VERSION ""

NS_ :

BS_:

BU_: TBOX GW

BO_ 374 EPS_0x176: 8 GW
 SG_ EPS_Checksum_0x176 : 7|8@0+ (1,0) [0|255] "" TBOX
 SG_ EPS_LKA_TJA_ResponseTorque : 18|11@0+ (0.01,-10.24) [-10.24|10.23] "Nm" TBOX
 SG_ EPS_LKA_TJA_ResponseTorqueValid : 19|1@0+ (1,0) [0|1] "" TBOX
 SG_ EPS_LKA_TJA_ControlStatus : 33|2@0+ (1,0) [0|3] "" TBOX
 SG_ Rolling_counter_0x176 : 59|4@0+ (1,0) [0|15] "" TBOX

BO_ 375 EPS_0x177_APS: 8 GW
 SG_ Checksum_0x177 : 7|8@0+ (1,0) [0|255] "" TBOX
 SG_ EPS_EPSAPASts : 19|4@0+ (1,0) [0|15] "" TBOX
 SG_ EPS_EPSAPAInh : 31|8@0+ (1,0) [0|255] "" TBOX
 SG_ Rolling_counter_0x177 : 59|4@0+ (1,0) [0|15] "" TBOX

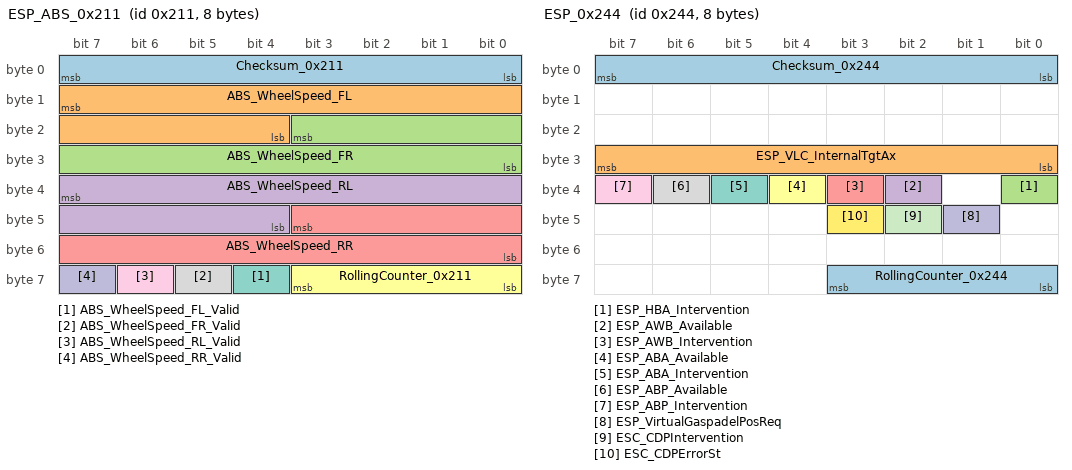
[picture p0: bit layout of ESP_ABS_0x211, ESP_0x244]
BO_ 529 ESP_ABS_0x211: 8 GW
 SG_ Checksum_0x211 : 7|8@0+ (1,0) [0|255] "" TBOX
 SG_ ABS_WheelSpeed_FL : 15|12@0+ (0.05625,0) [0|230.2875] "kph" TBOX
 SG_ ABS_WheelSpeed_FR : 19|12@0+ (0.05625,0) [0|230.2875] "kph" TBOX
 SG_ ABS_WheelSpeed_RL : 39|12@0+ (0.05625,0) [0|230.2875] "kph" TBOX
 SG_ ABS_WheelSpeed_RR : 43|12@0+ (0.05625,0) [0|230.2875] "kph" TBOX
 SG_ RollingCounter_0x211 : 59|4@0+ (1,0) [0|15] "" TBOX
 SG_ ABS_WheelSpeed_FL_Valid : 60|1@0+ (1,0) [0|1] "" TBOX
 SG_ ABS_WheelSpeed_FR_Valid : 61|1@0+ (1,0) [0|1] "" TBOX
 SG_ ABS_WheelSpeed_RL_Valid : 62|1@0+ (1,0) [0|1] "" TBOX
 SG_ ABS_WheelSpeed_RR_Valid : 63|1@0+ (1,0) [0|1] "" TBOX

BO_ 580 ESP_0x244: 8 GW
 SG_ Checksum_0x244 : 7|8@0+ (1,0) [0|255] "" TBOX
 SG_ ESP_VLC_InternalTgtAx : 31|8@0+ (0.05,-7) [-7|5.75] "m/s2" TBOX
 SG_ ESP_HBA_Intervention : 32|1@0+ (1,0) [0|1] "" TBOX
 SG_ ESP_AWB_Available : 34|1@0+ (1,0) [0|1] "" TBOX
 SG_ ESP_AWB_Intervention : 35|1@0+ (1,0) [0|1] "" TBOX
 SG_ ESP_ABA_Available : 36|1@0+ (1,0) [0|1] "" TBOX
 SG_ ESP_ABA_Intervention : 37|1@0+ (1,0) [0|1] "" TBOX
 SG_ ESP_ABP_Available : 38|1@0+ (1,0) [0|1] "" TBOX
 SG_ ESP_ABP_Intervention : 39|1@0+ (1,0) [0|1] "" TBOX
 SG_ ESP_VirtualGaspadelPosReq : 41|1@0+ (1,0) [0|1] "" TBOX
 SG_ ESC_CDPIntervention : 42|1@0+ (1,0) [0|1] "" TBOX
 SG_ ESC_CDPErrorSt : 43|1@0+ (1,0) [0|1] "" TBOX
 SG_ RollingCounter_0x244 : 59|4@0+ (1,0) [0|15] "" TBOX

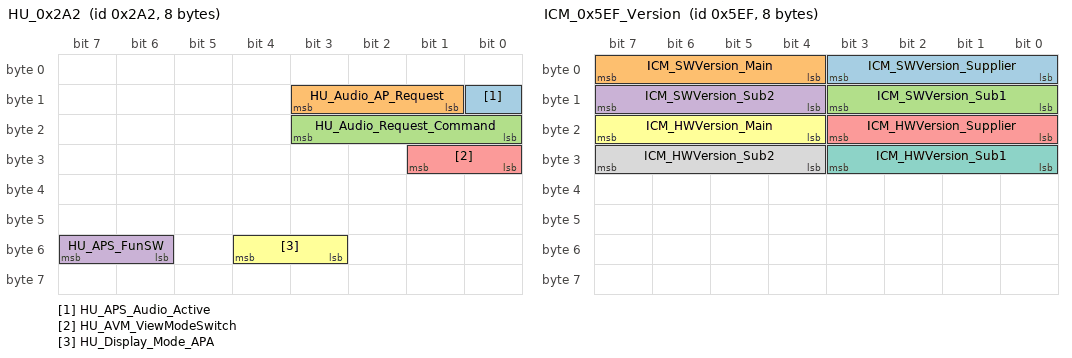
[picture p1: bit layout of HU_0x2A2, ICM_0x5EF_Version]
BO_ 674 HU_0x2A2: 8 GW
 SG_ HU_APS_Audio_Active : 8|1@0+ (1,0) [0|1] "" TBOX
 SG_ HU_Audio_AP_Request : 11|3@0+ (1,0) [0|7] "" TBOX
 SG_ HU_Audio_Request_Command : 19|4@0+ (1,0) [0|15] "" TBOX
 SG_ HU_APS_FunSW : 55|2@0+ (1,0) [0|3] "" TBOX
 SG_ HU_AVM_ViewModeSwitch : 25|2@0+ (1,0) [0|3] "" TBOX
 SG_ HU_Display_Mode_APA : 52|2@0+ (1,0) [0|3] "" TBOX

BO_ 608 EPS_0x260: 8 GW
 SG_ EPS_SafeLampRed : 0|1@0+ (1,0) [0|1] "" TBOX
 SG_ EPS_WarningLampYellow : 1|1@0+ (1,0) [0|1] "" TBOX
 SG_ EPS_DTCFlag : 2|1@0+ (1,0) [0|1] "" TBOX
 SG_ EPS_DriveModeSts : 4|2@0+ (1,0) [0|3] "" TBOX
 SG_ EPS_HU_DriveModeSetEn : 5|1@0+ (1,0) [0|1] "" TBOX

BO_ 1519 ICM_0x5EF_Version: 8 GW
 SG_ ICM_SWVersion_Supplier : 3|4@0+ (1,0) [0|15] "" TBOX
 SG_ ICM_SWVersion_Main : 7|4@0+ (1,0) [0|15] "" TBOX
 SG_ ICM_SWVersion_Sub1 : 11|4@0+ (1,0) [0|15] "" TBOX
 SG_ ICM_SWVersion_Sub2 : 15|4@0+ (1,0) [0|15] "" TBOX
 SG_ ICM_HWVersion_Supplier : 19|4@0+ (1,0) [0|15] "" TBOX
 SG_ ICM_HWVersion_Main : 23|4@0+ (1,0) [0|15] "" TBOX
 SG_ ICM_HWVersion_Sub1 : 27|4@0+ (1,0) [0|15] "" TBOX
 SG_ ICM_HWVersion_Sub2 : 31|4@0+ (1,0) [0|15] "" TBOX

BO_ 811 VBU_0x32B: 8 GW
 SG_ VBU_WakeUpRMCU : 7|1@0+ (1,0) [0|1] "" TBOX

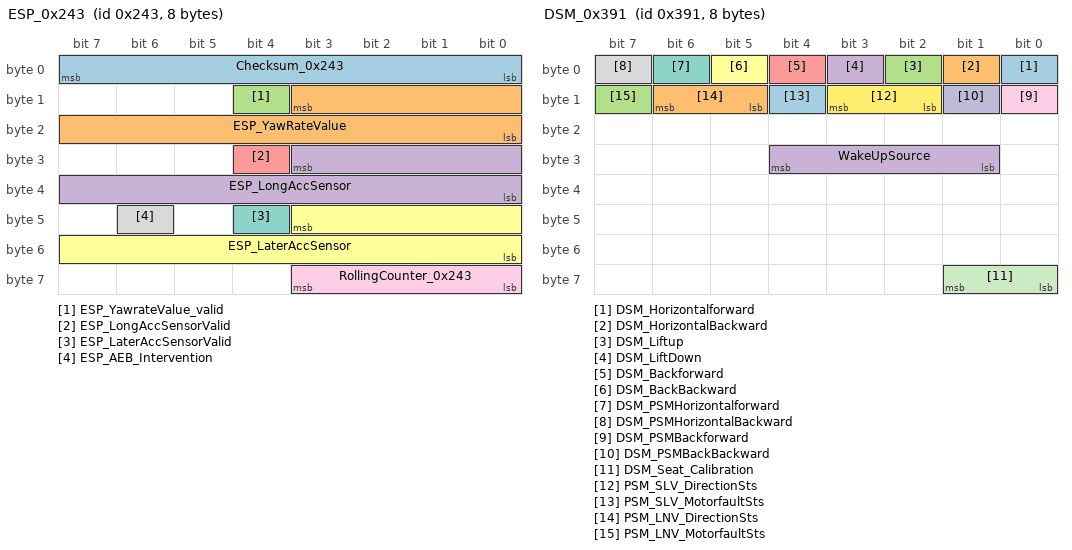
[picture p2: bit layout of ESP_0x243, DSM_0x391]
BO_ 579 ESP_0x243: 8 GW
 SG_ Checksum_0x243 : 7|8@0+ (1,0) [0|255] "" TBOX
 SG_ ESP_YawRateValue : 11|12@0+ (0.05,-75) [-75|75] "degps" TBOX
 SG_ ESP_YawrateValue_valid : 12|1@0+ (1,0) [0|1] "" TBOX
 SG_ ESP_LongAccSensor : 27|12@0+ (0.01,-20) [-20|20] "gee" TBOX
 SG_ ESP_LongAccSensorValid : 28|1@0+ (1,0) [0|1] "" TBOX
 SG_ ESP_LaterAccSensor : 43|12@0+ (0.01,-20) [-20|20] "gee" TBOX
 SG_ ESP_LaterAccSensorValid : 44|1@0+ (1,0) [0|1] "" TBOX
 SG_ ESP_AEB_Intervention : 46|1@0+ (1,0) [0|1] "" TBOX
 SG_ RollingCounter_0x243 : 59|4@0+ (1,0) [0|15] "" TBOX

BO_ 913 DSM_0x391: 8 GW
 SG_ DSM_Horizontalforward : 0|1@0+ (1,0) [0|1] "" TBOX
 SG_ DSM_HorizontalBackward : 1|1@0+ (1,0) [0|1] "" TBOX
 SG_ DSM_Liftup : 2|1@0+ (1,0) [0|1] "" TBOX
 SG_ DSM_LiftDown : 3|1@0+ (1,0) [0|1] "" TBOX
 SG_ DSM_Backforward : 4|1@0+ (1,0) [0|1] "" TBOX
 SG_ DSM_BackBackward : 5|1@0+ (1,0) [0|1] "" TBOX
 SG_ DSM_PSMHorizontalforward : 6|1@0+ (1,0) [0|1] "" TBOX
 SG_ DSM_PSMHorizontalBackward : 7|1@0+ (1,0) [0|1] "" TBOX
 SG_ DSM_PSMBackforward : 8|1@0+ (1,0) [0|1] "" TBOX
 SG_ DSM_PSMBackBackward : 9|1@0+ (1,0) [0|1] "" TBOX
 SG_ DSM_Seat_Calibration : 57|2@0+ (1,0) [0|3] "" TBOX
 SG_ PSM_SLV_DirectionSts : 11|2@0+ (1,0) [0|3] "" TBOX
 SG_ PSM_SLV_MotorfaultSts : 12|1@0+ (1,0) [0|1] "" TBOX
 SG_ PSM_LNV_DirectionSts : 14|2@0+ (1,0) [0|3] "" TBOX
 SG_ PSM_LNV_MotorfaultSts : 15|1@0+ (1,0) [0|1] "" TBOX
 SG_ WakeUpSource : 28|4@0+ (1,0) [0|15] "" TBOX

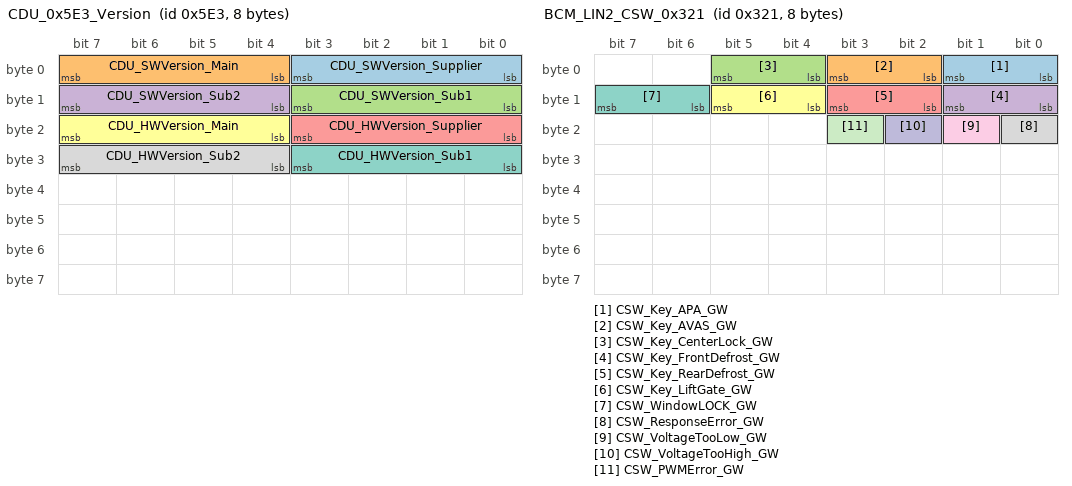
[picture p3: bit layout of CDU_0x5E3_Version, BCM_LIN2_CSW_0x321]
BO_ 1507 CDU_0x5E3_Version: 8 GW
 SG_ CDU_SWVersion_Supplier : 3|4@0+ (1,0) [0|15] "" TBOX
 SG_ CDU_SWVersion_Main : 7|4@0+ (1,0) [0|15] "" TBOX
 SG_ CDU_SWVersion_Sub1 : 11|4@0+ (1,0) [0|15] "" TBOX
 SG_ CDU_SWVersion_Sub2 : 15|4@0+ (1,0) [0|15] "" TBOX
 SG_ CDU_HWVersion_Supplier : 19|4@0+ (1,0) [0|15] "" TBOX
 SG_ CDU_HWVersion_Main : 23|4@0+ (1,0) [0|15] "" TBOX
 SG_ CDU_HWVersion_Sub1 : 27|4@0+ (1,0) [0|15] "" TBOX
 SG_ CDU_HWVersion_Sub2 : 31|4@0+ (1,0) [0|15] "" TBOX

BO_ 801 BCM_LIN2_CSW_0x321: 8 GW
 SG_ CSW_Key_APA_GW : 1|2@0+ (1,0) [0|3] "" TBOX
 SG_ CSW_Key_AVAS_GW : 3|2@0+ (1,0) [0|3] "" TBOX
 SG_ CSW_Key_CenterLock_GW : 5|2@0+ (1,0) [0|3] "" TBOX
 SG_ CSW_Key_FrontDefrost_GW : 9|2@0+ (1,0) [0|3] "" TBOX
 SG_ CSW_Key_RearDefrost_GW : 11|2@0+ (1,0) [0|3] "" TBOX
 SG_ CSW_Key_LiftGate_GW : 13|2@0+ (1,0) [0|3] "" TBOX
 SG_ CSW_WindowLOCK_GW : 15|2@0+ (1,0) [0|3] "" TBOX
 SG_ CSW_ResponseError_GW : 16|1@0+ (1,0) [0|1] "" TBOX
 SG_ CSW_VoltageTooLow_GW : 17|1@0+ (1,0) [0|1] "" TBOX
 SG_ CSW_VoltageTooHigh_GW : 18|1@0+ (1,0) [0|1] "" TBOX
 SG_ CSW_PWMError_GW : 19|1@0+ (1,0) [0|1] "" TBOX

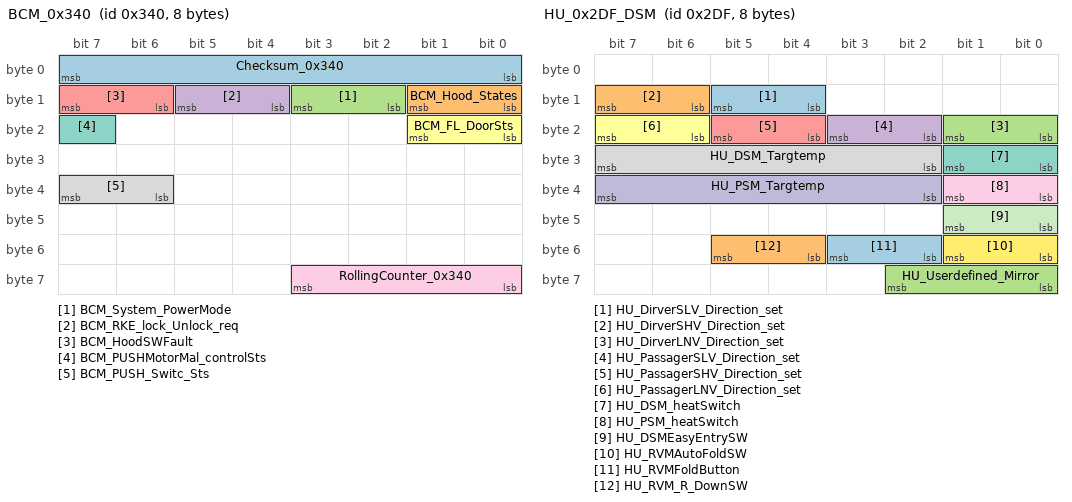
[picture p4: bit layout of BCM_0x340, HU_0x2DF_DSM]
BO_ 832 BCM_0x340: 8 GW
 SG_ Checksum_0x340 : 7|8@0+ (1,0) [0|255] "" TBOX
 SG_ BCM_Hood_States : 9|2@0+ (1,0) [0|3] "" TBOX
 SG_ BCM_System_PowerMode : 11|2@0+ (1,0) [0|3] "" TBOX
 SG_ BCM_RKE_lock_Unlock_req : 13|2@0+ (1,0) [0|3] "" TBOX
 SG_ BCM_HoodSWFault : 15|2@0+ (1,0) [0|3] "" TBOX
 SG_ BCM_FL_DoorSts : 17|2@0+ (1,0) [0|3] "" TBOX
 SG_ BCM_PUSHMotorMal_controlSts : 23|1@0+ (1,0) [0|1] "" TBOX
 SG_ BCM_PUSH_Switc_Sts : 39|2@0+ (1,0) [0|3] "" TBOX
 SG_ RollingCounter_0x340 : 59|4@0+ (1,0) [0|15] "" TBOX

BO_ 64 BCM_PEPS_0x40: 8 GW
 SG_ PEPS_RKECommand : 3|4@0+ (1,0) [0|15] "" TBOX
 SG_ PEPS_TrunkReleaseReq : 4|1@0+ (1,0) [0|1] "" TBOX
 SG_ PEPS_DoorUnlockReq : 6|2@0+ (1,0) [0|3] "" TBOX
 SG_ PEPS_DoorlockReq : 9|2@0+ (1,0) [0|3] "" TBOX

BO_ 735 HU_0x2DF_DSM: 8 GW
 SG_ HU_DirverSLV_Direction_set : 13|2@0+ (1,0) [0|3] "" TBOX
 SG_ HU_DirverSHV_Direction_set : 15|2@0+ (1,0) [0|3] "" TBOX
 SG_ HU_DirverLNV_Direction_set : 17|2@0+ (1,0) [0|3] "" TBOX
 SG_ HU_PassagerSLV_Direction_set : 19|2@0+ (1,0) [0|3] "" TBOX
 SG_ HU_PassagerSHV_Direction_set : 21|2@0+ (1,0) [0|3] "" TBOX
 SG_ HU_PassagerLNV_Direction_set : 23|2@0+ (1,0) [0|3] "" TBOX
 SG_ HU_DSM_heatSwitch : 25|2@0+ (1,0) [0|3] "" TBOX
 SG_ HU_DSM_Targtemp : 31|6@0+ (1,0) [34|42] "℃" TBOX
 SG_ HU_PSM_heatSwitch : 33|2@0+ (1,0) [0|3] "" TBOX
 SG_ HU_PSM_Targtemp : 39|6@0+ (1,0) [34|42] "℃" TBOX
 SG_ HU_DSMEasyEntrySW : 41|2@0+ (1,0) [0|3] "" TBOX
 SG_ HU_RVMAutoFoldSW : 49|2@0+ (1,0) [0|3] "" TBOX
 SG_ HU_RVMFoldButton : 51|2@0+ (1,0) [0|3] "" TBOX
 SG_ HU_RVM_R_DownSW : 53|2@0+ (1,0) [0|3] "" TBOX
 SG_ HU_Userdefined_Mirror : 58|3@0+ (1,0) [0|7] "" TBOX

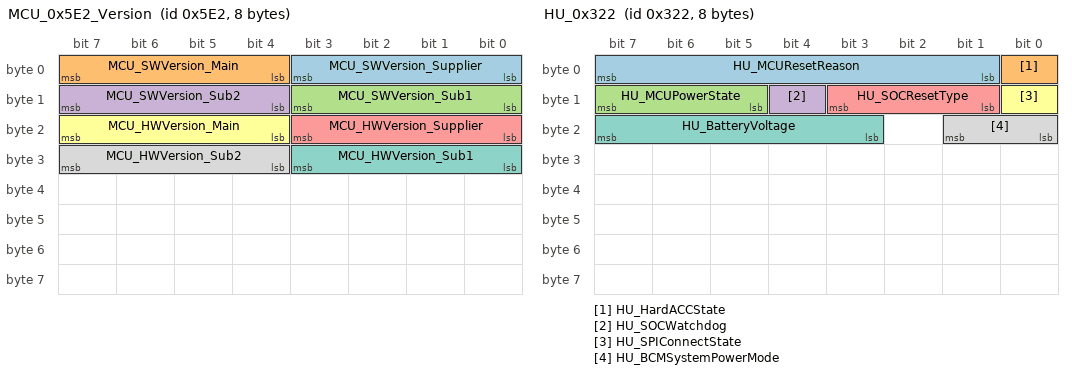
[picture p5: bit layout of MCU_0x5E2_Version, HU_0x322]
BO_ 1506 MCU_0x5E2_Version: 8 GW
 SG_ MCU_SWVersion_Supplier : 3|4@0+ (1,0) [0|15] "" TBOX
 SG_ MCU_SWVersion_Main : 7|4@0+ (1,0) [0|15] "" TBOX
 SG_ MCU_SWVersion_Sub1 : 11|4@0+ (1,0) [0|15] "" TBOX
 SG_ MCU_SWVersion_Sub2 : 15|4@0+ (1,0) [0|15] "" TBOX
 SG_ MCU_HWVersion_Supplier : 19|4@0+ (1,0) [0|15] "" TBOX
 SG_ MCU_HWVersion_Main : 23|4@0+ (1,0) [0|15] "" TBOX
 SG_ MCU_HWVersion_Sub1 : 27|4@0+ (1,0) [0|15] "" TBOX
 SG_ MCU_HWVersion_Sub2 : 31|4@0+ (1,0) [0|15] "" TBOX

BO_ 802 HU_0x322: 8 GW
 SG_ HU_MCUResetReason : 7|7@0+ (1,0) [0|127] "" TBOX
 SG_ HU_HardACCState : 0|1@0+ (1,0) [0|1] "" TBOX
 SG_ HU_MCUPowerState : 15|3@0+ (1,0) [0|7] "" TBOX
 SG_ HU_SOCWatchdog : 12|1@0+ (1,0) [0|1] "" TBOX
 SG_ HU_SOCResetType : 11|3@0+ (1,0) [0|3] "" TBOX
 SG_ HU_SPIConnectState : 8|1@0+ (1,0) [0|1] "" TBOX
 SG_ HU_BatteryVoltage : 23|5@0+ (1,0) [0|25] "V" TBOX
 SG_ HU_BCMSystemPowerMode : 17|2@0+ (1,0) [0|3] "" TBOX

BO_ 792 TPCV1_0x318: 8 GW
 SG_ TPCV1_Feedback_sts : 1|2@0+ (1,0) [0|3] "" TBOX
 SG_ TPCV1_Feedback_opening_sts : 7|6@0+ (2.5,0) [0|100] "" TBOX

BO_ 793 TPCV2_0x319: 8 GW
 SG_ TPCV2_Feedback_sts : 17|2@0+ (1,0) [0|3] "" TBOX
 SG_ TPCV2_Feedback_opening_Sts : 23|6@0+ (2.5,0) [0|100] "" TBOX

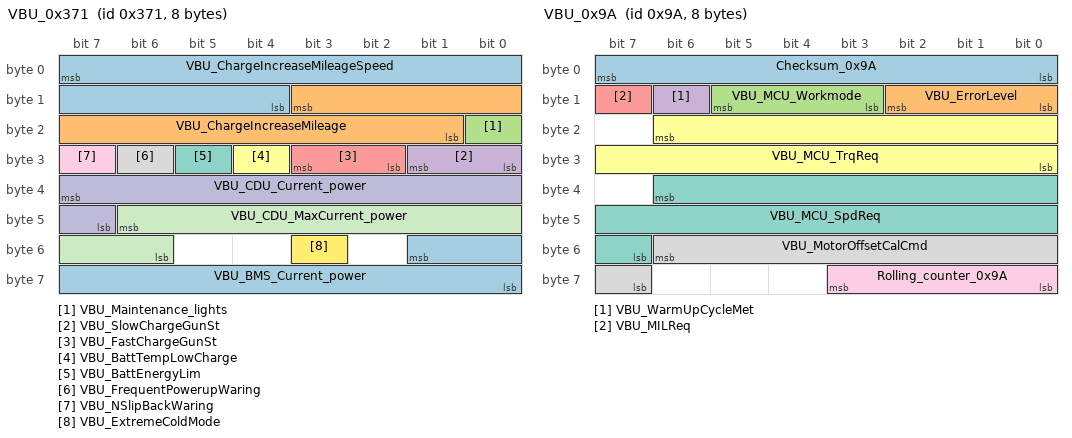
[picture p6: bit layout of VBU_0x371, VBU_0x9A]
BO_ 881 VBU_0x371: 8 GW
 SG_ VBU_ChargeIncreaseMileageSpeed : 7|12@0+ (1,0) [0|2046] "kmph" TBOX
 SG_ VBU_ChargeIncreaseMileage : 11|11@0+ (1,0) [0|2046] "km" TBOX
 SG_ VBU_Maintenance_lights : 16|1@0+ (1,0) [0|1] "" TBOX
 SG_ VBU_SlowChargeGunSt : 25|2@0+ (1,0) [0|3] "" TBOX
 SG_ VBU_FastChargeGunSt : 27|2@0+ (1,0) [0|3] "" TBOX
 SG_ VBU_BattTempLowCharge : 28|1@0+ (1,0) [0|1] "" TBOX
 SG_ VBU_BattEnergyLim : 29|1@0+ (1,0) [0|1] "" TBOX
 SG_ VBU_FrequentPowerupWaring : 30|1@0+ (1,0) [0|1] "" TBOX
 SG_ VBU_NSlipBackWaring : 31|1@0+ (1,0) [0|1] "" TBOX
 SG_ VBU_CDU_Current_power : 39|9@0+ (20,0) [0|7000] "W" TBOX
 SG_ VBU_CDU_MaxCurrent_power : 46|9@0+ (20,0) [0|7000] "W" TBOX
 SG_ VBU_ExtremeColdMode : 51|1@0+ (1,0) [0|1] "" TBOX
 SG_ VBU_BMS_Current_power : 49|10@0+ (0.5,-250) [-250|250] "kW" TBOX

BO_ 154 VBU_0x9A: 8 GW
 SG_ Checksum_0x9A : 7|8@0+ (1,0) [0|255] "" TBOX
 SG_ VBU_ErrorLevel : 10|3@0+ (1,0) [0|7] "" TBOX
 SG_ VBU_MCU_Workmode : 13|3@0+ (1,0) [0|7] "" TBOX
 SG_ VBU_WarmUpCycleMet : 14|1@0+ (1,0) [0|1] "" TBOX
 SG_ VBU_MILReq : 15|1@0+ (1,0) [0|1] "" TBOX
 SG_ VBU_MCU_TrqReq : 22|15@0+ (0.1,-1000) [-1000|1000] "NM" TBOX
 SG_ VBU_MCU_SpdReq : 38|16@0+ (1,-32767) [-32767|32768] "rpm" TBOX
 SG_ VBU_MotorOffsetCalCmd : 54|8@0+ (1,0) [0|255] "" TBOX
 SG_ Rolling_counter_0x9A : 59|4@0+ (1,0) [0|15] "" TBOX

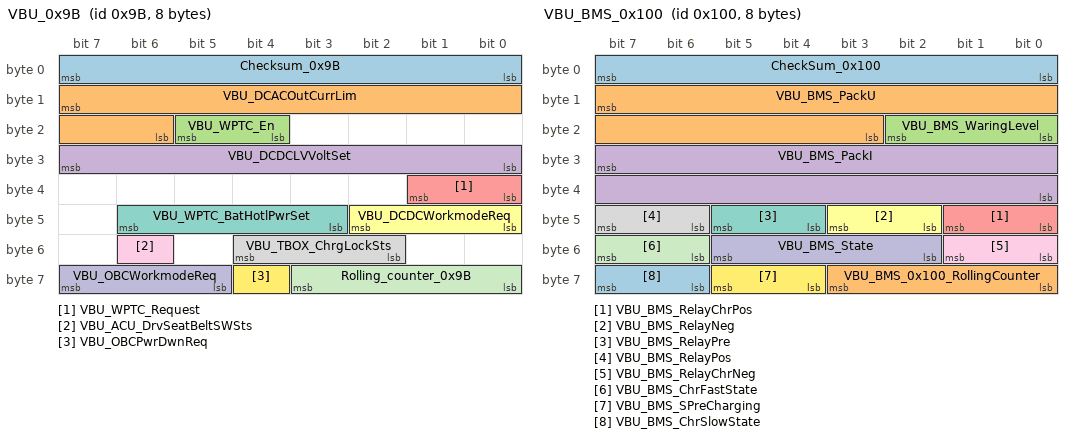
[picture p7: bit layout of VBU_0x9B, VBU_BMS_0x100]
BO_ 155 VBU_0x9B: 8 GW
 SG_ Checksum_0x9B : 7|8@0+ (1,0) [0|255] "" TBOX
 SG_ VBU_DCACOutCurrLim : 15|10@0+ (0.1,0) [0|100] "A" TBOX
 SG_ VBU_WPTC_En : 21|2@0+ (1,0) [0|3] "" TBOX
 SG_ VBU_DCDCLVVoltSet : 31|8@0+ (0.1,0) [12|16] "V" TBOX
 SG_ VBU_WPTC_Request : 33|2@0+ (1,0) [0|3] "" TBOX
 SG_ VBU_DCDCWorkmodeReq : 42|3@0+ (1,0) [0|7] "" TBOX
 SG_ VBU_WPTC_BatHotlPwrSet : 46|4@0+ (1,0) [0|15] "" TBOX
 SG_ VBU_TBOX_ChrgLockSts : 52|3@0+ (1,0) [0|7] "" TBOX
 SG_ VBU_ACU_DrvSeatBeltSWSts : 54|1@0+ (1,0) [0|1] "" TBOX
 SG_ VBU_OBCWorkmodeReq : 63|3@0+ (1,0) [0|7] "" TBOX
 SG_ Rolling_counter_0x9B : 59|4@0+ (1,0) [0|15] "" TBOX
 SG_ VBU_OBCPwrDwnReq : 60|1@0+ (1,0) [0|1] "" TBOX

BO_ 156 VBU_0x9C: 8 GW
 SG_ Checksum_0x9C : 7|8@0+ (1,0) [0|255] "" TBOX
 SG_ VBU_Cruise_Sts : 9|2@0+ (1,0) [0|3] "" TBOX
 SG_ VBU_DriveInhibitAlarm : 10|1@0+ (1,0) [0|1] "" TBOX
 SG_ VBU_HU_ChrgLockSts : 15|3@0+ (1,0) [0|7] "" TBOX
 SG_ VBU_CCS_SpeedArm : 23|8@0+ (1,0) [0|200] "kmph" TBOX
 SG_ VBU_SpeedLimitSWSts : 25|1@0+ (1,0) [0|1] "" TBOX
 SG_ VBU_DMS_Status : 27|2@0+ (1,0) [0|3] "" TBOX
 SG_ VBU_DMS_SWStatus : 28|1@0+ (1,0) [0|1] "" TBOX
 SG_ VBU_IdleModeAct : 29|1@0+ (1,0) [0|1] "" TBOX
 SG_ VBU_AuthSts : 31|2@0+ (1,0) [0|3] "" TBOX
 SG_ VBU_LimitSpeed : 39|8@0+ (1,0) [0|200] "" TBOX
 SG_ VBU_LimitSpeedAlarm_L : 40|1@0+ (1,0) [0|1] "" TBOX
 SG_ VBU_LimitSpeedAlarm_V : 41|1@0+ (1,0) [0|1] "" TBOX
 SG_ VBU_TPCV1Control : 47|6@0+ (2.5,0) [0|100] "" TBOX
 SG_ VBU_Cruise_Warning : 49|2@0+ (1,0) [0|3] "" TBOX
 SG_ VBU_TPCV2Control : 55|6@0+ (2.5,0) [0|100] "" TBOX
 SG_ Rolling_counter_0x9C : 59|4@0+ (1,0) [0|15] "" TBOX
 SG_ VBU_ElockSts : 63|4@0+ (1,0) [0|15] "" TBOX

BO_ 157 VBU_0x9D: 8 GW
 SG_ VBU_AC_ComfortEAC_En : 0|1@0+ (1,0) [0|1] "" TBOX
 SG_ VBU_AC_BatCoolEAC_En : 1|1@0+ (1,0) [0|1] "" TBOX
 SG_ VBU_AC_APTC_En : 2|1@0+ (1,0) [0|1] "" TBOX
 SG_ VBU_RefuelingInfo : 5|3@0+ (1,0) [0|7] "" TBOX
 SG_ VBU_HU_Towmode : 6|1@0+ (1,0) [0|1] "" TBOX
 SG_ VBU_HU_TowmodeSetEn : 7|1@0+ (1,0) [0|1] "" TBOX
 SG_ VBU_AC_APTCPwrSet : 14|7@0+ (0.1,0) [0|12.7] "kW" TBOX
 SG_ VBU_BCM_TowModewarning : 15|1@0+ (1,0) [0|1] "" TBOX
 SG_ VBU_AC_EACPwrSet : 22|7@0+ (0.1,0) [0|12.7] "kW" TBOX
 SG_ VBU_FanPWMSts : 30|7@0+ (1,0) [0|100] "percent" TBOX
 SG_ VBU_RemoteACFeedback : 38|4@0+ (1,0) [0|15] "" TBOX
 SG_ VBU_ComfortPumpError : 40|1@0+ (1,0) [0|1] "" TBOX
 SG_ VBU_ENGWVControl : 41|1@0+ (1,0) [0|1] "" TBOX
 SG_ VBU_WPTCWVControl : 42|1@0+ (1,0) [0|1] "" TBOX
 SG_ VBU_ENGWVFault : 43|1@0+ (1,0) [0|1] "" TBOX
 SG_ VBU_WPTCWVFault : 44|1@0+ (1,0) [0|1] "" TBOX
 SG_ VBU_FanSts : 45|1@0+ (1,0) [0|1] "" TBOX
 SG_ VBU_RefuelingSysErrorRemind : 47|1@0+ (1,0) [0|1] "" TBOX
 SG_ VBU_12VbatterySOHLow : 48|1@0+ (1,0) [0|1] "" TBOX
 SG_ VBU_LVSmartChrg_Status : 50|2@0+ (1,0) [0|3] "" TBOX
 SG_ VBU_ChargeLight : 54|4@0+ (1,0) [0|15] "" TBOX
 SG_ VBU_AC_ThermalReqLvl : 62|4@0+ (1,0) [0|15] "" TBOX
 SG_ VBU_VehicleModel : 58|3@0+ (1,0) [0|7] "" TBOX

BO_ 256 VBU_BMS_0x100: 8 GW
 SG_ CheckSum_0x100 : 7|8@0+ (1,0) [0|255] "" TBOX
 SG_ VBU_BMS_PackU : 15|13@0+ (0.1,0) [0|800] "V" TBOX
 SG_ VBU_BMS_WaringLevel : 18|3@0+ (1,0) [0|7] "" TBOX
 SG_ VBU_BMS_PackI : 31|16@0+ (0.1,-1000) [-1000|1000] "A" TBOX
 SG_ VBU_BMS_RelayChrPos : 41|2@0+ (1,0) [0|3] "" TBOX
 SG_ VBU_BMS_RelayNeg : 43|2@0+ (1,0) [0|3] "" TBOX
 SG_ VBU_BMS_RelayPre : 45|2@0+ (1,0) [0|3] "" TBOX
 SG_ VBU_BMS_RelayPos : 47|2@0+ (1,0) [0|3] "" TBOX
 SG_ VBU_BMS_RelayChrNeg : 49|2@0+ (1,0) [0|3] "" TBOX
 SG_ VBU_BMS_State : 53|4@0+ (1,0) [0|15] "" TBOX
 SG_ VBU_BMS_ChrFastState : 55|2@0+ (1,0) [0|3] "" TBOX
 SG_ VBU_BMS_SPreCharging : 61|2@0+ (1,0) [0|3] "" TBOX
 SG_ VBU_BMS_ChrSlowState : 63|2@0+ (1,0) [0|3] "" TBOX
 SG_ VBU_BMS_0x100_RollingCounter : 59|4@0+ (1,0) [0|15] "" TBOX

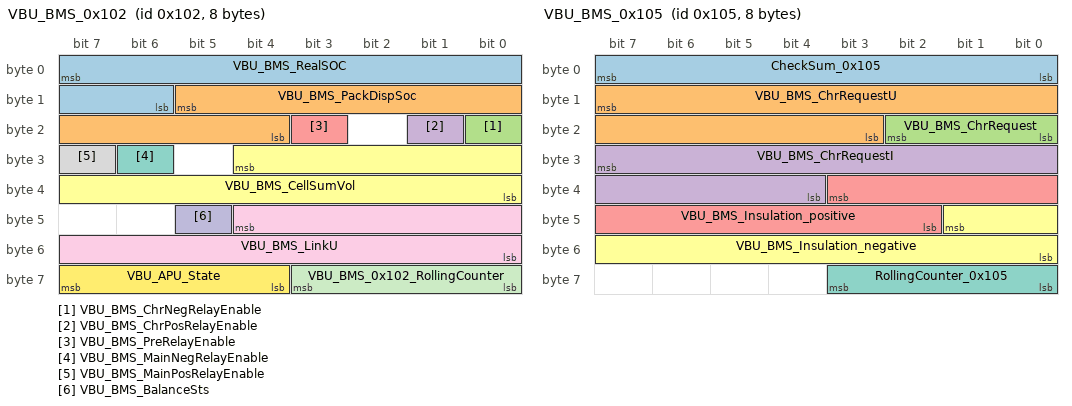
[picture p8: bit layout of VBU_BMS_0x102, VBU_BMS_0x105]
BO_ 258 VBU_BMS_0x102: 8 GW
 SG_ VBU_BMS_RealSOC : 7|10@0+ (0.1,0) [0|100] "percent" TBOX
 SG_ VBU_BMS_PackDispSoc : 13|10@0+ (0.1,0) [0|100] "percent" TBOX
 SG_ VBU_BMS_ChrNegRelayEnable : 16|1@0+ (1,0) [0|1] "" TBOX
 SG_ VBU_BMS_ChrPosRelayEnable : 17|1@0+ (1,0) [0|1] "" TBOX
 SG_ VBU_BMS_PreRelayEnable : 19|1@0+ (1,0) [0|1] "" TBOX
 SG_ VBU_BMS_CellSumVol : 28|13@0+ (0.1,0) [0|800] "V" TBOX
 SG_ VBU_BMS_MainNegRelayEnable : 30|1@0+ (1,0) [0|1] "" TBOX
 SG_ VBU_BMS_MainPosRelayEnable : 31|1@0+ (1,0) [0|1] "" TBOX
 SG_ VBU_BMS_LinkU : 44|13@0+ (0.1,0) [0|800] "V" TBOX
 SG_ VBU_BMS_BalanceSts : 45|1@0+ (1,0) [0|1] "" TBOX
 SG_ VBU_BMS_0x102_RollingCounter : 59|4@0+ (1,0) [0|15] "" TBOX
 SG_ VBU_APU_State : 63|4@0+ (1,0) [0|15] "" TBOX

BO_ 261 VBU_BMS_0x105: 8 GW
 SG_ CheckSum_0x105 : 7|8@0+ (1,0) [0|255] "" TBOX
 SG_ VBU_BMS_ChrRequestU : 15|13@0+ (0.1,0) [0|800] "V" TBOX
 SG_ VBU_BMS_ChrRequest : 18|3@0+ (1,0) [0|7] "" TBOX
 SG_ VBU_BMS_ChrRequestI : 31|12@0+ (0.1,0) [0|400] "A" TBOX
 SG_ VBU_BMS_Insulation_positive : 35|10@0+ (1,0) [0|1023] "kOhm" TBOX
 SG_ VBU_BMS_Insulation_negative : 41|10@0+ (1,0) [0|1023] "kOhm" TBOX
 SG_ RollingCounter_0x105 : 59|4@0+ (1,0) [0|15] "" TBOX

BO_ 274 VBU_BMS_0x112: 8 GW
 SG_ VBU_BMS_MaxCellNo : 7|8@0+ (1,0) [0|255] "" TBOX
 SG_ VBU_BMS_MaxCellU : 15|13@0+ (1,0) [0|5000] "mV" TBOX
 SG_ VBU_BMS_MinCellNo : 31|8@0+ (1,0) [0|255] "" TBOX
 SG_ VBU_BMS_MinCellU : 39|13@0+ (1,0) [0|5000] "mV" TBOX
 SG_ VBU_BMS_CellVolDev : 55|12@0+ (1,0) [0|4000] "mV" TBOX
 SG_ VBU_BMS_0x112_RollingCounter : 59|4@0+ (1,0) [0|15] "" TBOX

BO_ 277 VBU_BMS_0x115: 8 GW
 SG_ VBU_BMS_MaxDschPowerPeak : 13|10@0+ (0.25,0) [0|250] "kW" TBOX
 SG_ VBU_BMS_DschAllowedPower : 19|10@0+ (0.25,0) [0|250] "kW" TBOX
 SG_ VBU_BMS_MaxChrgPowerPeak : 25|10@0+ (0.25,0) [0|250] "kW" TBOX
 SG_ VBU_BMS_ChrgAllowedPower : 53|10@0+ (0.25,0) [0|250] "kW" TBOX
 SG_ VBU_BMS_0x115_RollingCounter : 59|4@0+ (1,0) [0|15] "" TBOX

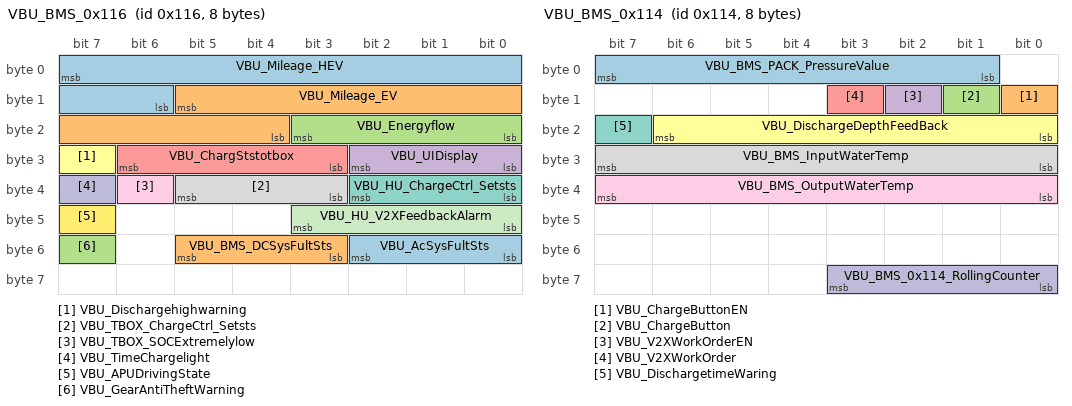
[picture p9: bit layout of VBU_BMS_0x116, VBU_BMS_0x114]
BO_ 278 VBU_BMS_0x116: 8 GW
 SG_ VBU_Mileage_HEV : 7|10@0+ (1,0) [0|1022] "km" TBOX
 SG_ VBU_Mileage_EV : 13|10@0+ (1,0) [0|1022] "km" TBOX
 SG_ VBU_Energyflow : 19|4@0+ (1,0) [0|15] "" TBOX
 SG_ VBU_UIDisplay : 26|3@0+ (1,0) [0|7] "" TBOX
 SG_ VBU_ChargStstotbox : 30|4@0+ (1,0) [0|15] "" TBOX
 SG_ VBU_Dischargehighwarning : 31|1@0+ (1,0) [0|1] "" TBOX
 SG_ VBU_HU_ChargeCtrl_Setsts : 34|3@0+ (1,0) [0|7] "" TBOX
 SG_ VBU_TBOX_ChargeCtrl_Setsts : 37|3@0+ (1,0) [0|7] "" TBOX
 SG_ VBU_TBOX_SOCExtremelylow : 38|1@0+ (1,0) [0|1] "" TBOX
 SG_ VBU_TimeChargelight : 39|1@0+ (1,0) [0|1] "" TBOX
 SG_ VBU_HU_V2XFeedbackAlarm : 43|4@0+ (1,0) [0|15] "" TBOX
 SG_ VBU_APUDrivingState : 47|1@0+ (1,0) [0|1] "" TBOX
 SG_ VBU_AcSysFultSts : 50|3@0+ (1,0) [0|7] "" TBOX
 SG_ VBU_BMS_DCSysFultSts : 53|3@0+ (1,0) [0|7] "" TBOX
 SG_ VBU_GearAntiTheftWarning : 55|1@0+ (1,0) [0|1] "" TBOX

BO_ 276 VBU_BMS_0x114: 8 GW
 SG_ VBU_BMS_PACK_PressureValue : 7|7@0+ (1,50) [50|175] "Kpa" TBOX
 SG_ VBU_ChargeButtonEN : 8|1@0+ (1,0) [0|1] "" TBOX
 SG_ VBU_ChargeButton : 9|1@0+ (1,0) [0|1] "" TBOX
 SG_ VBU_V2XWorkOrderEN : 10|1@0+ (1,0) [0|1] "" TBOX
 SG_ VBU_V2XWorkOrder : 11|1@0+ (1,0) [0|1] "" TBOX
 SG_ VBU_DischargeDepthFeedBack : 22|7@0+ (1,0) [0|100] "" TBOX
 SG_ VBU_DischargetimeWaring : 23|1@0+ (1,0) [0|1] "" TBOX
 SG_ VBU_BMS_InputWaterTemp : 31|8@0+ (0.5,-40) [-40|85] "degC" TBOX
 SG_ VBU_BMS_OutputWaterTemp : 39|8@0+ (0.5,-40) [-40|85] "degC" TBOX
 SG_ VBU_BMS_0x114_RollingCounter : 59|4@0+ (1,0) [0|15] "" TBOX

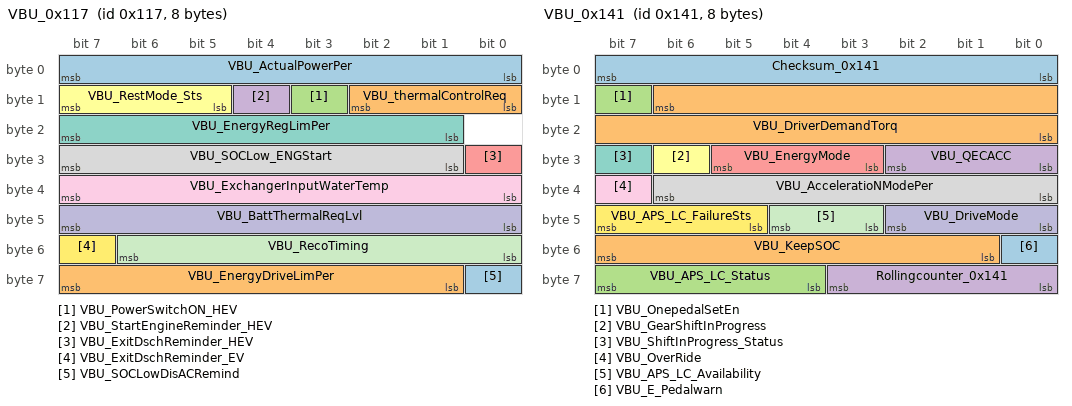
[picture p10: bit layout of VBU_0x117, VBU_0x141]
BO_ 279 VBU_0x117: 8 GW
 SG_ VBU_ActualPowerPer : 7|8@0+ (1,-100) [-100|100] "" TBOX
 SG_ VBU_thermalControlReq : 10|3@0+ (1,0) [0|7] "" TBOX
 SG_ VBU_PowerSwitchON_HEV : 11|1@0+ (1,0) [0|1] "" TBOX
 SG_ VBU_StartEngineReminder_HEV : 12|1@0+ (1,0) [0|1] "" TBOX
 SG_ VBU_ExitDschReminder_HEV : 24|1@0+ (1,0) [0|1] "" TBOX
 SG_ VBU_RestMode_Sts : 15|3@0+ (1,0) [0|7] "" TBOX
 SG_ VBU_EnergyRegLimPer : 23|7@0+ (1,0) [0|100] "" TBOX
 SG_ VBU_SOCLow_ENGStart : 31|7@0+ (1,0) [0|100] "percent" TBOX
 SG_ VBU_ExchangerInputWaterTemp : 39|8@0+ (1,-40) [-40|215] "degC" TBOX
 SG_ VBU_BattThermalReqLvl : 47|8@0+ (1,0) [0|15] "" TBOX
 SG_ VBU_RecoTiming : 54|7@0+ (1,0) [0|120] "" TBOX
 SG_ VBU_ExitDschReminder_EV : 55|1@0+ (1,0) [0|1] "" TBOX
 SG_ VBU_SOCLowDisACRemind : 56|1@0+ (1,0) [0|1] "" TBOX
 SG_ VBU_EnergyDriveLimPer : 63|7@0+ (1,0) [0|100] "" TBOX

BO_ 1441 ICM_0x5A1: 8 GW
 SG_ ICM_DST_EV : 7|12@0+ (1,0) [0|4095] "km" TBOX
 SG_ ICM_SigPowerConsumption : 23|9@0+ (0.1,0) [0|51.1] "kwh/100km" TBOX
 SG_ ICM_SigMileagetime_EV : 30|15@0+ (1,0) [0|32767] "min" TBOX
 SG_ ICM_ODOTotal_EV : 47|24@0+ (1,0) [0|999999] "km" TBOX

BO_ 1442 ICM_0x5A2: 8 GW
 SG_ ICM_DST_EREV : 7|12@0+ (1,0) [0|4095] "km" TBOX
 SG_ ICM_Sigfueleconomy : 23|9@0+ (0.1,0) [0|51.1] "" TBOX
 SG_ ICM_SigMileagetime_EREV : 30|15@0+ (1,0) [0|32767] "min" TBOX
 SG_ ICM_ODOTotal_EREV : 47|24@0+ (1,0) [0|999999] "km" TBOX

BO_ 1443 ICM_0x5A3: 8 GW
 SG_ ICM_trip_EV : 7|12@0+ (3,0) [0|9999] "km" TBOX
 SG_ ICM_trip_EREV : 11|12@0+ (3,0) [0|9999] "km" TBOX
 SG_ ICM_tripPowerConsumption : 31|9@0+ (0.1,0) [0|51.1] "kwh/100km" TBOX
 SG_ ICM_tripfueleconomy : 47|9@0+ (0.1,0) [0|51.1] "" TBOX

BO_ 1444 ICM_0x5A4: 8 GW
 SG_ ICM_TotalAverfueleconomy : 7|9@0+ (0.1,0) [0|51.1] "" TBOX
 SG_ ICM_TotalAverEnergy : 23|9@0+ (0.1,0) [0|51.1] "kwh/100km" TBOX
 SG_ ICM_TotalTime_ALL : 39|20@0+ (1,0) [0|999999] "hour" TBOX

BO_ 1445 ICM_0x5A5: 8 GW
 SG_ ICM_triptime_EV : 7|10@0+ (1,0) [0|999] "hour" TBOX
 SG_ ICM_triptime_EREV : 9|10@0+ (1,0) [0|999] "hour" TBOX
 SG_ ICM_TotalTime_EREV : 31|20@0+ (1,0) [0|999999] "hour" TBOX
 SG_ ICM_TotalTime_EV : 43|20@0+ (1,0) [0|999999] "hour" TBOX

BO_ 320 VBU_0x140: 8 GW
 SG_ Checksum_0x140 : 7|8@0+ (1,0) [0|255] "" TBOX
 SG_ VBU_CurrentMotorTorq : 14|15@0+ (0.1,-1000) [-1000|1000] "NM" TBOX
 SG_ VBU_MaxMotorTorque : 30|15@0+ (0.1,-1000) [-1000|1000] "NM" TBOX
 SG_ VBU_MiNMotorTorque : 46|15@0+ (0.1,-1000) [-1000|1000] "NM" TBOX
 SG_ Rollingcounter_0x140 : 59|4@0+ (1,0) [0|15] "" TBOX

BO_ 321 VBU_0x141: 8 GW
 SG_ Checksum_0x141 : 7|8@0+ (1,0) [0|255] "" TBOX
 SG_ VBU_DriverDemandTorq : 14|15@0+ (0.1,-1000) [-1000|1000] "NM" TBOX
 SG_ VBU_OnepedalSetEn : 15|1@0+ (1,0) [0|1] "" TBOX
 SG_ VBU_QECACC : 26|3@0+ (1,0) [0|7] "" TBOX
 SG_ VBU_EnergyMode : 29|3@0+ (1,0) [0|7] "" TBOX
 SG_ VBU_GearShiftInProgress : 30|1@0+ (1,0) [0|1] "" TBOX
 SG_ VBU_ShiftInProgress_Status : 31|1@0+ (1,0) [0|1] "" TBOX
 SG_ VBU_AcceleratioNModePer : 38|7@0+ (1,0) [0|100] "" TBOX
 SG_ VBU_OverRide : 39|1@0+ (1,0) [0|1] "" TBOX
 SG_ VBU_DriveMode : 42|3@0+ (1,0) [0|7] "" TBOX
 SG_ VBU_APS_LC_Availability : 44|2@0+ (1,0) [0|3] "" TBOX
 SG_ VBU_APS_LC_FailureSts : 47|3@0+ (1,0) [0|7] "" TBOX
 SG_ VBU_E_Pedalwarn : 48|1@0+ (1,0) [0|1] "" TBOX
 SG_ VBU_KeepSOC : 55|7@0+ (1,0) [0|100] "percent" TBOX
 SG_ VBU_APS_LC_Status : 63|4@0+ (1,0) [0|15] "" TBOX
 SG_ Rollingcounter_0x141 : 59|4@0+ (1,0) [0|15] "" TBOX

BO_ 322 VBU_0x142: 8 GW
 SG_ Checksum_0x142 : 7|8@0+ (1,0) [0|255] "" TBOX
 SG_ VBU_vacuumpumpsensorRelvalue : 15|10@0+ (0.2,-108) [-108|5] "Kpa" TBOX
 SG_ VBU_MCU_MotorSpeed : 31|16@0+ (1,-32767) [-32767|32768] "rpm" TBOX
 SG_ VBU_EPB_FunctionSet : 63|2@0+ (1,0) [0|3] "" TBOX
 SG_ Rollingcounter_0x142 : 59|4@0+ (1,0) [0|15] "" TBOX

BO_ 336 VBU_0x150: 8 GW
 SG_ Checksum_0x150 : 7|8@0+ (1,0) [0|255] "" TBOX
 SG_ VBU_GearLeverPos : 10|3@0+ (1,0) [0|7] "" TBOX
 SG_ VBU_TortoiseLamp : 11|1@0+ (1,0) [0|1] "" TBOX
 SG_ VBU_Elockfail : 13|2@0+ (1,0) [0|3] "" TBOX
 SG_ VBU_12VbatteryError : 14|1@0+ (1,0) [0|1] "" TBOX
 SG_ VBU_ReadySts : 15|1@0+ (1,0) [0|1] "" TBOX
 SG_ VBU_MotorPumpError : 16|1@0+ (1,0) [0|1] "" TBOX
 SG_ VBU_VacuumSysFaultLamp : 17|1@0+ (1,0) [0|1] "" TBOX
 SG_ VBU_GearP_EnterWarning : 18|1@0+ (1,0) [0|1] "" TBOX
 SG_ VBU_VehicleSysFaultLamp : 19|1@0+ (1,0) [0|1] "" TBOX
 SG_ VBU_BattPumpError : 20|1@0+ (1,0) [0|1] "" TBOX
 SG_ VBU_DriveableAlarm : 21|1@0+ (1,0) [0|1] "" TBOX
 SG_ VBU_GearFlashReq : 23|2@0+ (1,0) [0|3] "" TBOX
 SG_ VBU_ShowCarMod : 24|1@0+ (1,0) [0|1] "" TBOX
 SG_ VBU_EnergyRecoveryPer : 31|7@0+ (1,0) [0|100] "percent" TBOX
 SG_ VBU_Mileage : 39|10@0+ (1,0) [0|1022] "km" TBOX
 SG_ VBU_BMS_ISOWaringLamp : 40|1@0+ (1,0) [0|1] "" TBOX
 SG_ VBU_BMS_BatteryErrorLamp : 41|1@0+ (1,0) [0|1] "" TBOX
 SG_ VBU_ChargeDepthwarn : 42|1@0+ (1,0) [0|1] "" TBOX
 SG_ VBU_ChargeDepthSts : 44|2@0+ (1,0) [0|3] "" TBOX
 SG_ VBU_CloolantHighAlarm : 45|1@0+ (1,0) [0|1] "" TBOX
 SG_ VBU_MotorLoopCoolantLow : 48|1@0+ (1,0) [0|1] "" TBOX
 SG_ VBU_BatLoopCoolantLow : 49|1@0+ (1,0) [0|1] "" TBOX
 SG_ VBU_PassengerCoolantLow : 50|1@0+ (1,0) [0|1] "" TBOX
 SG_ VBU_BMS_SOClowLamp : 51|1@0+ (1,0) [0|1] "" TBOX
 SG_ VBU_BMS_MaintenanceLamp : 52|1@0+ (1,0) [0|1] "" TBOX
 SG_ VBU_BAT_thermalControlSts : 54|2@0+ (1,0) [0|3] "" TBOX
 SG_ VBU_BMS_ThermRunAway : 55|1@0+ (1,0) [0|1] "" TBOX
 SG_ VBU_ESCLConfig : 60|1@0+ (1,0) [0|1] "" TBOX
 SG_ Rollingcounter_0x150 : 59|4@0+ (1,0) [0|15] "" TBOX

BO_ 337 VBU_0x151: 8 GW
 SG_ Checksum_0x151 : 7|8@0+ (1,0) [0|255] "" TBOX
 SG_ VBU_HVLock_ALL : 9|2@0+ (1,0) [0|3] "" TBOX
 SG_ VBU_BrakeLampReq : 10|1@0+ (1,0) [0|1] "" TBOX
 SG_ VBU_Intelligent_Charge_Sts : 11|1@0+ (1,0) [0|1] "" TBOX
 SG_ VBU_HVLock1 : 13|2@0+ (1,0) [0|3] "" TBOX
 SG_ VBU_UnlockFuelLid : 14|1@0+ (1,0) [0|1] "" TBOX
 SG_ VBU_BrkSw_Sts : 23|2@0+ (1,0) [0|3] "" TBOX
 SG_ VBU_AccelPedalMalSts : 17|2@0+ (1,0) [0|3] "" TBOX
 SG_ VBU_BrkPed_Pos : 31|8@0+ (1,0) [0|100] "percent" TBOX
 SG_ VBU_AccSW_Sts : 39|2@0+ (1,0) [0|3] "" TBOX
 SG_ VBU_AtmosphePressValue : 37|6@0+ (2,0) [0|116] "Kpa" TBOX
 SG_ VBU_AccPedPos : 47|8@0+ (0.5,0) [0|100] "percent" TBOX
 SG_ VBU_TargetGear : 50|3@0+ (1,0) [0|7] "" TBOX
 SG_ VBU_APS_WorkStatus : 55|5@0+ (1,0) [0|31] "" TBOX
 SG_ Rolling_counter_0x151 : 59|4@0+ (1,0) [0|15] "" TBOX
 SG_ VBU_HVLock2 : 61|2@0+ (1,0) [0|3] "" TBOX
 SG_ VBU_HVLock3 : 63|2@0+ (1,0) [0|3] "" TBOX

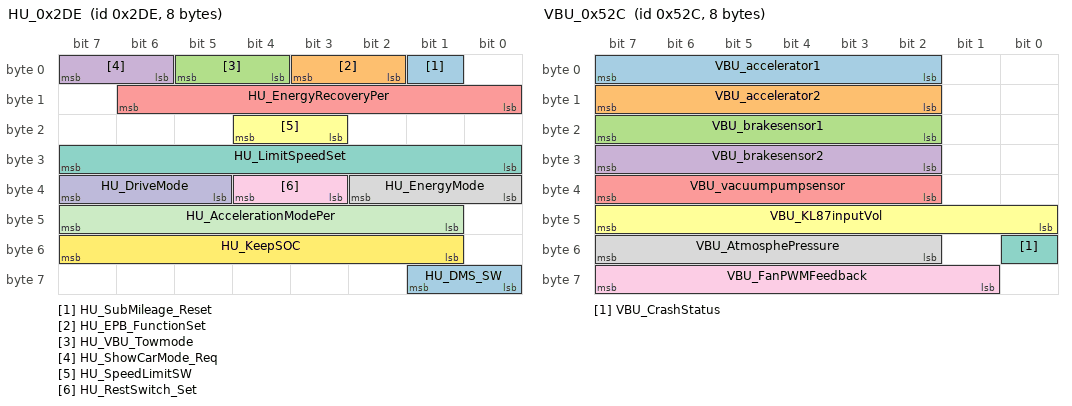
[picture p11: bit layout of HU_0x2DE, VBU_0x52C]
BO_ 734 HU_0x2DE: 8 GW
 SG_ HU_SubMileage_Reset : 1|1@0+ (1,0) [0|1] "" TBOX
 SG_ HU_EPB_FunctionSet : 3|2@0+ (1,0) [0|3] "" TBOX
 SG_ HU_VBU_Towmode : 5|2@0+ (1,0) [0|3] "" TBOX
 SG_ HU_ShowCarMode_Req : 7|2@0+ (1,0) [0|3] "" TBOX
 SG_ HU_EnergyRecoveryPer : 14|7@0+ (1,0) [0|100] "" TBOX
 SG_ HU_SpeedLimitSW : 20|2@0+ (1,0) [0|3] "" TBOX
 SG_ HU_LimitSpeedSet : 31|8@0+ (1,0) [0|200] "" TBOX
 SG_ HU_EnergyMode : 34|3@0+ (1,0) [0|7] "" TBOX
 SG_ HU_RestSwitch_Set : 36|2@0+ (1,0) [0|3] "" TBOX
 SG_ HU_DriveMode : 39|3@0+ (1,0) [0|7] "" TBOX
 SG_ HU_AccelerationModePer : 47|7@0+ (1,0) [0|100] "" TBOX
 SG_ HU_KeepSOC : 55|7@0+ (1,0) [0|100] "%" TBOX
 SG_ HU_DMS_SW : 57|2@0+ (1,0) [0|3] "" TBOX

BO_ 1451 VBU_BMS_FastChargeInf2_0x5AB: 8 GW
 SG_ VBU_BMS_FastChargeInfoU : 7|13@0+ (0.1,0) [0|800] "V" TBOX
 SG_ VBU_BMS_FastChargeSOE : 10|10@0+ (0.1,0) [0|102.3] "kwh" TBOX
 SG_ VBU_BMS_FastChargeInfoI : 31|16@0+ (0.1,-1000) [-1000|1000] "A" TBOX
 SG_ VBU_Dischargetime : 47|9@0+ (0.1,0) [0|48] "h" TBOX
 SG_ VBU_Discharge_energy : 54|10@0+ (0.1,0) [0|100] "kwh" TBOX

BO_ 1452 VBU_BMS_FastChargeInf3_0x5AC: 8 GW
 SG_ VBU_ChrFast_Current_power : 7|10@0+ (100,0) [0|100000] "W" TBOX
 SG_ VBU_ChrFast_MaxCurrent_power : 13|10@0+ (100,0) [0|100000] "W" TBOX

BO_ 1450 VBU_BMS_FastChargeInfo_0x5AA: 8 GW
 SG_ BST_ReachSOCsetting : 0|1@0+ (1,0) [0|1] "" TBOX
 SG_ BST_ReachBattVolset : 1|1@0+ (1,0) [0|1] "" TBOX
 SG_ BST_ReachCellVolset : 2|1@0+ (1,0) [0|1] "" TBOX
 SG_ BST_ISOFault : 3|1@0+ (1,0) [0|1] "" TBOX
 SG_ BST_VBU_BMS_PCBOverTemp : 4|1@0+ (1,0) [0|1] "" TBOX
 SG_ BST_ChargeOverCurr : 5|1@0+ (1,0) [0|1] "" TBOX
 SG_ BST_FastChaVolUnusual : 6|1@0+ (1,0) [0|1] "" TBOX
 SG_ BST_FastChargerSTOP : 7|1@0+ (1,0) [0|1] "" TBOX
 SG_ CST_ReachChargerSet : 9|2@0+ (1,0) [0|3] "" TBOX
 SG_ CST_ManualStop : 11|2@0+ (1,0) [0|3] "" TBOX
 SG_ CST_FaultStop : 13|2@0+ (1,0) [0|3] "" TBOX
 SG_ CST_BMSStop : 15|2@0+ (1,0) [0|3] "" TBOX
 SG_ CST_FastCharOverTemp : 17|2@0+ (1,0) [0|3] "" TBOX
 SG_ CST_CharContorFault : 19|2@0+ (1,0) [0|3] "" TBOX
 SG_ CST_FastChaInOvTemp : 21|2@0+ (1,0) [0|3] "" TBOX
 SG_ CST_EngNotTransfer : 23|2@0+ (1,0) [0|3] "" TBOX
 SG_ CST_FastChaUrgentStop : 25|2@0+ (1,0) [0|3] "" TBOX
 SG_ CST_OtherFault : 27|2@0+ (1,0) [0|3] "" TBOX
 SG_ CST_CurrentMismatch : 29|2@0+ (1,0) [0|3] "" TBOX
 SG_ CST_VoltageUnusual : 31|2@0+ (1,0) [0|3] "" TBOX
 SG_ BEM_CRM_00_OverTim : 32|1@0+ (1,0) [0|1] "" TBOX
 SG_ BEM_CRM_AA_OverTim : 33|1@0+ (1,0) [0|1] "" TBOX
 SG_ BEM_CTSCML_OverTim : 34|1@0+ (1,0) [0|1] "" TBOX
 SG_ BEM_CRO_OverTim : 35|1@0+ (1,0) [0|1] "" TBOX
 SG_ BEM_CCS_OverTim : 36|1@0+ (1,0) [0|1] "" TBOX
 SG_ BEM_CST_OverTim : 37|1@0+ (1,0) [0|1] "" TBOX
 SG_ BEM_CSD_OverTim : 38|1@0+ (1,0) [0|1] "" TBOX
 SG_ CEM_BRM_OverTim : 40|1@0+ (1,0) [0|1] "" TBOX
 SG_ CEM_BCP_OverTim : 41|1@0+ (1,0) [0|1] "" TBOX
 SG_ CEM_BRO_OverTim : 42|1@0+ (1,0) [0|1] "" TBOX
 SG_ CEM_BCS_OverTim : 43|1@0+ (1,0) [0|1] "" TBOX
 SG_ CEM_BCL_OverTim : 44|1@0+ (1,0) [0|1] "" TBOX
 SG_ CEM_BST_OverTim : 45|1@0+ (1,0) [0|1] "" TBOX
 SG_ CEM_BSD_OverTim : 46|1@0+ (1,0) [0|1] "" TBOX
 SG_ VBU_BMS_ChargeSOPbuffer : 55|8@0+ (0.5,0) [0|100] "" TBOX

BO_ 314 VBU_0x13A: 8 GW
 SG_ VBU_Reserved_ID1 : 7|64@0+ (1,0) [0|255] "" TBOX

BO_ 315 TBOX_0x13B: 8 TBOX
 SG_ TBOX_Reserved_ID1 : 7|64@0+ (1,0) [0|255] "" GW

BO_ 1324 VBU_0x52C: 8 GW
 SG_ VBU_accelerator1 : 7|6@0+ (0.1,0) [0|6.3] "V" TBOX
 SG_ VBU_accelerator2 : 15|6@0+ (0.1,0) [0|6.3] "V" TBOX
 SG_ VBU_brakesensor1 : 23|6@0+ (0.1,0) [0|6.3] "V" TBOX
 SG_ VBU_brakesensor2 : 31|6@0+ (0.1,0) [0|6.3] "V" TBOX
 SG_ VBU_vacuumpumpsensor : 39|6@0+ (0.1,0) [0|6.3] "V" TBOX
 SG_ VBU_KL87inputVol : 47|8@0+ (0.1,0) [0|25.4] "V" TBOX
 SG_ VBU_CrashStatus : 48|1@0+ (1,0) [0|1] "" TBOX
 SG_ VBU_AtmosphePressure : 55|6@0+ (0.1,0) [0|6.3] "V" TBOX
 SG_ VBU_FanPWMFeedback : 63|7@0+ (1,0) [0|100] "percent" TBOX

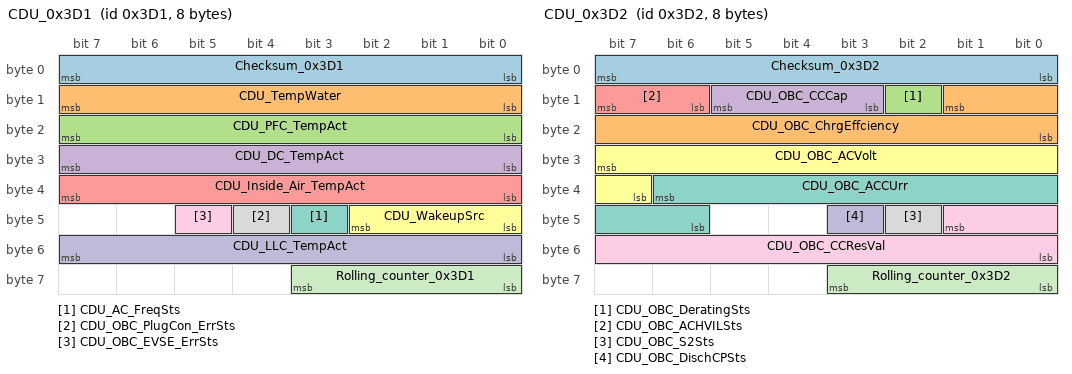
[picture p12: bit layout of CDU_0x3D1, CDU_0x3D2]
BO_ 977 CDU_0x3D1: 8 GW
 SG_ Checksum_0x3D1 : 7|8@0+ (1,0) [0|255] "" TBOX
 SG_ CDU_TempWater : 15|8@0+ (1,-40) [-40|214] "°C" TBOX
 SG_ CDU_PFC_TempAct : 23|8@0+ (1,-40) [-40|214] "℃" TBOX
 SG_ CDU_DC_TempAct : 31|8@0+ (1,-40) [-40|214] "℃" TBOX
 SG_ CDU_Inside_Air_TempAct : 39|8@0+ (1,-40) [-40|214] "℃" TBOX
 SG_ CDU_WakeupSrc : 42|3@0+ (1,0) [0|7] "" TBOX
 SG_ CDU_AC_FreqSts : 43|1@0+ (1,0) [0|1] "" TBOX
 SG_ CDU_OBC_PlugCon_ErrSts : 44|1@0+ (1,0) [0|1] "" TBOX
 SG_ CDU_OBC_EVSE_ErrSts : 45|1@0+ (1,0) [0|1] "" TBOX
 SG_ CDU_LLC_TempAct : 55|8@0+ (1,-40) [-40|214] "℃" TBOX
 SG_ Rolling_counter_0x3D1 : 59|4@0+ (1,0) [0|15] "" TBOX

BO_ 978 CDU_0x3D2: 8 GW
 SG_ Checksum_0x3D2 : 7|8@0+ (1,0) [0|255] "" TBOX
 SG_ CDU_OBC_ChrgEffciency : 9|10@0+ (0.001,0) [0|1] "" TBOX
 SG_ CDU_OBC_DeratingSts : 10|1@0+ (1,0) [0|1] "" TBOX
 SG_ CDU_OBC_CCCap : 13|3@0+ (1,0) [0|7] "" TBOX
 SG_ CDU_OBC_ACHVILSts : 15|2@0+ (1,0) [0|3] "" TBOX
 SG_ CDU_OBC_ACVolt : 31|9@0+ (1,0) [0|300] "V" TBOX
 SG_ CDU_OBC_ACCUrr : 38|9@0+ (0.1,0) [0|40] "A" TBOX
 SG_ CDU_OBC_S2Sts : 42|1@0+ (1,0) [0|1] "" TBOX
 SG_ CDU_OBC_CCResVal : 41|10@0+ (10,0) [0|10230] "ohm" TBOX
 SG_ CDU_OBC_DischCPSts : 43|1@0+ (1,0) [0|1] "" TBOX
 SG_ Rolling_counter_0x3D2 : 59|4@0+ (1,0) [0|15] "" TBOX

BO_ 979 CDU_0x3D3: 8 GW
 SG_ Checksum_0x3D3 : 7|8@0+ (1,0) [0|255] "" TBOX
 SG_ CDU_OBC_HVVolt : 15|16@0+ (0.1,0) [0|600] "V" TBOX
 SG_ CDU_OBC_MaxChrgOutpVolt : 31|16@0+ (0.1,0) [0|600] "V" TBOX
 SG_ CDU_OBC_MaxChrgOutpCur : 47|12@0+ (0.1,0) [0|40] "A" TBOX
 SG_ CDU_OBC_HVCurr : 51|12@0+ (0.1,-102.4) [-102.4|60] "A" TBOX

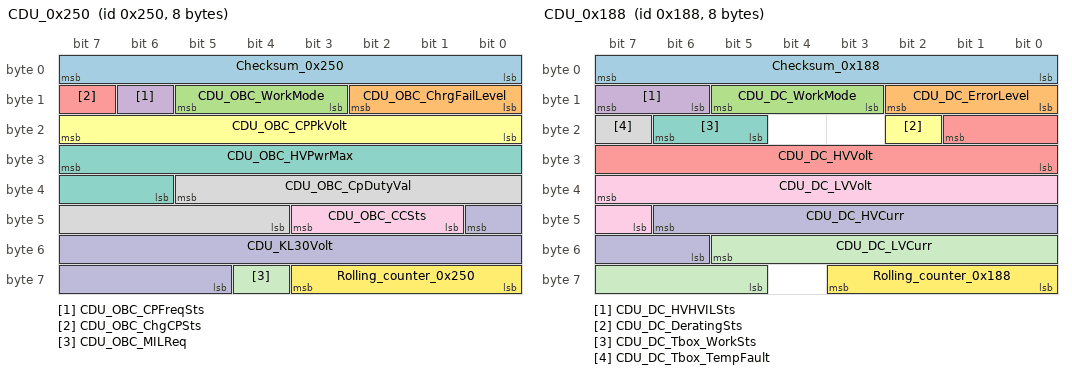
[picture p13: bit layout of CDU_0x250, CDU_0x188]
BO_ 592 CDU_0x250: 8 GW
 SG_ Checksum_0x250 : 7|8@0+ (1,0) [0|255] "" TBOX
 SG_ CDU_OBC_ChrgFailLevel : 10|3@0+ (1,0) [0|7] "" TBOX
 SG_ CDU_OBC_WorkMode : 13|3@0+ (1,0) [0|7] "" TBOX
 SG_ CDU_OBC_CPFreqSts : 14|1@0+ (1,0) [0|1] "" TBOX
 SG_ CDU_OBC_ChgCPSts : 15|1@0+ (1,0) [0|1] "" TBOX
 SG_ CDU_OBC_CPPkVolt : 23|8@0+ (0.1,0) [0|25.5] "V" TBOX
 SG_ CDU_OBC_HVPwrMax : 31|10@0+ (0.05,0) [0|50] "kW" TBOX
 SG_ CDU_OBC_CpDutyVal : 37|10@0+ (0.1,0) [0|100] "" TBOX
 SG_ CDU_OBC_CCSts : 43|3@0+ (1,0) [0|7] "" TBOX
 SG_ CDU_KL30Volt : 40|12@0+ (0.1,0) [0|60] "V" TBOX
 SG_ CDU_OBC_MILReq : 60|1@0+ (1,0) [0|1] "" TBOX
 SG_ Rolling_counter_0x250 : 59|4@0+ (1,0) [0|15] "" TBOX

BO_ 392 CDU_0x188: 8 GW
 SG_ Checksum_0x188 : 7|8@0+ (1,0) [0|255] "" TBOX
 SG_ CDU_DC_ErrorLevel : 10|3@0+ (1,0) [0|7] "" TBOX
 SG_ CDU_DC_WorkMode : 13|3@0+ (1,0) [0|7] "" TBOX
 SG_ CDU_DC_HVHVILSts : 15|2@0+ (1,0) [0|3] "" TBOX
 SG_ CDU_DC_HVVolt : 17|10@0+ (1,0) [0|600] "V" TBOX
 SG_ CDU_DC_DeratingSts : 18|1@0+ (1,0) [0|1] "" TBOX
 SG_ CDU_DC_Tbox_WorkSts : 22|2@0+ (1,0) [0|3] "" TBOX
 SG_ CDU_DC_Tbox_TempFault : 23|1@0+ (1,0) [0|1] "" TBOX
 SG_ CDU_DC_LVVolt : 39|9@0+ (0.1,0) [0|18] "V" TBOX
 SG_ CDU_DC_HVCurr : 46|9@0+ (0.125,0) [0|60] "A" TBOX
 SG_ CDU_DC_LVCurr : 53|9@0+ (1,0) [0|511] "A" TBOX
 SG_ Rolling_counter_0x188 : 59|4@0+ (1,0) [0|15] "" TBOX

BO_ 1552 CDU_0x610: 8 GW
 SG_ CDU_OBC_ACHVIL_Fault : 0|1@0+ (1,0) [0|1] "" TBOX
 SG_ CDU_OBC_Input_Overvolt_SW : 1|1@0+ (1,0) [0|1] "" TBOX
 SG_ CDU_OBC_Input_Undervolt_SW : 2|1@0+ (1,0) [0|1] "" TBOX
 SG_ CDU_OBC_HW_InputCurHig_lv2 : 3|1@0+ (1,0) [0|1] "" TBOX
 SG_ CDU_OBC_HW_InputCurHig_lv3 : 4|1@0+ (1,0) [0|1] "" TBOX
 SG_ CDU_OBC_AC_AbnormFreq : 5|1@0+ (1,0) [0|1] "" TBOX
 SG_ CDU_OBC_Output_Overvolt : 6|1@0+ (1,0) [0|1] "" TBOX
 SG_ CDU_OBC_Output_Undervolt_HW : 7|1@0+ (1,0) [0|1] "" TBOX
 SG_ CDU_OBC_HW_OutputCurHig_lv2 : 8|1@0+ (1,0) [0|1] "" TBOX
 SG_ CDU_OBC_HW_OutputCurHig_lv3 : 9|1@0+ (1,0) [0|1] "" TBOX
 SG_ CDU_OBC_SW_OutputCurHig_lv2 : 10|1@0+ (1,0) [0|1] "" TBOX
 SG_ CDU_OBC_SW_OutputCurHig_lv3 : 11|1@0+ (1,0) [0|1] "" TBOX
 SG_ CDU_OBC_OverTemp : 12|1@0+ (1,0) [0|1] "" TBOX
 SG_ CDU_OBC_Input_Underpower : 13|1@0+ (1,0) [0|1] "" TBOX
 SG_ CDU_OBC_Input_Overpower : 14|1@0+ (1,0) [0|1] "" TBOX
 SG_ CDU_OBC_Output_Underpower : 15|1@0+ (1,0) [0|1] "" TBOX
 SG_ CDU_OBC_HigTemp : 16|1@0+ (1,0) [0|1] "" TBOX
 SG_ CDU_OBC_Start_Failure : 17|1@0+ (1,0) [0|1] "" TBOX
 SG_ CDU_OBC_Prechrg_Fault : 18|1@0+ (1,0) [0|1] "" TBOX
 SG_ CDU_OBC_OutputShortCirc : 19|1@0+ (1,0) [0|1] "" TBOX
 SG_ CDU_OBC_PFC_Start_Failure : 20|1@0+ (1,0) [0|1] "" TBOX
 SG_ CDU_OBC_PFC_Busvolt_Hig : 21|1@0+ (1,0) [0|1] "" TBOX
 SG_ CDU_OBC_PFC_Busvolt_Low_lv2 : 22|1@0+ (1,0) [0|1] "" TBOX
 SG_ CDU_OBC_PFC_Busvolt_Low_lv3 : 23|1@0+ (1,0) [0|1] "" TBOX
 SG_ CDU_OBC_Dischr_ACvolt_Hig : 24|1@0+ (1,0) [0|1] "" TBOX
 SG_ CDU_OBC_Dischr_ACvolt_Low : 25|1@0+ (1,0) [0|1] "" TBOX
 SG_ CDU_OBC_SW_Dischr_ACCur_Hig : 26|1@0+ (1,0) [0|1] "" TBOX
 SG_ CDU_OBC_HW_Dischr_ACCur_Hig : 27|1@0+ (1,0) [0|1] "" TBOX
 SG_ CDU_OBC_Dischr_AC_AbnormFreq : 28|1@0+ (1,0) [0|1] "" TBOX
 SG_ CDU_OBC_SW_Dischr_Overvolt : 29|1@0+ (1,0) [0|1] "" TBOX
 SG_ CDU_OBC_Dischr_AC_Overvolt : 30|1@0+ (1,0) [0|1] "" TBOX
 SG_ CDU_OBC_HW_Dischr_CurHig : 31|1@0+ (1,0) [0|1] "" TBOX
 SG_ CDU_OBC_SW_Dischr_CurHig : 32|1@0+ (1,0) [0|1] "" TBOX
 SG_ CDU_OBC_Dischr_ShotCirc : 33|1@0+ (1,0) [0|1] "" TBOX
 SG_ Abnormal_Insulation_Resistance : 34|1@0+ (1,0) [0|1] "" TBOX
 SG_ CDU_OBC_DTC : 63|8@0+ (1,0) [0|255] "" TBOX

BO_ 1553 CDU_0x611: 8 GW
 SG_ CDU_DCDC_OutputVolHig_lv2 : 1|1@0+ (1,0) [0|1] "" TBOX
 SG_ CDU_DCDC_OutputVolHig_lv3 : 2|1@0+ (1,0) [0|1] "" TBOX
 SG_ CDU_DCDC_OutputVolLow_lv2 : 3|1@0+ (1,0) [0|1] "" TBOX
 SG_ CDU_DCDC_OutputVolLow_lv3 : 4|1@0+ (1,0) [0|1] "" TBOX
 SG_ CDU_DCDC_OutputOpen : 5|1@0+ (1,0) [0|1] "" TBOX
 SG_ CDU_DCDC_HW_OutputCurHig_lv2 : 6|1@0+ (1,0) [0|1] "" TBOX
 SG_ CDU_DCDC_HW_OutputCurHig_lv3 : 7|1@0+ (1,0) [0|1] "" TBOX
 SG_ CDU_DCDC_SW_OutputCurHig_lv2 : 8|1@0+ (1,0) [0|1] "" TBOX
 SG_ CDU_DCDC_SW_OutputCurHig_lv3 : 9|1@0+ (1,0) [0|1] "" TBOX
 SG_ CDU_DCDC_OutputShotCirc_lv2 : 10|1@0+ (1,0) [0|1] "" TBOX
 SG_ CDU_DCDC_OutputShotCirc_lv3 : 11|1@0+ (1,0) [0|1] "" TBOX
 SG_ KL30_Input_Overvolt : 12|1@0+ (1,0) [0|1] "" TBOX
 SG_ KL30_Input_Undervolt : 13|1@0+ (1,0) [0|1] "" TBOX
 SG_ CDU_DCDC_TempSensorFault : 14|1@0+ (1,0) [0|1] "" TBOX
 SG_ CDU_DCDC_InputVolHig : 15|1@0+ (1,0) [0|1] "" TBOX
 SG_ CDU_DCDC_InputVolLow : 16|1@0+ (1,0) [0|1] "" TBOX
 SG_ CDU_DCDC_start_Failure : 17|1@0+ (1,0) [0|1] "" TBOX
 SG_ CDU_DCDC_SW_InputVolHig : 18|1@0+ (1,0) [0|1] "" TBOX
 SG_ CDU_DCDC_SW_InputVolLow : 19|1@0+ (1,0) [0|1] "" TBOX
 SG_ CDU_DCDC_OverTemp : 20|1@0+ (1,0) [0|1] "" TBOX
 SG_ CDU_DC_SCI_Com_Failure : 21|1@0+ (1,0) [0|1] "" TBOX
 SG_ CDU_DCDC_MCUChecksum_Failure : 22|1@0+ (1,0) [0|1] "" TBOX
 SG_ CDU_DCDC_InnerTempHig : 23|1@0+ (1,0) [0|1] "" TBOX
 SG_ CDU_DCDC_Shutdown_For_LowTemp : 24|1@0+ (1,0) [0|1] "" TBOX
 SG_ CDU_Busoff : 25|1@0+ (1,0) [0|1] "" TBOX
 SG_ CDU_Lost_Communication : 26|1@0+ (1,0) [0|1] "" TBOX
 SG_ CDU_DCDC_HVHVIL_Fault : 27|1@0+ (1,0) [0|1] "" TBOX
 SG_ CDU_DC_DTC : 63|8@0+ (1,0) [0|255] "" TBOX

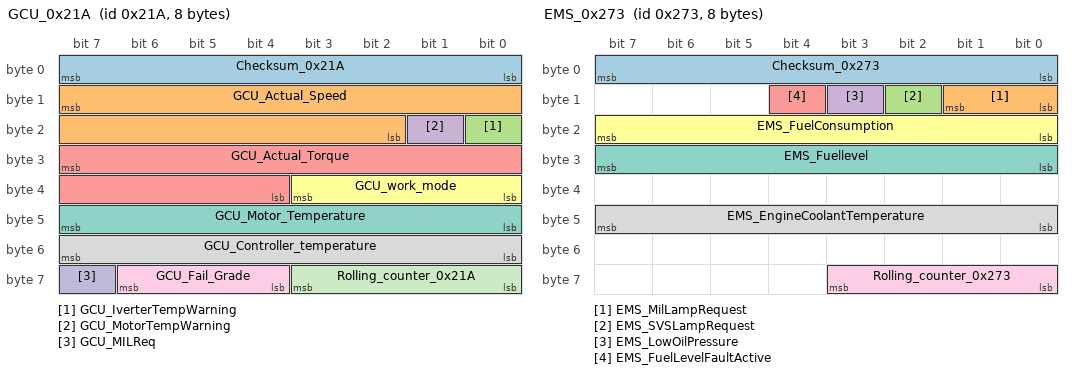
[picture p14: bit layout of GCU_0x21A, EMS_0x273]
BO_ 538 GCU_0x21A: 8 GW
 SG_ Checksum_0x21A : 7|8@0+ (1,0) [0|255] "" TBOX
 SG_ GCU_Actual_Speed : 15|14@0+ (1,-7000) [-7000|7000] "rpm" TBOX
 SG_ GCU_IverterTempWarning : 16|1@0+ (1,0) [0|1] "" TBOX
 SG_ GCU_MotorTempWarning : 17|1@0+ (1,0) [0|1] "" TBOX
 SG_ GCU_Actual_Torque : 31|12@0+ (0.5,-1000) [-1000|1000] "Nm" TBOX
 SG_ GCU_work_mode : 35|4@0+ (1,0) [0|15] "" TBOX
 SG_ GCU_Motor_Temperature : 47|8@0+ (1,-40) [-40|215] "℃" TBOX
 SG_ GCU_Controller_temperature : 55|8@0+ (1,-40) [-40|215] "℃" TBOX
 SG_ GCU_Fail_Grade : 62|3@0+ (1,0) [0|7] "" TBOX
 SG_ GCU_MILReq : 63|1@0+ (1,0) [0|1] "" TBOX
 SG_ Rolling_counter_0x21A : 59|4@0+ (1,0) [0|15] "" TBOX

BO_ 539 GCU_0x21B: 8 GW
 SG_ GCU_DTC_CODE : 7|16@0+ (1,0) [0|65535] "" TBOX
 SG_ GCU_MotorNumber : 23|3@0+ (1,0) [0|4] "" TBOX
 SG_ GCU_DC_Current : 20|12@0+ (1,-1000) [-1000|1000] "A" TBOX
 SG_ GCU_DC_Voltage : 24|11@0+ (1,0) [0|1000] "V" TBOX
 SG_ GCU_P2_Hardware_code : 45|16@0+ (1,0) [0|65535] "" TBOX

BO_ 626 EMS_0x272: 8 GW
 SG_ Checksum_0x272 : 7|8@0+ (1,0) [0|255] "" TBOX
 SG_ EMS_PSNotActiveTimeAccu : 15|16@0+ (1,0) [0|65534] "min" TBOX
 SG_ EMS_EngineSpeed : 31|13@0+ (1,0) [0|8000] "rpm" TBOX
 SG_ EMS_EngineStatus : 34|3@0+ (1,0) [0|7] "" TBOX
 SG_ EMS_DesireIdleSpeed : 47|13@0+ (1,0) [0|8000] "rpm" TBOX
 SG_ Rolling_counter_0x272 : 59|4@0+ (1,0) [0|15] "" TBOX

BO_ 627 EMS_0x273: 8 GW
 SG_ Checksum_0x273 : 7|8@0+ (1,0) [0|255] "" TBOX
 SG_ EMS_MilLampRequest : 9|2@0+ (1,0) [0|3] "" TBOX
 SG_ EMS_SVSLampRequest : 10|1@0+ (1,0) [0|1] "" TBOX
 SG_ EMS_LowOilPressure : 11|1@0+ (1,0) [0|1] "" TBOX
 SG_ EMS_FuelLevelFaultActive : 12|1@0+ (1,0) [0|1] "" TBOX
 SG_ EMS_FuelConsumption : 23|8@0+ (0.0155,0) [0|3.937] "ml" TBOX
 SG_ EMS_Fuellevel : 31|8@0+ (0.5,0) [0|100] "%" TBOX
 SG_ EMS_EngineCoolantTemperature : 47|8@0+ (0.75,-48) [-48|142.5] "" TBOX
 SG_ Rolling_counter_0x273 : 59|4@0+ (1,0) [0|15] "" TBOX

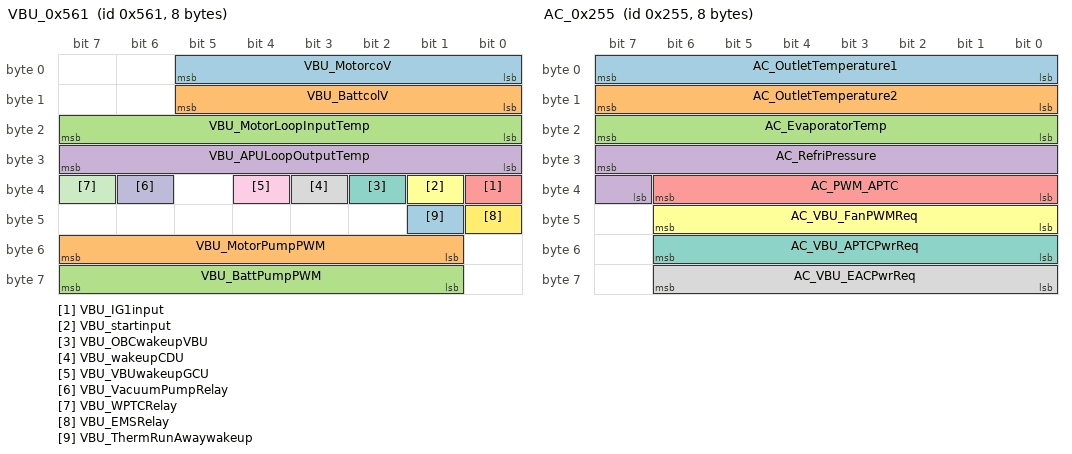
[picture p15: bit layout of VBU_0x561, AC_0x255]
BO_ 1377 VBU_0x561: 8 GW
 SG_ VBU_MotorcoV : 5|6@0+ (0.1,0) [0|6.3] "V" TBOX
 SG_ VBU_BattcolV : 13|6@0+ (0.1,0) [0|6.3] "V" TBOX
 SG_ VBU_MotorLoopInputTemp : 23|8@0+ (1,-40) [-40|215] "degC" TBOX
 SG_ VBU_APULoopOutputTemp : 31|8@0+ (1,-40) [-40|215] "degC" TBOX
 SG_ VBU_IG1input : 32|1@0+ (1,0) [0|1] "" TBOX
 SG_ VBU_startinput : 33|1@0+ (1,0) [0|1] "" TBOX
 SG_ VBU_OBCwakeupVBU : 34|1@0+ (1,0) [0|1] "" TBOX
 SG_ VBU_wakeupCDU : 35|1@0+ (1,0) [0|1] "" TBOX
 SG_ VBU_VBUwakeupGCU : 36|1@0+ (1,0) [0|1] "" TBOX
 SG_ VBU_VacuumPumpRelay : 38|1@0+ (1,0) [0|1] "" TBOX
 SG_ VBU_WPTCRelay : 39|1@0+ (1,0) [0|1] "" TBOX
 SG_ VBU_EMSRelay : 40|1@0+ (1,0) [0|1] "" TBOX
 SG_ VBU_ThermRunAwaywakeup : 41|1@0+ (1,0) [0|1] "" TBOX
 SG_ VBU_MotorPumpPWM : 55|7@0+ (1,0) [0|100] "percent" TBOX
 SG_ VBU_BattPumpPWM : 63|7@0+ (1,0) [0|100] "percent" TBOX

BO_ 597 AC_0x255: 8 GW
 SG_ AC_OutletTemperature1 : 7|8@0+ (0.5,-40) [-40|80] "℃" TBOX
 SG_ AC_OutletTemperature2 : 15|8@0+ (0.5,-40) [-40|80] "℃" TBOX
 SG_ AC_EvaporatorTemp : 23|8@0+ (0.5,-40) [-40|80] "℃" TBOX
 SG_ AC_RefriPressure : 31|9@0+ (0.01,0) [0.1|3.5] "MPa" TBOX
 SG_ AC_PWM_APTC : 38|7@0+ (1,0) [0|100] "%" TBOX
 SG_ AC_VBU_FanPWMReq : 46|7@0+ (1,0) [0|100] "%" TBOX
 SG_ AC_VBU_APTCPwrReq : 54|7@0+ (0.1,0) [0|12.7] "" TBOX
 SG_ AC_VBU_EACPwrReq : 62|7@0+ (0.1,0) [0|12.7] "" TBOX

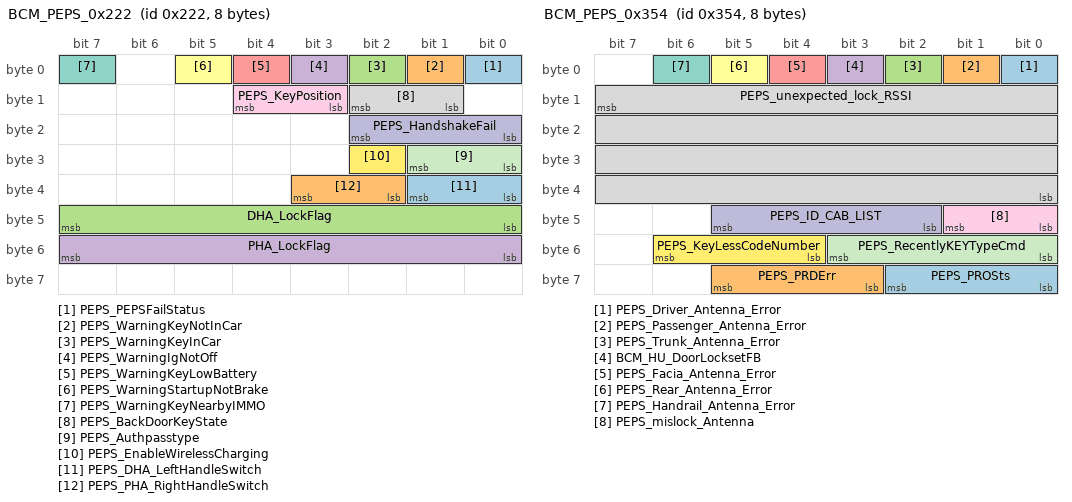
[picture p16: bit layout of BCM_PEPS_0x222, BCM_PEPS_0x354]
BO_ 546 BCM_PEPS_0x222: 8 GW
 SG_ PEPS_PEPSFailStatus : 0|1@0+ (1,0) [0|1] "" TBOX
 SG_ PEPS_WarningKeyNotInCar : 1|1@0+ (1,0) [0|1] "" TBOX
 SG_ PEPS_WarningKeyInCar : 2|1@0+ (1,0) [0|1] "" TBOX
 SG_ PEPS_WarningIgNotOff : 3|1@0+ (1,0) [0|1] "" TBOX
 SG_ PEPS_WarningKeyLowBattery : 4|1@0+ (1,0) [0|1] "" TBOX
 SG_ PEPS_WarningStartupNotBrake : 5|1@0+ (1,0) [0|1] "" TBOX
 SG_ PEPS_WarningKeyNearbyIMMO : 7|1@0+ (1,0) [0|1] "" TBOX
 SG_ PEPS_BackDoorKeyState : 10|2@0+ (1,0) [0|3] "" TBOX
 SG_ PEPS_KeyPosition : 12|2@0+ (1,0) [0|3] "" TBOX
 SG_ PEPS_HandshakeFail : 18|3@0+ (1,0) [0|7] "" TBOX
 SG_ PEPS_Authpasstype : 25|2@0+ (1,0) [0|3] "" TBOX
 SG_ PEPS_EnableWirelessCharging : 26|1@0+ (1,0) [0|1] "" TBOX
 SG_ PEPS_DHA_LeftHandleSwitch : 33|2@0+ (1,0) [0|3] "" TBOX
 SG_ PEPS_PHA_RightHandleSwitch : 35|2@0+ (1,0) [0|3] "" TBOX
 SG_ DHA_LockFlag : 47|8@0+ (1,0) [0|255] "" TBOX
 SG_ PHA_LockFlag : 55|8@0+ (1,0) [0|255] "" TBOX

BO_ 852 BCM_PEPS_0x354: 8 GW
 SG_ PEPS_Driver_Antenna_Error : 0|1@0+ (1,0) [0|1] "" TBOX
 SG_ PEPS_Passenger_Antenna_Error : 1|1@0+ (1,0) [0|1] "" TBOX
 SG_ PEPS_Trunk_Antenna_Error : 2|1@0+ (1,0) [0|1] "" TBOX
 SG_ BCM_HU_DoorLocksetFB : 3|1@0+ (1,0) [0|1] "" TBOX
 SG_ PEPS_Facia_Antenna_Error : 4|1@0+ (1,0) [0|1] "" TBOX
 SG_ PEPS_Rear_Antenna_Error : 5|1@0+ (1,0) [0|1] "" TBOX
 SG_ PEPS_Handrail_Antenna_Error : 6|1@0+ (1,0) [0|1] "" TBOX
 SG_ PEPS_unexpected_lock_RSSI : 15|32@0+ (1,0) [0|4294967294] "" TBOX
 SG_ PEPS_mislock_Antenna : 41|2@0+ (1,0) [0|3] "" TBOX
 SG_ PEPS_ID_CAB_LIST : 45|4@0+ (1,0) [0|15] "" TBOX
 SG_ PEPS_RecentlyKEYTypeCmd : 51|4@0+ (1,0) [0|15] "" TBOX
 SG_ PEPS_KeyLessCodeNumber : 54|3@0+ (1,0) [0|7] "" TBOX
 SG_ PEPS_PROSts : 58|3@0+ (1,0) [0|1] "" TBOX
 SG_ PEPS_PRDErr : 61|3@0+ (1,0) [0|1] "" TBOX

BO_ 912 DSM_0x390: 8 GW
 SG_ DSM_MirrorRdownSetStatus : 0|1@0+ (1,0) [0|1] "" TBOX
 SG_ DSM_LeftMirrorPosition_SX : 7|7@0+ (1,0) [0|100] "%" TBOX
 SG_ DSM_SeatMotorSts : 8|1@0+ (1,0) [0|1] "" TBOX
 SG_ DSM_LeftMirrorPosition_ZY : 15|7@0+ (1,0) [0|100] "%" TBOX
 SG_ DSM_MirrorSts : 16|1@0+ (1,0) [0|1] "" TBOX
 SG_ DSM_RightMirrorPosition_SX : 23|7@0+ (1,0) [0|100] "%" TBOX
 SG_ DSM_RightMirrorPosition_ZY : 31|7@0+ (1,0) [0|100] "%" TBOX
 SG_ DSM_LeftMirrorMotor1fault : 32|1@0+ (1,0) [0|1] "" TBOX
 SG_ DSM_LeftMirrorMotor2fault : 33|1@0+ (1,0) [0|1] "" TBOX
 SG_ DSM_RightMirrorMotor1fault : 34|1@0+ (1,0) [0|1] "" TBOX
 SG_ DSM_RightMirrorMotor2fault : 35|1@0+ (1,0) [0|1] "" TBOX
 SG_ DSM_WorkMode : 38|3@0+ (1,0) [0|7] "" TBOX
 SG_ DSM_LM_DirectionSts_SX : 41|2@0+ (1,0) [0|3] "" TBOX
 SG_ DSM_LM_DirectionSts_ZY : 43|2@0+ (1,0) [0|3] "" TBOX
 SG_ DSM_RM_DirectionSts_SX : 45|2@0+ (1,0) [0|3] "" TBOX
 SG_ DSM_RM_DirectionSts_ZY : 47|2@0+ (1,0) [0|3] "" TBOX
 SG_ DSM_CalibrationAlarm : 49|2@0+ (1,0) [0|3] "" TBOX
 SG_ DSM_PSMsettemp : 55|6@0+ (1,0) [34|42] "℃" TBOX
 SG_ DSM_CalibrationSts : 57|2@0+ (1,0) [0|3] "" TBOX
 SG_ DSM_DSMsettemp : 63|6@0+ (1,0) [34|42] "℃" TBOX

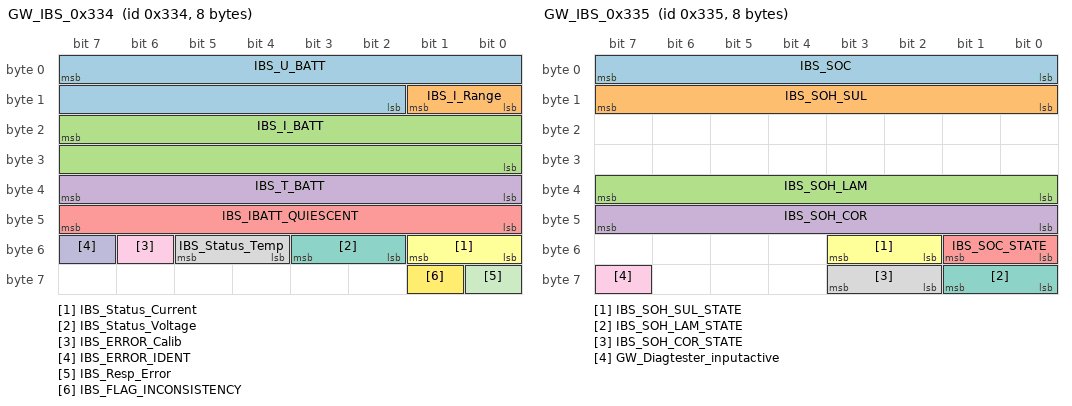
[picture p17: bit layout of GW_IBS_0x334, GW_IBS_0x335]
BO_ 820 GW_IBS_0x334: 8 GW
 SG_ IBS_U_BATT : 7|14@0+ (0.0009765625,3) [3|18] "V" TBOX
 SG_ IBS_I_Range : 9|2@0+ (1,0) [0|3] "" TBOX
 SG_ IBS_I_BATT : 23|16@0+ (1,-32768) [-32768|32766] "A" TBOX
 SG_ IBS_T_BATT : 39|8@0+ (1,-40) [-40|105] "°C" TBOX
 SG_ IBS_IBATT_QUIESCENT : 47|8@0+ (0.00390625,0) [0|0.984375] "A" TBOX
 SG_ IBS_Status_Current : 49|2@0+ (1,0) [0|3] "" TBOX
 SG_ IBS_Status_Voltage : 51|2@0+ (1,0) [0|3] "" TBOX
 SG_ IBS_Status_Temp : 53|2@0+ (1,0) [0|3] "" TBOX
 SG_ IBS_ERROR_Calib : 54|1@0+ (1,0) [0|1] "" TBOX
 SG_ IBS_ERROR_IDENT : 55|1@0+ (1,0) [0|1] "" TBOX
 SG_ IBS_Resp_Error : 56|1@0+ (1,0) [0|1] "" TBOX
 SG_ IBS_FLAG_INCONSISTENCY : 57|1@0+ (1,0) [0|1] "" TBOX

BO_ 821 GW_IBS_0x335: 8 GW
 SG_ IBS_SOC : 7|8@0+ (1,0) [0|100] "%" TBOX
 SG_ IBS_SOH_SUL : 15|8@0+ (1,0) [0|100] "%" TBOX
 SG_ IBS_SOH_LAM : 39|8@0+ (0.5,0) [0|127] "Ah" TBOX
 SG_ IBS_SOH_COR : 47|8@0+ (0.0625,0) [0|15.875] "V" TBOX
 SG_ IBS_SOC_STATE : 49|2@0+ (1,0) [0|3] "" TBOX
 SG_ IBS_SOH_SUL_STATE : 51|2@0+ (1,0) [0|3] "" TBOX
 SG_ IBS_SOH_LAM_STATE : 57|2@0+ (1,0) [0|3] "" TBOX
 SG_ IBS_SOH_COR_STATE : 59|2@0+ (1,0) [0|3] "" TBOX
 SG_ GW_Diagtester_inputactive : 63|1@0+ (1,0) [0|1] "" TBOX

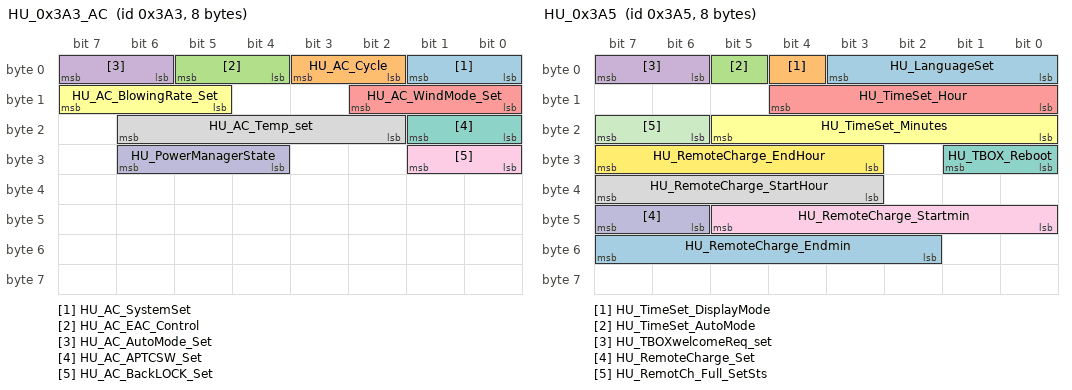
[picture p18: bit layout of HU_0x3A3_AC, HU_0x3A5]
BO_ 931 HU_0x3A3_AC: 8 GW
 SG_ HU_AC_SystemSet : 1|2@0+ (1,0) [0|3] "" TBOX
 SG_ HU_AC_Cycle : 3|2@0+ (1,0) [0|3] "" TBOX
 SG_ HU_AC_EAC_Control : 5|2@0+ (1,0) [0|3] "" TBOX
 SG_ HU_AC_AutoMode_Set : 7|2@0+ (1,0) [0|3] "" TBOX
 SG_ HU_AC_WindMode_Set : 10|3@0+ (1,0) [0|7] "" TBOX
 SG_ HU_AC_BlowingRate_Set : 15|3@0+ (1,0) [0|7] "" TBOX
 SG_ HU_AC_APTCSW_Set : 17|2@0+ (1,0) [0|3] "" TBOX
 SG_ HU_AC_Temp_set : 22|5@0+ (1,0) [15|31] "" TBOX
 SG_ HU_AC_BackLOCK_Set : 25|2@0+ (1,0) [0|3] "" TBOX
 SG_ HU_PowerManagerState : 30|3@0+ (1,0) [0|7] "" TBOX

BO_ 933 HU_0x3A5: 8 GW
 SG_ HU_LanguageSet : 3|4@0+ (1,0) [0|15] "" TBOX
 SG_ HU_TimeSet_DisplayMode : 4|1@0+ (1,0) [0|1] "" TBOX
 SG_ HU_TimeSet_AutoMode : 5|1@0+ (1,0) [0|1] "" TBOX
 SG_ HU_TBOXwelcomeReq_set : 7|2@0+ (1,0) [0|3] "" TBOX
 SG_ HU_TimeSet_Hour : 12|5@0+ (1,0) [0|31] "" TBOX
 SG_ HU_TimeSet_Minutes : 21|6@0+ (1,0) [0|60] "" TBOX
 SG_ HU_TBOX_Reboot : 25|2@0+ (1,0) [0|3] "" TBOX
 SG_ HU_RemoteCharge_StartHour : 39|5@0+ (1,0) [0|23] "" TBOX
 SG_ HU_RemoteCharge_Startmin : 45|6@0+ (1,0) [0|59] "" TBOX
 SG_ HU_RemoteCharge_Set : 47|2@0+ (1,0) [0|3] "" TBOX
 SG_ HU_RemotCh_Full_SetSts : 23|2@0+ (1,0) [0|3] "" TBOX
 SG_ HU_RemoteCharge_EndHour : 31|5@0+ (1,0) [0|23] "hour" TBOX
 SG_ HU_RemoteCharge_Endmin : 55|6@0+ (1,0) [0|59] "min" TBOX

BO_ 816 BCM_0x330: 8 GW
 SG_ BCM_reversingLampSW : 0|1@0+ (1,0) [0|1] "" TBOX
 SG_ BCM_Rsp_HU_Daylight : 1|1@0+ (1,0) [0|1] "" TBOX
 SG_ BCM_CarpetlampSW : 3|1@0+ (1,0) [0|1] "" TBOX
 SG_ BCM_CarpetlampSWSetsts : 4|1@0+ (1,0) [0|1] "" TBOX
 SG_ BCM_HU_RLSModeSts : 6|2@0+ (1,0) [0|3] "" TBOX
 SG_ BCM_FrontdecoralampSW : 7|1@0+ (1,0) [0|1] "" TBOX
 SG_ BCM_WinCloseReminder : 14|3@0+ (1,0) [0|7] "" TBOX
 SG_ BCM_DomeLampDoorControl : 15|1@0+ (1,0) [0|1] "" TBOX
 SG_ BCM_LockWelcomeSts : 17|2@0+ (1,0) [0|3] "" TBOX
 SG_ BCM_PEPSLockReason : 20|3@0+ (1,0) [0|7] "" TBOX
 SG_ BCM_PEPSUnLockReason : 23|3@0+ (1,0) [0|7] "" TBOX
 SG_ BCM_ESCLConfig : 24|1@0+ (1,0) [0|1] "" TBOX
 SG_ BCM_RLS_All_WdwClosed_Sts : 26|2@0+ (1,0) [0|3] "" TBOX
 SG_ BCM_FollowMeControlsts : 27|1@0+ (1,0) [0|1] "" TBOX
 SG_ BCM_FollowMeDelayTSetsts : 29|2@0+ (1,0) [0|3] "" TBOX
 SG_ BCM_RR_LED2_Error : 30|1@0+ (1,0) [0|1] "" TBOX
 SG_ BCM_AutoLockSetsts : 31|1@0+ (1,0) [0|1] "" TBOX
 SG_ BCM_RL_LED2_Error : 32|1@0+ (1,0) [0|1] "" TBOX
 SG_ BCM_WindowAutoUPSetsts : 33|1@0+ (1,0) [0|1] "" TBOX
 SG_ BCM_FL_LED_Error : 34|1@0+ (1,0) [0|1] "" TBOX
 SG_ BCM_FR_LED_Error : 35|1@0+ (1,0) [0|1] "" TBOX
 SG_ BCM_RL_LED1_Error : 36|1@0+ (1,0) [0|1] "" TBOX
 SG_ BCM_RR_LED1_Error : 37|1@0+ (1,0) [0|1] "" TBOX
 SG_ BCM_SSB1_inputSts : 38|1@0+ (1,0) [0|1] "" TBOX
 SG_ BCM_SSB2_inputSts : 39|1@0+ (1,0) [0|1] "" TBOX
 SG_ BCM_LockReason : 43|4@0+ (1,0) [0|15] "" TBOX
 SG_ BCM_UnLockReason : 47|4@0+ (1,0) [0|15] "" TBOX
 SG_ BCM_ACU_Crash_inputsts : 55|1@0+ (1,0) [0|1] "" TBOX
 SG_ BCM_ESCL_UnlockFB_inputsts : 56|1@0+ (1,0) [0|1] "" TBOX
 SG_ BCM_ESCL_Motorpower_outputsts : 57|1@0+ (1,0) [0|1] "" TBOX
 SG_ BCM_ESCL_LockEnable_outputsts : 58|1@0+ (1,0) [0|1] "" TBOX
 SG_ BCM_ESCL_UnLockfail : 59|1@0+ (1,0) [0|1] "" TBOX
 SG_ BCM_ESCL_Lockfail : 60|1@0+ (1,0) [0|1] "" TBOX
 SG_ BCM_waterlightlimit : 61|1@0+ (1,0) [0|1] "" TBOX

BO_ 961 TBOX_0x3C1: 8 TBOX
 SG_ Tbox_ICM_ODOTotal : 7|24@0+ (1,0) [0|999999] "KM" GW
 SG_ Tbox_ICM_Prevmaintmileage : 31|24@0+ (1,0) [0|999999] "KM" GW

BO_ 1281 BCM_TPMS_0x501: 8 GW
 SG_ TPMS_FL_Pressure_value : 7|8@0+ (1.373,0) [0|348.742] "kPa" TBOX
 SG_ TPMS_FR_Pressure_value : 15|8@0+ (1.373,0) [0|348.742] "kPa" TBOX
 SG_ TPMS_RL_Pressure_value : 23|8@0+ (1.373,0) [0|348.742] "kPa" TBOX
 SG_ TPMS_RR_Pressure_value : 31|8@0+ (1.373,0) [0|348.742] "kPa" TBOX
 SG_ TPMS_FL_Temperature : 39|8@0+ (1,-60) [-60|194] "℃" TBOX
 SG_ TPMS_FR_Temperature : 47|8@0+ (1,-60) [-60|194] "℃" TBOX
 SG_ TPMS_RR_Temperature : 55|8@0+ (1,-60) [-60|194] "℃" TBOX
 SG_ TPMS_RL_Temperature : 63|8@0+ (1,-60) [-60|194] "℃" TBOX

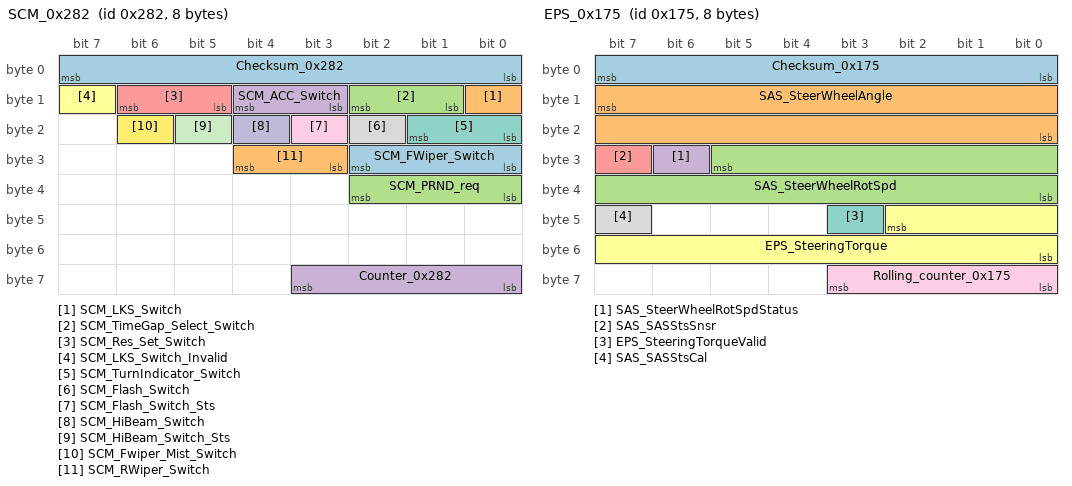
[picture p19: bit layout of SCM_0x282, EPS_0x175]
BO_ 642 SCM_0x282: 8 GW
 SG_ Checksum_0x282 : 7|8@0+ (1,0) [0|255] "" TBOX
 SG_ SCM_LKS_Switch : 8|1@0+ (1,0) [0|1] "" TBOX
 SG_ SCM_TimeGap_Select_Switch : 10|2@0+ (1,0) [0|3] "" TBOX
 SG_ SCM_ACC_Switch : 12|2@0+ (1,0) [0|3] "" TBOX
 SG_ SCM_Res_Set_Switch : 14|2@0+ (1,0) [0|3] "" TBOX
 SG_ SCM_LKS_Switch_Invalid : 15|1@0+ (1,0) [0|1] "" TBOX
 SG_ SCM_TurnIndicator_Switch : 17|2@0+ (1,0) [0|3] "" TBOX
 SG_ SCM_Flash_Switch : 18|1@0+ (1,0) [0|1] "" TBOX
 SG_ SCM_Flash_Switch_Sts : 19|1@0+ (1,0) [0|1] "" TBOX
 SG_ SCM_HiBeam_Switch : 20|1@0+ (1,0) [0|1] "" TBOX
 SG_ SCM_HiBeam_Switch_Sts : 21|1@0+ (1,0) [0|1] "" TBOX
 SG_ SCM_Fwiper_Mist_Switch : 22|1@0+ (1,0) [0|1] "" TBOX
 SG_ SCM_FWiper_Switch : 26|3@0+ (1,0) [0|7] "" TBOX
 SG_ SCM_RWiper_Switch : 28|2@0+ (1,0) [0|3] "" TBOX
 SG_ SCM_PRND_req : 34|3@0+ (1,0) [0|7] "" TBOX
 SG_ Counter_0x282 : 59|4@0+ (1,0) [0|15] "" TBOX

BO_ 373 EPS_0x175: 8 GW
 SG_ Checksum_0x175 : 7|8@0+ (1,0) [0|255] "" TBOX
 SG_ SAS_SteerWheelAngle : 15|16@0+ (0.0238,-780) [-780|779.733] "deg" TBOX
 SG_ SAS_SteerWheelRotSpd : 29|14@0+ (0.125,-1024) [-1024|1023.75] "deg/s" TBOX
 SG_ SAS_SteerWheelRotSpdStatus : 30|1@0+ (1,0) [0|1] "" TBOX
 SG_ SAS_SASStsSnsr : 31|1@0+ (1,0) [0|1] "" TBOX
 SG_ EPS_SteeringTorque : 42|11@0+ (0.01,-10.24) [-10.24|10.23] "Nm" TBOX
 SG_ EPS_SteeringTorqueValid : 43|1@0+ (1,0) [0|1] "" TBOX
 SG_ SAS_SASStsCal : 47|1@0+ (1,0) [0|1] "" TBOX
 SG_ Rolling_counter_0x175 : 59|4@0+ (1,0) [0|15] "" TBOX

BO_ 1424 VBU_BMS_0x590: 8 GW
 SG_ VBU_BMS_BattSerialNumber : 7|16@0+ (1,0) [0|9999] "" TBOX
 SG_ VBU_BMS_BattManuYear : 23|8@0+ (1,0) [0|255] "" TBOX
 SG_ VBU_BMS_BattManuMonth : 31|8@0+ (1,0) [0|255] "" TBOX
 SG_ VBU_BMS_BattManuDay : 39|8@0+ (1,0) [0|255] "" TBOX

BO_ 1425 VBU_BMS_0x591: 8 GW
 SG_ VBU_BMS_BattSupplierCode : 15|24@0+ (1,0) [0|16777215] "" TBOX
 SG_ VBU_BMS_ProductTypeCode : 39|8@0+ (1,0) [0|255] "" TBOX
 SG_ VBU_BMS_BattTypeCode : 47|8@0+ (1,0) [0|255] "" TBOX
 SG_ VBU_BMS_BattSpecCode : 55|16@0+ (1,0) [0|65535] "" TBOX

BO_ 1426 VBU_BMS_0x592: 8 GW
 SG_ VBU_BMS_BattRetrospectCode : 7|56@0+ (1,0) [1|72057594037927900] "" TBOX

BO_ 1427 VBU_BMS_0x593: 8 GW
 SG_ VBU_BMS_BattS_Num : 31|24@0+ (1,0) [0|16777215] "" TBOX
 SG_ VBU_BMS_BattRecycleCode : 55|16@0+ (1,0) [0|65535] "" TBOX

BO_ 1428 VBU_BMS_0x594: 8 GW
 SG_ VBU_BMS_BattCodeLenth : 7|8@0+ (1,0) [0|26] "" TBOX
 SG_ VBU_BMS_Temp_ProbeNum : 45|6@0+ (1,0) [0|63] "" TBOX
 SG_ VBU_BMS_PackageTotalNum : 47|2@0+ (1,0) [0|3] "" TBOX
 SG_ VBU_BMS_CellTotalNum : 55|8@0+ (1,0) [0|255] "" TBOX

BO_ 1429 VBU_BMS_0x595: 8 GW
 SG_ VBU_BMS_PackSOH : 6|7@0+ (1,0) [0|100] "%" TBOX
 SG_ VBU_BMS_RelayCutOffNum : 15|10@0+ (1,0) [0|1023] "" TBOX
 SG_ VBU_BMS_PackSOE : 21|10@0+ (0.1,0) [0|102.3] "kwh" TBOX
 SG_ VBU_BMS_TempDev_GBT32960 : 33|2@0+ (1,0) [0|3] "" TBOX
 SG_ VBU_BMS_TempOver_GBT32960 : 35|2@0+ (1,0) [0|3] "" TBOX
 SG_ VBU_BMS_CellVoltOver_GBT32960 : 37|2@0+ (1,0) [0|3] "" TBOX
 SG_ VBU_BMS_PackVoltOver_GBT32960 : 39|2@0+ (1,0) [0|3] "" TBOX
 SG_ VBU_BMS_CellVoltLow_GBT32960 : 41|2@0+ (1,0) [0|3] "" TBOX
 SG_ VBU_BMS_PackVoltLow_GBT32960 : 43|2@0+ (1,0) [0|3] "" TBOX
 SG_ VBU_BMS_BattOverCharge_GBT32960 : 45|2@0+ (1,0) [0|3] "" TBOX
 SG_ VBU_BMS_Iso_GBT32960 : 47|2@0+ (1,0) [0|3] "" TBOX
 SG_ VBU_BMS_SocSkip_GBT32960 : 48|1@0+ (1,0) [0|1] "" TBOX
 SG_ VBU_BMS_BattMismatch_GBT32960 : 49|1@0+ (1,0) [0|1] "" TBOX
 SG_ VBU_BMS_SocLow_GBT32960 : 51|2@0+ (1,0) [0|3] "" TBOX
 SG_ VBU_BMS_SocOverHigh_GBT32960 : 53|2@0+ (1,0) [0|3] "" TBOX
 SG_ VBU_BMS_CellVolDev_GBT32960 : 55|2@0+ (1,0) [0|3] "" TBOX
 SG_ VBU_BMS_ThermRunAway_GB38031 : 61|1@0+ (1,0) [0|1] "" TBOX
 SG_ VBU_BMS_RegenOverCurr_GB38031 : 63|2@0+ (1,0) [0|3] "" TBOX

CM_ "Version:V1.0,Date:10-1月-2020,Author:李明,Review:,Approval:,Description:()ME7_TboxCAN_Matrix_V301.191215版本基础作为IC321_TboxCAN_Matrix的V1.0版本;
Version:V1.1,Date:30-3月-2020,Author:李明,Review:,Approval:,Description:()TBOX删除接收HU_TBOXwelcomeReq_set;
Version:V1.1,Date:30-3月-2020,Author:李明,Review:,Approval:,Description:()HU_0x3A5新增发送HU_ICM_INFO_Enable、HU_RemoteCharge_StartHour、HU_RemoteCharge_Startmin、HU_RemoteCharge_Set、HU_ChargeCtrl_Set;
Version:V1.1,Date:30-3月-2020,Author:李明,Review:,Approval:,Description:()HU_0x3A5删除发送HU_mute_activests、HU_Voicecontrol_activests、HU_phonecall_worksts;
Version:V1.1,Date:30-3月-2020,Author:李明,Review:,Approval:,Description:()TBOX增加接收FLWM_DenormalizeSt、FRWM_DenormalizeSt、RLWM_DenormalizeSt、RRWM_DenormalizeSt;
Version:V1.1,Date:30-3月-2020,Author:李明,Review:,Approval:,Description:()TBOX_0x352增加发送TBOX_AC_FDefrostMode_Set;
Version:V1.1,Date:30-3月-2020,Author:李明,Review:,Approval:,Description:()TBOX_FOTA_wakeup信号从TBOX_0x353报文移到TBOX_0x352报文里发送;
Version:V1.1,Date:30-3月-2020,Author:陈威,Review:李明,Approval:,Description:()GW新增发送报文：VBU_BMS_0x103、VBU_BMS_0x114、VBU_0x142、GCU_0x21A、GCU_0x21B、EMS_0x272、EMS_0x273、VBU_0x561、AC_0x255、HU_0x2DE_PT、BCM_PEPS_0x222、BCM_PEPS_0x354，且TBOX增加接收报文及信号；;
Version:V1.1,Date:30-3月-2020,Author:陈威,Review:李明,Approval:,Description:()GW新增发送报文DSM_0x390,TBOX增加接收信号FLWM_Response_Err;
Version:V1.2,Date:30-5月-2020,Author:李明,Review:,Approval:,Description:()更新0x380报文内相关信号;
Version:V1.2,Date:30-5月-2020,Author:李明,Review:,Approval:,Description:()MCU_0x123删除发送MCU_WaterTemp;
Version:V1.2,Date:30-5月-2020,Author:李明,Review:,Approval:,Description:()TBOX增加接收DSM_PSMsettemp;
Version:V1.2,Date:30-5月-2020,Author:李明,Review:,Approval:,Description:()TBOX增加接收RLWM_WindowLOCKSts和RLWM_WindowLOCKSts;
Version:V1.2,Date:30-5月-2020,Author:李明,Review:,Approval:,Description:()TBOX增加接收CDU_0x3D3报文内的CDU_OBC_HVVolt、CDU_OBC_MaxChrgOutpVolt、CDU_OBC_MaxChrgOutpCur、CDU_OBC_HVCurr;
Version:V1.2,Date:30-5月-2020,Author:李明,Review:,Approval:,Description:()更新VBU_BMS_0x100的报文周期为50ms;
Version:V1.2,Date:30-5月-2020,Author:李明,Review:,Approval:,Description:()更新VBU_BMS_0x102的报文周期为50ms;
Version:V1.2,Date:30-5月-2020,Author:李明,Review:,Approval:,Description:()删除报文OBC_0x614、DCDC_0x660、OBC_0x610、OBC_0x550、OBC_0x611、DCDC_0x389
报文名DCDC_0x188改为CDU_0x188;
Version:V1.2,Date:30-5月-2020,Author:李明,Review:,Approval:,Description:()更新VBU_0x9B的报文周期为100ms;
Version:V1.2,Date:30-5月-2020,Author:李明,Review:,Approval:,Description:()删除报文VBU_0x372、VBU_0x373;
Version:V1.2,Date:30-5月-2020,Author:李明,Review:,Approval:,Description:()更新VBU_0x371报文内的所有信号定义;
Version:V1.2,Date:30-5月-2020,Author:李明,Review:,Approval:,Description:()更新VBU_0x9B报文内关于DC和OBC的信号定义;
Version:V1.2,Date:30-5月-2020,Author:李明,Review:,Approval:,Description:()TBOX新增接收CDU_0x250、CDU_0x3D1、CDU_0x3D2、CDU_0x3D3、CDU_0x188报文内相关信号;
Version:V1.2,Date:30-5月-2020,Author:李明,Review:,Approval:,Description:()更新HU_0x2DE_PT报文内信号定义;
Version:V1.2,Date:30-5月-2020,Author:李明,Review:,Approval:,Description:()GW新增路由VBU_BMS_0x103/VBU_BMS_0x114报文，TBOX接收;
Version:V1.2,Date:30-5月-2020,Author:李明,Review:,Approval:,Description:()TBOX新增接收ACU_DrvSeatBeltSWSts、ACU_PsSeatBeltSWSts、ACU_RLPsSeatBeltSWSts、ACU_MidPsSeatBeltSWSts、ACU_RRPsSeatBeltSWSts;
Version:V1.2,Date:30-5月-2020,Author:李明,Review:,Approval:,Description:()更新VBU_0x150和VBU_0x141报文内相关信号定义;
Version:V1.2,Date:30-5月-2020,Author:李明,Review:,Approval:,Description:()更新EMS_0x272的报文周期为50ms;
Version:V1.3,Date:15-10月-2020,Author:李明,Review:,Approval:,Description:()TBOX_0x353增加发送TBOX_BT_KeyDIstance、TBOX_VBU_V2XCtrlset 、TBOX_Ipc_ChargeLight_enable、TBOX_Ipc_ChrgLock_enable;
Version:V1.3,Date:15-10月-2020,Author:李明,Review:,Approval:,Description:()更新TBOX_VBU_TimeCharge的信号值描述;
Version:V1.3,Date:15-10月-2020,Author:李明,Review:,Approval:,Description:()更新TBOX_ChargeCtrl_Setsts的信号定义;
Version:V1.3,Date:15-10月-2020,Author:李明,Review:,Approval:,Description:()更新CDU_0x3D1、CDU_0x3D2、CDU_0x250、CDU_0x188、VBU_0x142、HU_0x2DE、VBU_0x150、VBU_BMS_0x102、VBU_BMS_0x105、VBU_BMS_0x114、VBU_BMS_0x115、VBU_0x9D、VBU_0x9C、VBU_0x142、VBU_0x371报文内相关信号定义;
Version:V1.3,Date:15-10月-2020,Author:李明,Review:,Approval:,Description:()TBOX新增接收CDU_0x610、CDU_0x611、VBU_BMS_0x595报文内相关信号定义;
Version:V1.3,Date:15-10月-2020,Author:李明,Review:,Approval:,Description:()TBOX新增发送TBOX_0x13B（预留ID）和新增接收VBU_0x13A（预留ID);
Version:V1.3,Date:15-10月-2020,Author:李明,Review:,Approval:,Description:()更新VBU_BMS_0x116报文内所有信号定义;
Version:V1.3,Date:15-10月-2020,Author:李明,Review:,Approval:,Description:()TBOX新增接收VBU_BMS_FastChargeInfo、VBU_BMS_FastChargeInf2报文内信号;
Version:V1.3,Date:15-10月-2020,Author:李明,Review:,Approval:,Description:()更新VBU_DCDCLVVoltSet的信号精度值;
Version:V1.3,Date:15-10月-2020,Author:李明,Review:,Approval:,Description:()更新VBU_BMS_State的信号值描述;
Version:V1.3,Date:15-10月-2020,Author:李明,Review:,Approval:,Description:()更新VBU_BMS_0x306、VBU_BMS_0x513、VBU_BMS_0x514、VBU_BMS_0x530、VBU_BMS_0x531、VBU_BMS_0x532、VBU_BMS_0x533、VBU_BMS_0x534、VBU_BMS_0x535、VBU_BMS_0x536、VBU_BMS_0x537、VBU_BMS_0x538、VBU_BMS_0x539、VBU_BMS_0x53A、VBU_BMS_0x53B、VBU_BMS_0x53C、VBU_BMS_0x53D、VBU_BMS_0x53E、VBU_BMS_0x53F、VBU_BMS_0x540、VBU_BMS_0x541、VBU_BMS_0x542、VBU_BMS_0x543、VBU_BMS_0x544、VBU_BMS_0x545、VBU_BMS_0x546、VBU_BMS_0x547、VBU_BMS_0x548、VBU_BMS_0x549、VBU_BMS_0x54A、VBU_BMS_0x5F0、VBU_BMS_0x5F1、VBU_BMS_0x5F2、VBU_BMS_0x5F3、VBU_BMS_0x5F4、VBU_BMS_0x5F5、VBU_BMS_0x5F6、VBU_BMS_0x5F7、VBU_BMS_0x5F8、报文内相关信号值描述;
Version:V1.3,Date:15-10月-2020,Author:李明,Review:,Approval:,Description:()TBOX增加接收ICM_0x5A1、ICM_0x5A2、ICM_0x5A3、ICM_0x5A4、ICM_0x5A5;
Version:V1.4,Date:30-11月-2020,Author:李明,Review:,Approval:,Description:()TBOX_0x355增加发送TBOX_FOTA_mode_ALL;
Version:V1.4,Date:30-11月-2020,Author:李明,Review:,Approval:,Description:()TBOX_0x352删除发送TBOX_FOTA_wakeup;
Version:V1.4,Date:30-11月-2020,Author:李明,Review:,Approval:,Description:()TBOX_0x351删除发送TBOX_DSM_GetMemoryReq;
Version:V1.4,Date:30-11月-2020,Author:李明,Review:,Approval:,Description:()更新VBU_CDU_Current_power和VBU_CDU_MaxCurrent_power的信号定义;
Version:V1.4,Date:30-11月-2020,Author:李明,Review:,Approval:,Description:()TBOX取消接收VBU_TBOX_V2XFeedbackAlarm;
Version:V1.4,Date:30-11月-2020,Author:李明,Review:,Approval:,Description:()TBOX增加接收VBU_BMS_ThermRunAway;
Version:V1.4,Date:30-11月-2020,Author:李明,Review:,Approval:,Description:()更新VBU_BMS_0x306报文内VBU_BMS_RemainChargingTime的信号长度和VBU_BMS_Charing_Time的信号起始位;
Version:V1.4,Date:30-11月-2020,Author:李明,Review:,Approval:,Description:()TBOX取消接收VBU_BMS_0x103报文内信号;
Version:V1.4,Date:30-11月-2020,Author:李明,Review:,Approval:,Description:()更新VBU_BMS_0x105报文内信号定义;
Version:V1.4,Date:30-11月-2020,Author:李明,Review:,Approval:,Description:()更新VBU_BMS_0x114报文内信号定义;
Version:V1.4,Date:30-11月-2020,Author:李明,Review:,Approval:,Description:()TB0X取消接收VBU_BMS_0x115报文内VBU_BMS_Current_power，增加接收VBU_0x371报文内VBU_BMS_Current_power;
Version:V1.4,Date:30-11月-2020,Author:李明,Review:,Approval:,Description:()TBOX_0x221增加发送TBOX_DischargeDepthSet;
Version:V1.4,Date:30-11月-2020,Author:李明,Review:,Approval:,Description:()TBOX_0x353增加发送TBOX_APS_EPSStrgWhlAngZero;
Version:V1.4,Date:30-11月-2020,Author:李明,Review:,Approval:,Description:()TBOX增加接收HU_0x3A5报文内相关信号;
Version:V1.4,Date:30-11月-2020,Author:李明,Review:,Approval:,Description:()更新VBU_0x52D、VBU_0x52E、VBU_0x52F报文内的信号定义;
Version:V1.4,Date:30-11月-2020,Author:李明,Review:,Approval:,Description:()TBOX_0x353报文取消发送TBOX_VBU_V2XCtrlset;
Version:V1.4,Date:30-11月-2020,Author:李明,Review:,Approval:,Description:()TBOX增加接收VBU_VehicleModel;
Version:V1.4,Date:30-11月-2020,Author:李明,Review:,Approval:,Description:()AVM节点名字改为APS，所有以AVM开头信号改为以APS开头;
Version:V1.4,Date:30-11月-2020,Author:李明,Review:,Approval:,Description:()更新APS_0x191报文内的信号定义;
Version:V1.4,Date:30-11月-2020,Author:李明,Review:,Approval:,Description:()VBU_0x561删除发送VBUwakeupOBC、VBU_VBUwakeupDC_GCU、VBUwakeupMCU，增加发送VBU_wakeupCDU、VBU_VBUwakeupGCU;
Version:V1.4,Date:30-11月-2020,Author:李明,Review:,Approval:,Description:()BCM_0x310报文内删除BCM_PUSH_Switc_Sts，新增BCM_WinCloseReminder，TBOX接收;
Version:V1.4,Date:30-11月-2020,Author:李明,Review:,Approval:,Description:()TBOX删除接收HU_0x2DF_Body报文内信号;
Version:V1.5,Date:06-1月-2021,Author:陈威,Review:,Approval:,Description:(GW)1.GW路由报文VBU_0x561中新增信号VBU_ThermRunAwaywakeup，TBOX增加接收该信号；
2.GW增加发送VBU_BMS_FastChargeInf3 0x5AC报文，且TBOX接收所有信号VBU_ChrFast_Current_power，VBU_ChrFast_MaxCurrent_power;
Version:V1.5,Date:06-1月-2021,Author:陈威,Review:,Approval:,Description:(TBOX)1.TBOX增加接收报文VBU_0x561中VBU_ThermRunAwaywakeup信号；
2.TBOX接收VBU_BMS_FastChargeInf3 0x5AC报文中VBU_ChrFast_Current_power，VBU_ChrFast_MaxCurrent_power信号;
Version:V1.5,Date:06-1月-2021,Author:陈威,Review:,Approval:,Description:(TBOX)更新VBU_0X9C报文中VBU_AuthSts信号的coding值改为：0x0: 未认证，0x3: 认证正在进行;
Version:V1.6,Date:01-2月-2021,Author:陈威,Review:,Approval:,Description:(TBOX)增加接收报文0x116报文中的信号VBU_GearAntiTheftWarning，VBU_UIDisplay;
Version:V1.6,Date:01-2月-2021,Author:陈威,Review:,Approval:,Description:(TBOX)修改VBU_BMS_0x116报文中信号VBU_UIDisplay的coding值描述0x6: 直流放电;
Version:V1.6,Date:01-2月-2021,Author:陈威,Review:,Approval:,Description:(TBOX)1.VBU_BMS_0x590 更改VBU_BMS_BattSerialNumber/VBU_BMS_BattManuYear/VBU_BMS_BattManuMonth/VBU_BMS_BattManuDay物理最小值、物理最大值、总线最小值、总线最大值。
2.VBU_BMS_0x592 更改VBU_BMS_BattRetrospectCode总线最小值和初始值
3.VBU_BMS_0x593 更改VBU_BMS_BattS_Num/VBU_BMS_BattReCycleCode初始值
4.VBU_BMS_0x594 VBU_BMS_BattCodeLenth 更改物理最小值、总线最小值、初始值;
Version:V1.6,Date:01-2月-2021,Author:陈威,Review:,Approval:,Description:(TBOX)增加接收VBU_0x371报文中信号：
1.增加接收VBU_BattTempLowCharge信号
2.增加接收VBU_BattEnergyLim信号
3.增加接收VBU_ FrequentPowerupWaring信号
4.增加接收VBU_ NSlipBackWaring信号;
Version:V1.6,Date:01-2月-2021,Author:陈威,Review:,Approval:,Description:(TBOX)1.取消接收报文中APS_0x191中信号APS_HU_Failure：
2.更新报文APS_0x191中信号APS_SystemSts的coding值0x7改为：Suspend；
3.删除报文APS_0x191中信号APS_AVM_ControlRequest,此位置更新新增为信号APS_AVM_HU_CurrentSts
4.删除报文APS_0x191中信号APS_AVM_SoftKeyResponse
5.删除报文APS_0x191中信号APS_RearViewFoldReq;
Version:V1.6,Date:10-2月-2021,Author:陈威,Review:,Approval:,Description:(TBOX)更新报文APS_0x271报文中信号APS_AutoSearchSts的coding值描述;
Version:V1.6,Date:10-2月-2021,Author:陈威,Review:,Approval:,Description:(TBOX)增加接收HU_0x3A3报文所有信号;
Version:V1.6,Date:10-2月-2021,Author:陈威,Review:,Approval:,Description:(TBOX)将0X355报文中的TBOX_FOTA_mode_ALL信号移至0x221报文中，信号起始位为11;
Version:V1.6,Date:10-2月-2021,Author:陈威,Review:,Approval:,Description:(TBOX)修改报文VBU_0x9C发送类型为CE，其信号VBU_Cruise_Warning的信号发送类型为onchange;
Version:V1.6,Date:10-2月-2021,Author:陈威,Review:,Approval:,Description:(TBOX)增加发送报文0x221中信号TBOX_DVR_RemoteFunctionCtrl，起始位为bit15;
Version:V1.6,Date:10-2月-2021,Author:陈威,Review:,Approval:,Description:(GW)增加从PTCAN路由报文TPCV1_0x318/TPCV2_0x319到TBOXCAN;
Version:V1.6,Date:25-2月-2021,Author:陈威,Review:,Approval:,Description:(TBOX)修改MCU_0x122报文中MCU_damping_En信号的信号长度，信号最大值，位排布及信号coding值;
Version:V1.6,Date:25-2月-2021,Author:陈威,Review:,Approval:,Description:(TBOX)将报文BCM_0x310中的BCM_WinCloseReminder信号挪到报文BCM_0x330中并修改信号发送类型/信号长度/最大值及coding值描述；同时修改报文BCM_0x330发送类型为CE;
Version:V1.6,Date:25-2月-2021,Author:陈威,Review:,Approval:,Description:(TBOX)修正报文0x221中信号TBOX_DVR_RemoteFunctionCtrl的coding值;
Version:V1.6,Date:25-2月-2021,Author:陈威,Review:,Approval:,Description:(TBOX)报文TBOX_0X353报文增加发送信号TBOX_FOTA_wakeup;
Version:V1.6,Date:25-2月-2021,Author:陈威,Review:,Approval:,Description:(TBOX)增加发送报文TBOX_0X221报文中的信号TBOX_ECALL_mode_ALL，起始位bit12；;
Version:V1.6,Date:25-2月-2021,Author:陈威,Review:,Approval:,Description:(TBOX)增加接收报文HU_0x322报文中的信号HU_MCUResetReason/HU_HardACCState/HU_MCUPowerState/HU_SOCWatchdog/HU_SOCResetType/HU_SPIConnectState/HU_BatteryVoltage/HU_BCMSystemPowerMode;
Version:V1.6,Date:25-2月-2021,Author:陈威,Review:,Approval:,Description:(TBOX)取消接收报文HU_0x3A5报文中的信号HU_MCUResetReason/HU_HardACCState/HU_MCUPowerState/HU_SOCWatchdog/HU_SOCResetType/HU_SPIConnectState/HU_BatteryVoltage/HU_BCMSystemPowerMode;
Version:V1.7,Date:12-4月-2021,Author:陈威,Review:,Approval:,Description:(TBOX)修改VBU_BMS_0x590报文中VBU_BMS_BattSerialNumber信号描述改为十进制数解析
修改VBU_BMS_0x592报文中VBU_BMS_BattRetrospectCode信号描述增加ASCII码解析;
Version:V1.7,Date:12-4月-2021,Author:陈威,Review:,Approval:,Description:(TBOX)VBU_0x561报文增加发送VBU_RemoteChargeSts/VBU_ChrgLockEnable/VBU_LockPinSts/VBU_UnlockPinSts信号，发送给TBOX;
Version:V1.7,Date:12-4月-2021,Author:陈威,Review:,Approval:,Description:(TBOX)VBU_BMS_0x116报文中新增信号保电模式提醒VBU_GuaranteedPwr;
Version:V1.7,Date:12-4月-2021,Author:陈威,Review:,Approval:,Description:(TBOX)增加发送TBOX_0x221中的TBOX_RemoteCharge_EndHour/TBOX_RemoteCharge_Full_SetSts/TBOX_RemoteCharge_Endmin/TBOX_RemoteCharge_wakeup_SetSts信号;
Version:V1.7,Date:12-4月-2021,Author:陈威,Review:,Approval:,Description:(TBOX)增加接收报文HU_0x3A5中信号HU_RemotCh_Full_SetSts/HU_RemoteCharge_EndHour/HU_RemoteCharge_Endmin;
Version:V1.7,Date:12-4月-2021,Author:陈威,Review:,Approval:,Description:(TBOX)修改报文TBOX_0x221中的TBOX_DVR_RemoteFunctionCtrl信号发送类型为cycle;
Version:V1.7,Date:12-4月-2021,Author:陈威,Review:,Approval:,Description:(TBOX)修改报文TBOX_0x352中的TBOX_RemoteCharge_Setsts以及TBOX_0x221中的TBOX_RemoteCharge_Full_Setsts信号的长度和位排布及信号值描述;
Version:V1.7,Date:12-4月-2021,Author:陈威,Review:,Approval:,Description:(TBOX)企标数据上传需求：
1.完善接收所有GW_IBS_0x334中信号；
2.完善接收MCU_0x562中MCU_MotoroffsetCalReq信号；
3.完善接收所有DSM_0x390中所有信号；
4.完善接收报文0x121中的ESP_OFF信号；
5.增加接收报文：MCU_0x5E2_Version/HU_0x2DF_Body/BCM_PEPS_0x40/BCM_0x340/CDU_0x5E3_Version/DSM_0x391/BCM_LIN2_CSW_0x321/ESP_0x243/VBU_0x32B/ICM_0x5EF_Version及所有信号;
Version:V1.7.1,Date:16-4月-2021,Author:陈威,Review:,Approval:,Description:(TBOX)修改HU_0x3A5报文中发送信号HU_RemoteCharge_EndHour/HU_RemoteCharge_Endmin/HU_RemotCh_Full_SetSts的发送类型为on change；
TBOX_0x352中增加发送TBOX_HU_rebootACK信号给HU;
Version:V1.7.1,Date:16-4月-2021,Author:陈威,Review:,Approval:,Description:(TBOX)原BCM报文BCM_0x247报文中信号BCM_StartWarning/BCM_PowerOffWarning/BCM_PowerONWarning信号值描述为IC421项目，现修正信号值描述内容;
Version:1.7.2,Date:29-4月-2021,Author:陈威,Review:,Approval:,Description:(TBOX)增加接收报文ICM_0x3A0/ACU_0x210/ACU_0x254/DVR_0x3F1/DSM_0X2A4/中所有已有信号;
Version:1.8,Date:01-6月-2021,Author:陈威,Review:,Approval:,Description:(TBOX)1.修改报文VBU_BMS_0x116中VBU_AcSysFultSts、VBU_BMS_DCSysFultSts信号值描述，简化故障提醒；
2.0x52F中的信号VBU报文0x52F的VBU_ErrorAction1/VBU_ErrorAction2/VBU_ErrorAction3/VBU_ErrorAction4值按照16进制显示进行更改。
3.0x563中增加VBU_ACChargeSocketTemp交流充电插座温度和VBU_DCChargeSocketTemp直流充电插座温度信号；
4.报文中VBU_0x371中信号VBU_FrequentPowerupWaring信号改为预留，默认发0；
5.报文VBU_0x141中VBU_EnergyMode信号值变更，增加0x3：HybridMode；
6.修改HU_0x2DE_PT报文中HU_EnergyMode信号值为0x4：HybridMode；
7.VBU_0x117增加发送信号VBU_SOCLow_ENGStart  SOC低发动机自启动时刻对应SOC值；
8.报文0x52C增加接收信号VBU_FanPWMFeedback信号；
9.增加接收EPS_0x260报文及其信号
10.4.报文VBU_0x371增加接收信号VBU_ExtremeColdModeVBU反馈极寒模式；;
Version:1.8,Date:01-6月-2021,Author:陈威,Review:,Approval:,Description:(GW)增加发送EPS_0x260报文及信号;
Version:V3.0,Date:28-6月-2021,Author:陈威,Review:,Approval:,Description:(TBOX)泊车相关变更：
1.修改APS_0x271报文中APS_RemoteParkIn_Status的0x0/0x6/0x7信号值描述；
2.报文APS_0x271中新增APS_APP_RPA_Status信号；
3.报文APS_0x271中删除APS_ParkOutSystemStatus APA，APS_CurrentStepNum ，APS_RemoteParkInResp，APS_RemoteParkOutResp，APS_RemotePark_Error_Status 信号；
4.修改报文0x271中信号APS_CurrentParkType的0x1/0x2/0x3/0x4值描述；及信号APS_TerminatedType的0x2值描述改为reserved；修改信号APS_SuspendedReason的0x1/0x6/0x7值描述；修改APS_OverrideReason信号的0x2/0x3/0x4/0x5/0x6的值描述；修改APS_AbortReason信号所有值描述；
5.新增接收APS_ParkDirection 信号；
6.删除报文APS_0x191中APS_VBU_BrakeFunctionMode/APS_TBOXConect_ParkInResp/APS_VBU_FailureBrakeMode/ APS_VBU_Req_StraightOut/APS_VBU_Req_StraightCtrol
7.修改报文APS_0x191中APS_VBU_BrakeModeSts信号的0x3/0x4/0x5的值改为预留
8.DSM_0x2A4删除发送DSM_MemoryAlarm、DSM_DseatMemoryPosition； 
9.DSM_DeleteMemoryRsp信号名错误，替换为DSM_GetMemoryRsp_Mirror信号；
10.更新DSM_GetMemoryRsp信号名为DSM_GetMemoryRsp_Seat，原信号值描述（0x1:删除成功
0x2:删除失败/0x3:预留 ）改为0x1: 调节成功/0x2: 调节失败/0x3: 调节中断；
11.修改报文TBOX_0x353中TBOX_APS_RequstRemoteParkIn信号名为TBOX_APS_QuitRemotePark 遥控退出泊入指令；
12.删除报文TBOX_0x353中TBOX_APS_StartRemoteParkOut信号，且TBOX_APS_RequstRemoteParkOut信号(TBOX遥控泊出方向指令)改为2bit，信号值修改为：0x0: NoRequest/0x1: not select/0x2: left side/0x3:right side；
13.APS_0x270中信号APS_FailureBrakeMode、APS_BrakeModeSts、APS_ESP_Stop_Distance、APS_BrakeFunctionMode、APS_ESP_Speed_Limitation、APS_ESC_Target_Gear_Request改为预留;
Version:V3.0,Date:28-6月-2021,Author:陈威,Review:,Approval:,Description:(TBOX)1.增加接收HU_0X2DE中HU_RestSwitch_Set信号；
2.增加接收报文VBU_0x117中VBU_RestMode_Sts信号；
3.增加接收报文EAC_0x320中EAC_motor_desync电动压缩机电机失步信号；
4.报文VBU_0x141中信号VBU_APS_LC_Availability，VBU_APS_LC_FailureSts，VBU_APS_LC_Status预留；
5.文VBU_0x151中VBU_APS_WorkStatus信号改为预留；
6.修改报文CDU_0x3D2中CDU_OBC_ACHVILSts信号定义修改0x3：reserved为0x3:Invalid
7.修改报文CDU_0x188中CDU_DC_HVHVILSts信号定义修改0x3：reserved为0x3:Invalid
8.新增接收报文HU_0x2A2中信号HU_APS_Audio_Active/HU_Audio_AP_Request/HU_Audio_Request_Command/HU_APS_FunSW/HU_AVM_ViewModeSwitch
HU_Display_Mode_APA
9.修改BCM_0x380报文中信号RLS_RQ_LowBeam字节长度为2，且位排布起始bit为55，及信号值描述：0x0: default/0x1: No RQ on Low Beam/0x2:RQ on Low Beam/0x3:Reserved（解锁迎宾需求变更）；
10.报文BCM_0x247增加接收BCM_HoodOpen_Feedback/BCM_TrunkOpen_Feedback/BCM_Drivedoorlcok_Feedback/BCM_FLDoorOpen_Feedback/BCM_FRDoorOpen_Feedback/BCM_RRDoorOpen_Feedback/BCM_RLDoorOpen_Feedback/BCM_FLWindowOpen_Feedback/BCM_FRWindowOpen_Feedback/BCM_RRWindowOpen_Feedback（安防功能需求）;
Version:V3.0,Date:28-6月-2021,Author:陈威,Review:,Approval:,Description:(GW)增加发送报文ESP_0x211/EPS_0X244/EPS_0X176/EPS_0X177;
Version:V3.0,Date:28-6月-2021,Author:陈威,Review:,Approval:,Description:(TBOX)1.增加接收报文ESP_0x211/EPS_0X244/EPS_0X176/EPS_0X177及信号用于企标数据上传；
2.变更ACU_0x210中ACU_SBR_RLPassenger/ACU_SBR_MidPassenger/ACU_SBR_RRPassenger信号值描述：0x2:flash and buzzing/0x3:Seat mark lamp on;
Version:V3.0,Date:05-7月-2021,Author:陈威,Review:,Approval:,Description:(TBOX)1.修改报文ICM_0x5A3中信号ICM_trip_EV/ICM_trip_EREV信号的精度为3，物理最大值为999；
2.修改报文ICM_0x5A4中信号ICM_TotalTime_ALL的信号长度及最大值和无效值和单位；
3.修改报文ICM_0x5A5中信号ICM_triptime_EV/ICM_triptime_EREV/ICM_TotalTime_EREV/ICM_TotalTime_EV的信号长度及位排布，物理最大值无效值和单位。;
Version:V3.1,Date:06-9月-2021,Author:陈威,Review:,Approval:,Description:(TBOX)1.报文DSM_0x390中DSM_WorkMode信号值新增0x6：后视镜调节模式；
2.报文DSM_0x390中DSM_CalibrationAlarm信号改为预留；
3.报文DSM_0x391中DSM_Seat_Calibration信号改为预留；
4.报文DSM_0x391增加副驾电机相关信号PSM_SLV_DirectionSts、PSM_SLV_MotorfaultSts、PSM_LNV_DirectionSts、PSM_LNV_MotorfaultSts及WakeUpSource信号；;
Version:V3.1,Date:06-9月-2021,Author:陈威,Review:,Approval:,Description:(TBOX)取消接收报文VBU_0x140（源网段PTCAN已停发，已移至PrCAN）;
Version:V3.1,Date:29-10月-2021,Author:陈威,Review:,Approval:,Description:(TBOX)1.0x52C增加VBU_CrashStatus碰撞状态信号。
2.报文0x117新增VBU_PowerSwitchON_HEV VBU发送上ON提醒；
3.报文0x117新增VBU_StartEngineReminder_HEV VBU发送启动发动机提醒；
4.报文0x117新增VBU_ExitDschReminder_HEV 即将结束放电提醒_HEV
5.报文0x117新增VBU_ExitDschReminder_EV 即将结束放电提醒_EV
6.更新0x52F中VBU_ErrorAction1/VBU_ErrorAction2/VBU_ErrorAction3/VBU_ErrorAction4中所有信号值描述
7.0x595新增VBU_BMS_ThermRunAway_GB38031、VBU_BMS_RegenOverCurr_GB38031
8.VBU_0x117增加发送VBU_SOCLowDisACRemind低SOC关闭舒适性空调提醒（HEV）
9.VBU_0x117报文的VBU_RestMode_Sts信号值改为0x0: OFF、0x1: ON
10.修改0x105报文中:VBU_BMS_Insulation_positive和VBU_BMS_Insulation_negative的信号值最大值及解析0x3FD: Max
11. 修改报文0x306中信号名称VBU_BMS_Totalcharging_Ah：累计充电量修改为VBU_BMS_TotalUsed_Ah：充放电累计吞吐安时;
 ";

CM_ SG_ 374 EPS_Checksum_0x176 "Checksum: IDMSB XOR IDLSB XOR Byte1 XOR Byte2 XOR Byte3 XOR Byte4 XOR Byte5 XOR Byte6XOR Byte7";
CM_ SG_ 374 EPS_LKA_TJA_ResponseTorque " EPS对LKA/TJA控制器请求的扭矩响应值，左正右负
EPS feedback LKA Response Torque,left+/right-";
CM_ SG_ 374 EPS_LKA_TJA_ResponseTorqueValid "Validation bit of  LKA/TJAResponseTorque";
CM_ SG_ 374 EPS_LKA_TJA_ControlStatus "EPS feedback LKA/TJA Control Status";
CM_ SG_ 374 Rolling_counter_0x176 "RollingCounter: used 4bit length signal and the arithmetic is increased from 0 to 15 by every message.";
CM_ SG_ 375 Checksum_0x177 "Checksum: IDMSB XOR IDLSB XOR Byte1 XOR Byte2 XOR Byte3 XOR Byte4 XOR Byte5 XOR Byte6XOR Byte7";
CM_ SG_ 375 EPS_EPSAPASts "Electric Power Steering Advanced Park Assist Status ，maximum signal value is 0xF but Signal Value Description is available only for 0 to 7 ，others Reserved，当EPS_EPSAPASts=active时自动泊车允许控制转向";
CM_ SG_ 375 EPS_EPSAPAInh "Electric Power Steering Advanced Park Assist Inhibit。maximum signal value is 0xFF but Signal Value Description is available only for 0,1,2,4,8 and 10，others Reserved";
CM_ SG_ 375 Rolling_counter_0x177 "RollingCounter: used 4bit length signal and the arithmetic is increased from 0 to 15 by every message.";
CM_ SG_ 529 Checksum_0x211 "Checksum: IDMSB XOR IDLSB XOR Byte1 XOR Byte2 XOR Byte3 XOR Byte4 XOR Byte5 XOR Byte6 XOR Byte7";
CM_ SG_ 529 ABS_WheelSpeed_FL "Current wheel speed information of front left wheel.
左前轮轮速";
CM_ SG_ 529 ABS_WheelSpeed_FR "Current wheel speed information of front right wheel.
右前轮轮速";
CM_ SG_ 529 ABS_WheelSpeed_RL "Current wheel speed information of rear left wheel.
左后轮轮速";
CM_ SG_ 529 ABS_WheelSpeed_RR "Current wheel speed information of rear right wheel.
右后轮轮速";
CM_ SG_ 529 RollingCounter_0x211 "RollingCounter: used 4bit length signal and the arithmetic is increased from 0 to 15 by every message.";
CM_ SG_ 529 ABS_WheelSpeed_FL_Valid "Front left wheel speed valid
左前轮速有效";
CM_ SG_ 529 ABS_WheelSpeed_FR_Valid "Front right wheel speed valid
右前轮速有效";
CM_ SG_ 529 ABS_WheelSpeed_RL_Valid "Rear left wheel speed valid 
左后轮速有效";
CM_ SG_ 529 ABS_WheelSpeed_RR_Valid "Rear right wheel speed valid
右后轮速有效";
CM_ SG_ 580 Checksum_0x244 "Checksum: IDMSB XOR IDLSB XOR Byte1 XOR Byte2 XOR Byte3 XOR Byte4 XOR Byte5 XOR Byte6 XOR Byte7";
CM_ SG_ 580 ESP_VLC_InternalTgtAx "Calculated VLC internal target deceleration.";
CM_ SG_ 580 ESP_HBA_Intervention "HBA controller active: The brake assist functions support the driver in case of an emergency or panic situation.";
CM_ SG_ 580 ESP_AWB_Available "Check whether AWB function is available or not.";
CM_ SG_ 580 ESP_AWB_Intervention "AWB active";
CM_ SG_ 580 ESP_ABA_Available "Check whether ABA function is available or not.";
CM_ SG_ 580 ESP_ABA_Intervention "Indicates ABA is active or not";
CM_ SG_ 580 ESP_ABP_Available "Check whether ABP function is available or not.";
CM_ SG_ 580 ESP_ABP_Intervention "Indicates ABP is active or not";
CM_ SG_ 580 ESP_VirtualGaspadelPosReq "ESC_VirtualGaspadelPosReq";
CM_ SG_ 580 ESC_CDPIntervention "Indicates CDP control active";
CM_ SG_ 580 ESC_CDPErrorSt "HMI Responsible,CAN get degrateCDP statement from DSW and send out";
CM_ SG_ 580 RollingCounter_0x244 "RollingCounter: used 4bit length signal and the arithmetic is increased from 0 to 15 by every message.";
CM_ SG_ 674 HU_APS_Audio_Active "语音激活泊车开启";
CM_ SG_ 674 HU_Audio_AP_Request "HU_Audio_AP_Request
语音泊车控制请求";
CM_ SG_ 674 HU_Audio_Request_Command "语音控制请求";
CM_ SG_ 674 HU_APS_FunSW "APS雷达报警开关";
CM_ SG_ 674 HU_AVM_ViewModeSwitch "Hu给AVM/APS发送视图切换请求";
CM_ SG_ 674 HU_Display_Mode_APA "白天夜晚模式";
CM_ SG_ 608 EPS_SafeLampRed "The safe lamp (red)
红色警示灯-EPS严重故障";
CM_ SG_ 608 EPS_WarningLampYellow "The warning lamp (yellow)
黄色警示灯-不影响功能的故障";
CM_ SG_ 608 EPS_DTCFlag " DTC Flag";
CM_ SG_ 608 EPS_DriveModeSts "EPS驾驶模式状态";
CM_ SG_ 608 EPS_HU_DriveModeSetEn "驾驶模式开关请求设置使能状态";
CM_ SG_ 1519 ICM_SWVersion_Supplier "ICM软件供应商代码（有天际定义，如A/B/C分别代表A点/B点/C点供应商，定义参考诊断规范版本号定义）";
CM_ SG_ 1519 ICM_SWVersion_Main "ICM软件版本-大版本";
CM_ SG_ 1519 ICM_SWVersion_Sub1 "ICM软件版本-小版本第一位";
CM_ SG_ 1519 ICM_SWVersion_Sub2 "ICM软件版本-小版本第二位";
CM_ SG_ 1519 ICM_HWVersion_Supplier "ICM硬件件供应商代码";
CM_ SG_ 1519 ICM_HWVersion_Main "ICM硬件版本-大版本";
CM_ SG_ 1519 ICM_HWVersion_Sub1 "ICM硬件版本-小版本第一位";
CM_ SG_ 1519 ICM_HWVersion_Sub2 "ICM硬件版本-小版本第二位";
CM_ SG_ 811 VBU_WakeUpRMCU "VBU唤醒MCU信号，适用后驱
注意：此报文为事件性报文，需要时按照100ms周期发送，不需要时停止发送。";
CM_ SG_ 579 Checksum_0x243 "Checksum: IDMSB XOR IDLSB XOR Byte1 XOR Byte2 XOR Byte3 XOR Byte4 XOR Byte5 XOR Byte6XOR Byte7";
CM_ SG_ 579 ESP_YawRateValue "yaw rate signal
横摆角速度";
CM_ SG_ 579 ESP_YawrateValue_valid "yaw rate signal value valid or not.横摆角速度信号是否有效";
CM_ SG_ 579 ESP_LongAccSensor "vehicle longitudinal acceleration
车辆纵向加速度";
CM_ SG_ 579 ESP_LongAccSensorValid "vehicle longitudinal acceleration  value valid or not.
车辆纵向加速度信号是否有效";
CM_ SG_ 579 ESP_LaterAccSensor "vehicle lateral acceleration
车辆横向加速度";
CM_ SG_ 579 ESP_LaterAccSensorValid "vehicle lateral acceleration value valid or not.
车辆横向加速度信号是否有效";
CM_ SG_ 579 ESP_AEB_Intervention "Indicates AEB is active or not";
CM_ SG_ 579 RollingCounter_0x243 "RollingCounter: used 4bit length signal and the arithmetic is increased from 0 to 15 by every message.";
CM_ SG_ 913 DSM_Horizontalforward "主驾驶座椅水平向前调节开关状态";
CM_ SG_ 913 DSM_HorizontalBackward "主驾驶座椅水平后前调节开关状态";
CM_ SG_ 913 DSM_Liftup "主驾驶座椅向上抬高调节开关状态";
CM_ SG_ 913 DSM_LiftDown "主驾驶座椅向下调低调节开关状态";
CM_ SG_ 913 DSM_Backforward "主驾驶座椅靠背向前调节开关状态";
CM_ SG_ 913 DSM_BackBackward "主驾驶座椅靠背向后调节开关状态";
CM_ SG_ 913 DSM_PSMHorizontalforward "副驾驶座椅水平向前调节开关状态";
CM_ SG_ 913 DSM_PSMHorizontalBackward "副驾驶座椅水平后前调节开关状态";
CM_ SG_ 913 DSM_PSMBackforward "副驾驶座椅靠背向前调节开关状态";
CM_ SG_ 913 DSM_PSMBackBackward "副驾驶座椅靠背向后调节开关状态";
CM_ SG_ 913 DSM_Seat_Calibration "主驾驶座电机标定状态（信号预留）";
CM_ SG_ 913 PSM_SLV_DirectionSts "副驾座椅前后调节电机（SLV）运动方向";
CM_ SG_ 913 PSM_SLV_MotorfaultSts "副驾座椅前后调节电机（SLV）故障状态";
CM_ SG_ 913 PSM_LNV_DirectionSts "副驾支架靠背电机（LNV）运动方向";
CM_ SG_ 913 PSM_LNV_MotorfaultSts "副驾驾靠背电机（LNV）故障状态";
CM_ SG_ 913 WakeUpSource "唤醒源(A点使用)";
CM_ SG_ 1507 CDU_SWVersion_Supplier "CDU软件供应商代码（有天际定义，如A/B/C分别代表A点/B点/C点供应商，定义参考诊断规范版本号定义）";
CM_ SG_ 1507 CDU_SWVersion_Main "CDU软件版本-大版本";
CM_ SG_ 1507 CDU_SWVersion_Sub1 "CDU软件版本-小版本第一位";
CM_ SG_ 1507 CDU_SWVersion_Sub2 "CDU软件版本-小版本第二位";
CM_ SG_ 1507 CDU_HWVersion_Supplier "CDU硬件件供应商代码";
CM_ SG_ 1507 CDU_HWVersion_Main "CDU硬件版本-大版本";
CM_ SG_ 1507 CDU_HWVersion_Sub1 "CDU硬件版本-小版本第一位";
CM_ SG_ 1507 CDU_HWVersion_Sub2 "CDU硬件版本-小版本第二位";
CM_ SG_ 801 CSW_Key_APA_GW "APA按钮状态（高配）";
CM_ SG_ 801 CSW_Key_AVAS_GW "CSW上的AVAS按钮状态（从LIN2 CSW_0x21报文相同信号转发而来）";
CM_ SG_ 801 CSW_Key_CenterLock_GW "中控锁按钮状态（从LIN2 CSW_0x21报文相同信号转发而来）";
CM_ SG_ 801 CSW_Key_FrontDefrost_GW "前风窗除雾按钮状态（从LIN2 CSW_0x21报文相同信号转发而来）";
CM_ SG_ 801 CSW_Key_RearDefrost_GW "后风窗除雾/后视镜加热按钮状态（从LIN2 CSW_0x21报文相同信号转发而来）";
CM_ SG_ 801 CSW_Key_LiftGate_GW "后背门开启按钮状态（从LIN2 CSW_0x21报文相同信号转发而来）";
CM_ SG_ 801 CSW_WindowLOCK_GW "车窗锁止按钮状态（从LIN2 CSW_0x21报文相同信号转发而来）";
CM_ SG_ 801 CSW_ResponseError_GW "CSW LIN response error （从LIN2 CSW_0x21报文相同信号转发而来）";
CM_ SG_ 801 CSW_VoltageTooLow_GW "电池电压过低（从LIN2 CSW_0x21报文相同信号转发而来）";
CM_ SG_ 801 CSW_VoltageTooHigh_GW "电池电压过高（从LIN2 CSW_0x21报文相同信号转发而来）";
CM_ SG_ 801 CSW_PWMError_GW "PWM故障（频率或占空比非法）（从LIN2 CSW_0x21报文相同信号转发而来）";
CM_ SG_ 832 Checksum_0x340 "Checksum: IDMSB XOR IDLSB XOR Byte1 XOR Byte2 XOR Byte3 XOR Byte4 XOR Byte5 XOR Byte6XOR Byte7";
CM_ SG_ 832 BCM_Hood_States "前舱盖状态";
CM_ SG_ 832 BCM_System_PowerMode "整车电源状态
vehicle Power Status";
CM_ SG_ 832 BCM_RKE_lock_Unlock_req "智能钥匙遥控解闭锁请求（触发FOB闭锁或解锁按键时发送8帧0x1或0x2之后默认发送0x0）";
CM_ SG_ 832 BCM_HoodSWFault "前舱盖开关故障状态";
CM_ SG_ 832 BCM_FL_DoorSts "左前门状态";
CM_ SG_ 832 BCM_PUSHMotorMal_controlSts "油箱锁电机控制故障(HEV)";
CM_ SG_ 832 BCM_PUSH_Switc_Sts "PUSH 油箱锁微动开关状态(HEV)";
CM_ SG_ 832 RollingCounter_0x340 "RollingCounter: used 4bit length signal and the arithmetic is increased from 0 to 15 by every message.";
CM_ SG_ 64 PEPS_RKECommand "RKE 命令";
CM_ SG_ 64 PEPS_TrunkReleaseReq "PEPS行李箱打开请 求";
CM_ SG_ 64 PEPS_DoorUnlockReq "PEPS解锁请求";
CM_ SG_ 64 PEPS_DoorlockReq "PEPS 系统PE闭锁请求(判断智能钥匙合法）";
CM_ SG_ 735 HU_DirverSLV_Direction_set "驾驶侧座椅前后调节";
CM_ SG_ 735 HU_DirverSHV_Direction_set "驾驶侧座椅高度调节";
CM_ SG_ 735 HU_DirverLNV_Direction_set "驾驶侧靠背前倾后倾调节";
CM_ SG_ 735 HU_PassagerSLV_Direction_set "副驾驶侧座椅前后调节";
CM_ SG_ 735 HU_PassagerSHV_Direction_set "副驾驶侧座椅高度调节";
CM_ SG_ 735 HU_PassagerLNV_Direction_set "副驾驶侧靠背前倾后倾调节";
CM_ SG_ 735 HU_DSM_heatSwitch "主驾座椅加热开关";
CM_ SG_ 735 HU_DSM_Targtemp "驾驶侧座椅目标温度";
CM_ SG_ 735 HU_PSM_heatSwitch "副驾驶座椅加热开关";
CM_ SG_ 735 HU_PSM_Targtemp "副驾驶侧座椅目标温度";
CM_ SG_ 735 HU_DSMEasyEntrySW "座椅迎宾功能开关";
CM_ SG_ 735 HU_RVMAutoFoldSW "外后视镜自动折叠功能开关";
CM_ SG_ 735 HU_RVMFoldButton "外后视镜折叠按钮";
CM_ SG_ 735 HU_RVM_R_DownSW "外后视镜倒车自动向下翻功能开关";
CM_ SG_ 735 HU_Userdefined_Mirror "方向盘自定义按键-后视镜控制";
CM_ SG_ 1506 MCU_SWVersion_Supplier "MCU软件供应商代码（有天际定义，如A/B/C分别代A点/B点/C点供应商）";
CM_ SG_ 1506 MCU_SWVersion_Main "MCU软件版本-大版本";
CM_ SG_ 1506 MCU_SWVersion_Sub1 "MCU软件版本-小版本第一位";
CM_ SG_ 1506 MCU_SWVersion_Sub2 "MCU软件版本-小版本第二位";
CM_ SG_ 1506 MCU_HWVersion_Supplier "MCU硬件供应商代码（有天际定义，如A/B/C分别代表A点/B点/C点供应商）";
CM_ SG_ 1506 MCU_HWVersion_Main "MCU硬件版本-大版本";
CM_ SG_ 1506 MCU_HWVersion_Sub1 "MCU硬件版本-小版本第一位";
CM_ SG_ 1506 MCU_HWVersion_Sub2 "MCU硬件版本-小版本第二位";
CM_ SG_ 802 HU_MCUResetReason "HU MCU Reset Reason";
CM_ SG_ 802 HU_HardACCState "HU Hard ACC State";
CM_ SG_ 802 HU_MCUPowerState "HU MCU Power State";
CM_ SG_ 802 HU_SOCWatchdog "SOC Watch dog";
CM_ SG_ 802 HU_SOCResetType "HU SOC Reset Type";
CM_ SG_ 802 HU_SPIConnectState "SPI Connect State";
CM_ SG_ 802 HU_BatteryVoltage "HU Battery voltage";
CM_ SG_ 802 HU_BCMSystemPowerMode "HU记录的BCM电源模式";
CM_ SG_ 792 TPCV1_Feedback_sts "乘员舱比例阀故障状态(HEV)";
CM_ SG_ 792 TPCV1_Feedback_opening_sts "乘员舱比例阀的开度(HEV)";
CM_ SG_ 793 TPCV2_Feedback_sts "动力系统比例阀故障状(HEV)";
CM_ SG_ 793 TPCV2_Feedback_opening_Sts "态动力系统比例阀的开度(HEV)";
CM_ SG_ 881 VBU_ChargeIncreaseMileageSpeed "充电里程增加速率";
CM_ SG_ 881 VBU_ChargeIncreaseMileage "充电增加里程";
CM_ SG_ 881 VBU_Maintenance_lights "维修灯报警";
CM_ SG_ 881 VBU_SlowChargeGunSt "交流枪状态";
CM_ SG_ 881 VBU_FastChargeGunSt "直流枪状态";
CM_ SG_ 881 VBU_BattTempLowCharge "电池低温充电提醒";
CM_ SG_ 881 VBU_BattEnergyLim "电池能量受限提醒";
CM_ SG_ 881 VBU_FrequentPowerupWaring "频繁上高压提醒,该信号改为预留发默认值0";
CM_ SG_ 881 VBU_NSlipBackWaring "N档溜车提醒";
CM_ SG_ 881 VBU_CDU_Current_power "交流侧实时放电功率";
CM_ SG_ 881 VBU_CDU_MaxCurrent_power "交流侧最大可放电功率";
CM_ SG_ 881 VBU_ExtremeColdMode "VBU反馈极寒模式";
CM_ SG_ 881 VBU_BMS_Current_power "电池当前功率";
CM_ SG_ 154 Checksum_0x9A "Checksum: IDMSB XOR IDLSB XOR Byte1 XOR Byte2 XOR Byte3 XOR Byte4 XOR Byte5 XOR Byte6 XOR Byte7";
CM_ SG_ 154 VBU_ErrorLevel "VBU故障等级";
CM_ SG_ 154 VBU_MCU_Workmode "VBU控制MCU工作模式";
CM_ SG_ 154 VBU_WarmUpCycleMet "暖机循环条件满足(HEV)";
CM_ SG_ 154 VBU_MILReq "VBU request Mil lamp
VBU请求亮故障灯(HEV)";
CM_ SG_ 154 VBU_MCU_TrqReq "VBU控制电机目标扭矩";
CM_ SG_ 154 VBU_MCU_SpdReq "VBU控制电机目标转速";
CM_ SG_ 154 VBU_MotorOffsetCalCmd "电机角度自学习条件准备状态";
CM_ SG_ 154 Rolling_counter_0x9A "RollingCounter: used 4bit length signal and the arithmetic is increased from 0 to 15 by every message.";
CM_ SG_ 155 Checksum_0x9B "Checksum: IDMSB XOR IDLSB XOR Byte1 XOR Byte2 XOR Byte3 XOR Byte4 XOR Byte5 XOR Byte6 XOR Byte7";
CM_ SG_ 155 VBU_DCACOutCurrLim "VBU限制DCAC的最大输出电流";
CM_ SG_ 155 VBU_WPTC_En "WPTC使能";
CM_ SG_ 155 VBU_DCDCLVVoltSet "VBU控制DC输出电压";
CM_ SG_ 155 VBU_WPTC_Request "WPTC开启模式请求";
CM_ SG_ 155 VBU_DCDCWorkmodeReq "VBU控制DC工作模式";
CM_ SG_ 155 VBU_WPTC_BatHotlPwrSet "水PTC目标功率档位";
CM_ SG_ 155 VBU_TBOX_ChrgLockSts "VBU 电子锁状态反馈给TBOX";
CM_ SG_ 155 VBU_ACU_DrvSeatBeltSWSts "VBU请求安全带信号";
CM_ SG_ 155 VBU_OBCWorkmodeReq "VBU控制OBC工作模式";
CM_ SG_ 155 Rolling_counter_0x9B "RollingCounter: used 4bit length signal and the arithmetic is increased from 0 to 15 by every message.";
CM_ SG_ 155 VBU_OBCPwrDwnReq "OBC紧急停机指令";
CM_ SG_ 156 Checksum_0x9C "Checksum: IDMSB XOR IDLSB XOR Byte1 XOR Byte2 XOR Byte3 XOR Byte4 XOR Byte5 XOR Byte6XOR Byte7";
CM_ SG_ 156 VBU_Cruise_Sts "巡航状态";
CM_ SG_ 156 VBU_DriveInhibitAlarm "行车禁止提醒";
CM_ SG_ 156 VBU_HU_ChrgLockSts "VBU 电子锁状态反馈给HU";
CM_ SG_ 156 VBU_CCS_SpeedArm "定速巡航目标车速";
CM_ SG_ 156 VBU_SpeedLimitSWSts "车速限制功能状态";
CM_ SG_ 156 VBU_DMS_Status "驾驶员疲劳状态";
CM_ SG_ 156 VBU_DMS_SWStatus "驾驶员疲劳开关状态";
CM_ SG_ 156 VBU_IdleModeAct "强制怠速模式激活状态(HEV)";
CM_ SG_ 156 VBU_AuthSts "VBU P档锁防盗认证结果";
CM_ SG_ 156 VBU_LimitSpeed "当前限速值设置范围：0~200kmph
设置的间隔：1kmph";
CM_ SG_ 156 VBU_LimitSpeedAlarm_L "限速报警光触发";
CM_ SG_ 156 VBU_LimitSpeedAlarm_V "限速报警声音触发";
CM_ SG_ 156 VBU_TPCV1Control "乘员舱比例阀的开度控制(HEV)";
CM_ SG_ 156 VBU_Cruise_Warning "定速巡航进入提醒";
CM_ SG_ 156 VBU_TPCV2Control "动力系统比例阀的开度控制(HEV)";
CM_ SG_ 156 Rolling_counter_0x9C "RollingCounter: used 4bit length signal and the arithmetic is increased from 0 to 15 by every message.";
CM_ SG_ 156 VBU_ElockSts "VBU电子锁状态";
CM_ SG_ 157 VBU_AC_ComfortEAC_En "舒适性压缩机使能";
CM_ SG_ 157 VBU_AC_BatCoolEAC_En "电池冷却压缩机使能";
CM_ SG_ 157 VBU_AC_APTC_En "空气PTC使能（EV）";
CM_ SG_ 157 VBU_RefuelingInfo "VBU 加油允许状态(HEV)";
CM_ SG_ 157 VBU_HU_Towmode "拖车模式开关";
CM_ SG_ 157 VBU_HU_TowmodeSetEn "拖车模式设置使能";
CM_ SG_ 157 VBU_AC_APTCPwrSet "空气PTC目标功率（EV）";
CM_ SG_ 157 VBU_BCM_TowModewarning "拖车模式报警";
CM_ SG_ 157 VBU_AC_EACPwrSet "压缩机目标功率";
CM_ SG_ 157 VBU_FanPWMSts "冷却风扇PWM占空比";
CM_ SG_ 157 VBU_RemoteACFeedback "远程空调反馈";
CM_ SG_ 157 VBU_ComfortPumpError "乘员舱水泵故障(HEV)";
CM_ SG_ 157 VBU_ENGWVControl "发动机截止阀控制(HEV)";
CM_ SG_ 157 VBU_WPTCWVControl "WPTC截止阀控制(HEV)";
CM_ SG_ 157 VBU_ENGWVFault "发动机截止阀故障(HEV)";
CM_ SG_ 157 VBU_WPTCWVFault "WPTC截止阀故障(HEV)";
CM_ SG_ 157 VBU_FanSts "风扇故障状态";
CM_ SG_ 157 VBU_RefuelingSysErrorRemind "加油系统异常提醒(HEV)";
CM_ SG_ 157 VBU_12VbatterySOHLow "12V Battery SOH Low";
CM_ SG_ 157 VBU_LVSmartChrg_Status "VBU LV Smart Charge Status";
CM_ SG_ 157 VBU_ChargeLight "VBU控制充电指示灯工作模式";
CM_ SG_ 157 VBU_AC_ThermalReqLvl "乘员舱制热档位允许(HEV)";
CM_ SG_ 157 VBU_VehicleModel "车型说明";
CM_ SG_ 256 CheckSum_0x100 "Checksum: IDMSB XOR IDLSB XOR Byte1 XOR Byte2 XOR Byte3 XOR Byte4 XOR Byte5 XOR Byte6 XOR Byte7";
CM_ SG_ 256 VBU_BMS_PackU "电池电压";
CM_ SG_ 256 VBU_BMS_WaringLevel "电池报警等级";
CM_ SG_ 256 VBU_BMS_PackI "电池电流";
CM_ SG_ 256 VBU_BMS_RelayChrPos "快充正接触器状态";
CM_ SG_ 256 VBU_BMS_RelayNeg "总负接触器状态";
CM_ SG_ 256 VBU_BMS_RelayPre "预充电接触器状态";
CM_ SG_ 256 VBU_BMS_RelayPos "总正接触器状态";
CM_ SG_ 256 VBU_BMS_RelayChrNeg "快充负接触器状态";
CM_ SG_ 256 VBU_BMS_State "VBU工作状态";
CM_ SG_ 256 VBU_BMS_ChrFastState "直流充电状态";
CM_ SG_ 256 VBU_BMS_SPreCharging "预充电状态";
CM_ SG_ 256 VBU_BMS_ChrSlowState "交流充电状态";
CM_ SG_ 256 VBU_BMS_0x100_RollingCounter "从0到15循环计数，如果通信中断，则重新从0开始计数。";
CM_ SG_ 258 VBU_BMS_RealSOC "电池实际SOC
允许跳变";
CM_ SG_ 258 VBU_BMS_PackDispSoc "仪表显示SOC";
CM_ SG_ 258 VBU_BMS_ChrNegRelayEnable "快充负继电器驱动信号";
CM_ SG_ 258 VBU_BMS_ChrPosRelayEnable "快充正继电器驱动信号";
CM_ SG_ 258 VBU_BMS_PreRelayEnable "预充继电器驱动信号";
CM_ SG_ 258 VBU_BMS_CellSumVol "单体累加电压";
CM_ SG_ 258 VBU_BMS_MainNegRelayEnable "主负继电器驱动信号";
CM_ SG_ 258 VBU_BMS_MainPosRelayEnable "主正继电器驱动信号";
CM_ SG_ 258 VBU_BMS_LinkU "电池预充电电压";
CM_ SG_ 258 VBU_BMS_BalanceSts "电池均衡状态";
CM_ SG_ 258 VBU_BMS_0x102_RollingCounter "从0到15循环计数，如果通信中断，则重新从0开始计数。";
CM_ SG_ 258 VBU_APU_State "VBU_APU工作状态";
CM_ SG_ 261 CheckSum_0x105 "Checksum: IDMSB XOR IDLSB XOR Byte1 XOR Byte2 XOR Byte3 XOR Byte4 XOR Byte5 XOR Byte6 XOR Byte7";
CM_ SG_ 261 VBU_BMS_ChrRequestU "充电电压请求";
CM_ SG_ 261 VBU_BMS_ChrRequest "充电请求";
CM_ SG_ 261 VBU_BMS_ChrRequestI "充电电流请求";
CM_ SG_ 261 VBU_BMS_Insulation_positive "绝缘电阻正极对地";
CM_ SG_ 261 VBU_BMS_Insulation_negative "绝缘电阻负极对地";
CM_ SG_ 261 RollingCounter_0x105 "从0到15循环计数，如果通信中断，则重新从0开始计数。";
CM_ SG_ 274 VBU_BMS_MaxCellNo "电池最高单体电压编号";
CM_ SG_ 274 VBU_BMS_MaxCellU "电池最高单体电压";
CM_ SG_ 274 VBU_BMS_MinCellNo "电池最低单体电压编号";
CM_ SG_ 274 VBU_BMS_MinCellU "电池最低单体电压";
CM_ SG_ 274 VBU_BMS_CellVolDev "电池单体压差";
CM_ SG_ 274 VBU_BMS_0x112_RollingCounter "从0到15循环计数，如果通信中断，则重新从0开始计数。";
CM_ SG_ 277 VBU_BMS_MaxDschPowerPeak "电池最大峰值放电功率";
CM_ SG_ 277 VBU_BMS_DschAllowedPower "电池允许放电功率";
CM_ SG_ 277 VBU_BMS_MaxChrgPowerPeak "电池最大峰值充电功率";
CM_ SG_ 277 VBU_BMS_ChrgAllowedPower "电池允许充电功率";
CM_ SG_ 277 VBU_BMS_0x115_RollingCounter "从0到15循环计数，如果通信中断，则重新从0开始计数。";
CM_ SG_ 278 VBU_Mileage_HEV "续航里程_增程(HEV)";
CM_ SG_ 278 VBU_Mileage_EV "续航里程_纯电（HEV)";
CM_ SG_ 278 VBU_Energyflow "能量流显示";
CM_ SG_ 278 VBU_UIDisplay "显示界面控制";
CM_ SG_ 278 VBU_ChargStstotbox "充电状态（TBOX专用）";
CM_ SG_ 278 VBU_Dischargehighwarning "放电过载提醒";
CM_ SG_ 278 VBU_HU_ChargeCtrl_Setsts "VBU反馈大屏立即\停止充电状态";
CM_ SG_ 278 VBU_TBOX_ChargeCtrl_Setsts "VBU反馈APP立即\停止充电状态";
CM_ SG_ 278 VBU_TBOX_SOCExtremelylow "SOC极低提醒";
CM_ SG_ 278 VBU_TimeChargelight "预约充电指示灯";
CM_ SG_ 278 VBU_HU_V2XFeedbackAlarm "VBU反馈大屏交流放电状态";
CM_ SG_ 278 VBU_APUDrivingState "增程行驶标志位(HEV)";
CM_ SG_ 278 VBU_AcSysFultSts "交流充电系统故障";
CM_ SG_ 278 VBU_BMS_DCSysFultSts "直流充电系统故障";
CM_ SG_ 278 VBU_GearAntiTheftWarning "P档锁认证无效提醒";
CM_ SG_ 276 VBU_BMS_PACK_PressureValue "电池PACK压力值";
CM_ SG_ 276 VBU_ChargeButtonEN "充电按键使能";
CM_ SG_ 276 VBU_ChargeButton "充电按键命令";
CM_ SG_ 276 VBU_V2XWorkOrderEN "供电开关使能";
CM_ SG_ 276 VBU_V2XWorkOrder "供电开关命令";
CM_ SG_ 276 VBU_DischargeDepthFeedBack "VBU放电深度设置反馈";
CM_ SG_ 276 VBU_DischargetimeWaring "剩余放电时间提醒";
CM_ SG_ 276 VBU_BMS_InputWaterTemp "电池进水口温度";
CM_ SG_ 276 VBU_BMS_OutputWaterTemp "电池出水口温度";
CM_ SG_ 276 VBU_BMS_0x114_RollingCounter "从0到15循环计数，如果通信中断，则重新从0开始计数。";
CM_ SG_ 279 VBU_ActualPowerPer "实际功率百分比";
CM_ SG_ 279 VBU_thermalControlReq " 电池热管理控制请求";
CM_ SG_ 279 VBU_PowerSwitchON_HEV "VBU发送上ON提醒(HEV)
当 VBU 满足条件时，VBU 给 HU 发送 VBU_PowerSwitchON（HEV）=0x1:active，连续
发送 5 帧后发送 0x0：inactive";
CM_ SG_ 279 VBU_StartEngineReminder_HEV "VBU发动启动发动机提醒(HEV)
当 VBU 满足条件时，VBU 给 HU 发送 VBU_StartEngineReminder（HEV）=0x1:active，
连续发送 5 帧后发送 0x0：inactive；";
CM_ SG_ 279 VBU_ExitDschReminder_HEV "即将结束放电提醒_HEV";
CM_ SG_ 279 VBU_RestMode_Sts "VBU休息模式状态";
CM_ SG_ 279 VBU_EnergyRegLimPer "回馈功率限制百分比";
CM_ SG_ 279 VBU_SOCLow_ENGStart "SOC低发动机自启动时刻对应SOC值（HEV）";
CM_ SG_ 279 VBU_ExchangerInputWaterTemp "电池换热器入水口温度 (HEV)";
CM_ SG_ 279 VBU_BattThermalReqLvl "电池包热管理需求等级，暂时定义为15个等级";
CM_ SG_ 279 VBU_RecoTiming "恢复充电倒计时";
CM_ SG_ 279 VBU_ExitDschReminder_EV "即将结束放电提醒_EV";
CM_ SG_ 279 VBU_SOCLowDisACRemind "低SOC关闭舒适性空调提醒（HEV）";
CM_ SG_ 279 VBU_EnergyDriveLimPer "驱动功率受限百分比";
CM_ SG_ 1441 ICM_DST_EV "本次里程-纯电部分";
CM_ SG_ 1441 ICM_SigPowerConsumption "本次百公里能耗-纯电部分";
CM_ SG_ 1441 ICM_SigMileagetime_EV "本次里程时间-纯电部分";
CM_ SG_ 1441 ICM_ODOTotal_EV "ODO 总里程 -纯电部分";
CM_ SG_ 1442 ICM_DST_EREV "本次里程-增程部分";
CM_ SG_ 1442 ICM_Sigfueleconomy "本次百公里油耗-增程部分";
CM_ SG_ 1442 ICM_SigMileagetime_EREV "本次里程时间-增程部分";
CM_ SG_ 1442 ICM_ODOTotal_EREV "ODO 总里程 -增程部分";
CM_ SG_ 1443 ICM_trip_EV "小计里程-纯电部分";
CM_ SG_ 1443 ICM_trip_EREV "小计里程-增程部分";
CM_ SG_ 1443 ICM_tripPowerConsumption "小计百公里能耗-纯电部分";
CM_ SG_ 1443 ICM_tripfueleconomy "小计百公里油耗-增程部分";
CM_ SG_ 1444 ICM_TotalAverfueleconomy "累计平均油耗";
CM_ SG_ 1444 ICM_TotalAverEnergy "累计平均电耗";
CM_ SG_ 1444 ICM_TotalTime_ALL "行驶总时间";
CM_ SG_ 1445 ICM_triptime_EV "小计里程时间-纯电部分";
CM_ SG_ 1445 ICM_triptime_EREV "小计里程时间-增程部分";
CM_ SG_ 1445 ICM_TotalTime_EREV "增程运行总时间";
CM_ SG_ 1445 ICM_TotalTime_EV "纯电运行总时间";
CM_ SG_ 320 Checksum_0x140 "Checksum: IDMSB XOR IDLSB XOR Byte1 XOR Byte2 XOR Byte3 XOR Byte4 XOR Byte5 XOR Byte6 XOR Byte7";
CM_ SG_ 320 VBU_CurrentMotorTorq "当前电机扭矩";
CM_ SG_ 320 VBU_MaxMotorTorque "电机最大电动扭矩";
CM_ SG_ 320 VBU_MiNMotorTorque "电机最小电动扭矩";
CM_ SG_ 320 Rollingcounter_0x140 "从0到15循环计数，如果通信中断，则重新从0开始计数。";
CM_ SG_ 321 Checksum_0x141 "Checksum: IDMSB XOR IDLSB XOR Byte1 XOR Byte2 XOR Byte3 XOR Byte4 XOR Byte5 XOR Byte6 XOR Byte7";
CM_ SG_ 321 VBU_DriverDemandTorq "Motor torque requested by driver or cruise control, reduced by motor drag torque and torque consumption of auxiliary devices";
CM_ SG_ 321 VBU_OnepedalSetEn "单踏板模式设置使能";
CM_ SG_ 321 VBU_QECACC "VBU响应VLC扭矩控制的状态";
CM_ SG_ 321 VBU_EnergyMode "能量管理模式";
CM_ SG_ 321 VBU_GearShiftInProgress "Gear shifting Progress";
CM_ SG_ 321 VBU_ShiftInProgress_Status "Gear shift in progress status";
CM_ SG_ 321 VBU_AcceleratioNModePer "加速模式百分比，范围：0-100percent
精度：1percent";
CM_ SG_ 321 VBU_OverRide "Indicating the torque demanded by the driver is higher than the torque demanded by ACC.
指示驾驶员要求的扭矩高于ACC所要求的扭矩";
CM_ SG_ 321 VBU_DriveMode "整车驾驶模式";
CM_ SG_ 321 VBU_APS_LC_Availability "VBU_APS_LC_Availability（预留信号，实际采用PrCAN的该信号控制）";
CM_ SG_ 321 VBU_APS_LC_FailureSts "VBU_APS_LC_FailureSts（预留信号，实际采用PrCAN的该信号控制）";
CM_ SG_ 321 VBU_E_Pedalwarn "单踏板设置提示";
CM_ SG_ 321 VBU_KeepSOC "保持电量百分比，范围：0-100percent
精度：1percent";
CM_ SG_ 321 VBU_APS_LC_Status "VBU_APS_LC_Status（预留信号，实际采用PrCAN的该信号控制）";
CM_ SG_ 321 Rollingcounter_0x141 "从0到15循环计数，如果通信中断，则重新从0开始计数。";
CM_ SG_ 322 Checksum_0x142 "Checksum: IDMSB XOR IDLSB XOR Byte1 XOR Byte2 XOR Byte3 XOR Byte4 XOR Byte5 XOR Byte6 XOR Byte7";
CM_ SG_ 322 VBU_vacuumpumpsensorRelvalue "真空泵压力传感器相对压力值";
CM_ SG_ 322 VBU_MCU_MotorSpeed "电机实时输出转速";
CM_ SG_ 322 VBU_EPB_FunctionSet "VBU请求EPB控制";
CM_ SG_ 322 Rollingcounter_0x142 "从0到15循环计数，如果通信中断，则重新从0开始计数。";
CM_ SG_ 336 Checksum_0x150 "Checksum: IDMSB XOR IDLSB XOR Byte1 XOR Byte2 XOR Byte3 XOR Byte4 XOR Byte5 XOR Byte6 XOR Byte7";
CM_ SG_ 336 VBU_GearLeverPos "实际档位";
CM_ SG_ 336 VBU_TortoiseLamp "龟灯信号";
CM_ SG_ 336 VBU_Elockfail "电子锁失败提醒";
CM_ SG_ 336 VBU_12VbatteryError "12V蓄电池故障";
CM_ SG_ 336 VBU_ReadySts "Ready信号";
CM_ SG_ 336 VBU_MotorPumpError "电机水泵故障";
CM_ SG_ 336 VBU_VacuumSysFaultLamp "真空系统故障灯";
CM_ SG_ 336 VBU_GearP_EnterWarning "P档无法进入提醒";
CM_ SG_ 336 VBU_VehicleSysFaultLamp "整车系统故障";
CM_ SG_ 336 VBU_BattPumpError "电池水泵故障";
CM_ SG_ 336 VBU_DriveableAlarm "可行驶状态报警信号";
CM_ SG_ 336 VBU_GearFlashReq "换挡提示";
CM_ SG_ 336 VBU_ShowCarMod "展车模式";
CM_ SG_ 336 VBU_EnergyRecoveryPer "能量回收强度百分比";
CM_ SG_ 336 VBU_Mileage "续航里程";
CM_ SG_ 336 VBU_BMS_ISOWaringLamp "ERR绝缘故障灯";
CM_ SG_ 336 VBU_BMS_BatteryErrorLamp "动力电池系统故障灯";
CM_ SG_ 336 VBU_ChargeDepthwarn "充电深度设置提示";
CM_ SG_ 336 VBU_ChargeDepthSts "充电深度设置状态";
CM_ SG_ 336 VBU_CloolantHighAlarm "冷却液温度过高报警";
CM_ SG_ 336 VBU_MotorLoopCoolantLow "电机回路冷却液过低报警";
CM_ SG_ 336 VBU_BatLoopCoolantLow "电池回路冷却液过低报警";
CM_ SG_ 336 VBU_PassengerCoolantLow "乘员舱回路冷却液过低报警（HEV）";
CM_ SG_ 336 VBU_BMS_SOClowLamp "低SOC提示";
CM_ SG_ 336 VBU_BMS_MaintenanceLamp "电池系统保养灯";
CM_ SG_ 336 VBU_BAT_thermalControlSts "电池热管理状态";
CM_ SG_ 336 VBU_BMS_ThermRunAway "电池热失控故障";
CM_ SG_ 336 VBU_ESCLConfig "ESCL配置状态";
CM_ SG_ 336 Rollingcounter_0x150 "从0到15循环计数，如果通信中断，则重新从0开始计数。";
CM_ SG_ 337 Checksum_0x151 "Checksum: IDMSB XOR IDLSB XOR Byte1 XOR Byte2 XOR Byte3 XOR Byte4 XOR Byte5 XOR Byte6XOR Byte7";
CM_ SG_ 337 VBU_HVLock_ALL "VBU高压互锁信号(综合）";
CM_ SG_ 337 VBU_BrakeLampReq "点亮制动灯请求";
CM_ SG_ 337 VBU_Intelligent_Charge_Sts "智能充电状态";
CM_ SG_ 337 VBU_HVLock1 "VBU高压互锁1信号";
CM_ SG_ 337 VBU_UnlockFuelLid "油箱锁解锁请求(HEV)";
CM_ SG_ 337 VBU_BrkSw_Sts "制动踏板开关状态
Brake pedal switch Status";
CM_ SG_ 337 VBU_AccelPedalMalSts "油门踏板故障状态";
CM_ SG_ 337 VBU_BrkPed_Pos "制动踏板位置度信号";
CM_ SG_ 337 VBU_AccSW_Sts "油门踏板开关状态";
CM_ SG_ 337 VBU_AtmosphePressValue "大气压力值";
CM_ SG_ 337 VBU_AccPedPos "油门踏板位置度
Accelerator pedal position";
CM_ SG_ 337 VBU_TargetGear "VBUtarget gear";
CM_ SG_ 337 VBU_APS_WorkStatus "VBU反馈给AVM的工作状态（信号预留）";
CM_ SG_ 337 Rolling_counter_0x151 "RollingCounter: used 4bit length signal and the arithmetic is increased from 0 to 15 by every message.";
CM_ SG_ 337 VBU_HVLock2 "VBU高压互锁2信号";
CM_ SG_ 337 VBU_HVLock3 "VBU高压互锁3信号";
CM_ SG_ 734 HU_SubMileage_Reset "小计里程重置";
CM_ SG_ 734 HU_EPB_FunctionSet "EPB手动释放";
CM_ SG_ 734 HU_VBU_Towmode "拖车模式";
CM_ SG_ 734 HU_ShowCarMode_Req "展车模式请求";
CM_ SG_ 734 HU_EnergyRecoveryPer "能量回收强度百分比";
CM_ SG_ 734 HU_SpeedLimitSW "车速限制开关，默认关";
CM_ SG_ 734 HU_LimitSpeedSet "开启功能时：
设置范围：0~200KM/H
设置的间隔：1km/h";
CM_ SG_ 734 HU_EnergyMode "能量管理模式";
CM_ SG_ 734 HU_RestSwitch_Set "HU休息模式开关";
CM_ SG_ 734 HU_DriveMode "驾驶模式";
CM_ SG_ 734 HU_AccelerationModePer "加速模式百分比,范围：0-100%
精度：1%
";
CM_ SG_ 734 HU_KeepSOC "保持电量百分比，范围：0-100%
精度：1%";
CM_ SG_ 734 HU_DMS_SW "疲劳驾驶提醒开关";
CM_ SG_ 1451 VBU_BMS_FastChargeInfoU "快充输出电压";
CM_ SG_ 1451 VBU_BMS_FastChargeSOE "本次快充输出能量";
CM_ SG_ 1451 VBU_BMS_FastChargeInfoI "快充输出电流";
CM_ SG_ 1451 VBU_Dischargetime "预计可放电时间";
CM_ SG_ 1451 VBU_Discharge_energy "VBU已放电量";
CM_ SG_ 1452 VBU_ChrFast_Current_power "直流侧实时放电功率";
CM_ SG_ 1452 VBU_ChrFast_MaxCurrent_power "直流侧最大可放电功率";
CM_ SG_ 1450 BST_ReachSOCsetting "达到SOC设定值停止充电";
CM_ SG_ 1450 BST_ReachBattVolset "达到总压设定值停止充电";
CM_ SG_ 1450 BST_ReachCellVolset "达到单体电压设定值停止充电";
CM_ SG_ 1450 BST_ISOFault "绝缘故障停止充电";
CM_ SG_ 1450 BST_VBU_BMS_PCBOverTemp "BMS元器件过温停止充电";
CM_ SG_ 1450 BST_ChargeOverCurr "充电电流过大停止充电";
CM_ SG_ 1450 BST_FastChaVolUnusual "充电桩输出电压异常停止";
CM_ SG_ 1450 BST_FastChargerSTOP "充电桩主动停止";
CM_ SG_ 1450 CST_ReachChargerSet "达到充电桩设定条件停止";
CM_ SG_ 1450 CST_ManualStop "人工停止";
CM_ SG_ 1450 CST_FaultStop "故障停止";
CM_ SG_ 1450 CST_BMSStop "BMS主动停止";
CM_ SG_ 1450 CST_FastCharOverTemp "充电桩过温";
CM_ SG_ 1450 CST_CharContorFault "充电连接器故障";
CM_ SG_ 1450 CST_FastChaInOvTemp "充电桩内部过温故障";
CM_ SG_ 1450 CST_EngNotTransfer "电量不能传送";
CM_ SG_ 1450 CST_FastChaUrgentStop "充电桩急停故障";
CM_ SG_ 1450 CST_OtherFault "其他故障停止";
CM_ SG_ 1450 CST_CurrentMismatch "电流不匹配停止";
CM_ SG_ 1450 CST_VoltageUnusual "电压异常停止";
CM_ SG_ 1450 BEM_CRM_00_OverTim "接收CRM=0X00报文超时";
CM_ SG_ 1450 BEM_CRM_AA_OverTim "接收CRM=0XAA报文超时";
CM_ SG_ 1450 BEM_CTSCML_OverTim "接收CTS和CML报文超时";
CM_ SG_ 1450 BEM_CRO_OverTim "接收CRO报文超时";
CM_ SG_ 1450 BEM_CCS_OverTim "接收CCS报文超时";
CM_ SG_ 1450 BEM_CST_OverTim "接收CST报文超时";
CM_ SG_ 1450 BEM_CSD_OverTim "接收CST报文超时";
CM_ SG_ 1450 CEM_BRM_OverTim "接收BRM报文超时";
CM_ SG_ 1450 CEM_BCP_OverTim "接收BRM报文超时";
CM_ SG_ 1450 CEM_BRO_OverTim "接收BRO报文超时";
CM_ SG_ 1450 CEM_BCS_OverTim "接收BCS报文超时";
CM_ SG_ 1450 CEM_BCL_OverTim "接收BCL报文超时";
CM_ SG_ 1450 CEM_BST_OverTim "接收BST报文超时";
CM_ SG_ 1450 CEM_BSD_OverTim "接收BSD报文超时";
CM_ SG_ 1450 VBU_BMS_ChargeSOPbuffer "BMS充电功率bufffer，BMS  水池法计算充电功率系数";
CM_ SG_ 314 VBU_Reserved_ID1 "VBU预留ID1";
CM_ SG_ 315 TBOX_Reserved_ID1 "TBOX预留ID1";
CM_ SG_ 1324 VBU_accelerator1 "油门信号电压1";
CM_ SG_ 1324 VBU_accelerator2 "油门信号电压2";
CM_ SG_ 1324 VBU_brakesensor1 "制动角度传感器电压1";
CM_ SG_ 1324 VBU_brakesensor2 "制动角度传感器电压2";
CM_ SG_ 1324 VBU_vacuumpumpsensor "真空泵压力传感器电压";
CM_ SG_ 1324 VBU_KL87inputVol "KL87输入电压";
CM_ SG_ 1324 VBU_CrashStatus "碰撞状态";
CM_ SG_ 1324 VBU_AtmosphePressure "大气压力传感器电压";
CM_ SG_ 1324 VBU_FanPWMFeedback "冷却风扇PWM反馈占空比";
CM_ SG_ 977 Checksum_0x3D1 "Checksum: IDMSB XOR IDLSB XOR Byte1 XOR Byte2 XOR Byte3 XOR Byte4 XOR Byte5 XOR Byte6XOR Byte7";
CM_ SG_ 977 CDU_TempWater "CDU water temperature
（CDU入水口水温）.";
CM_ SG_ 977 CDU_PFC_TempAct "actual temperature of CDU_PFC
（CDU内部PFC模块温度）";
CM_ SG_ 977 CDU_DC_TempAct "actual temperature of CDU_DC
（DC内部实际温度）";
CM_ SG_ 977 CDU_Inside_Air_TempAct "actual temperature of CDU_Inside
（CDU内部环境温度）";
CM_ SG_ 977 CDU_WakeupSrc "CDU wakeup source
（CDU唤醒源）.";
CM_ SG_ 977 CDU_AC_FreqSts "交流侧频率状态";
CM_ SG_ 977 CDU_OBC_PlugCon_ErrSts "充电枪异常";
CM_ SG_ 977 CDU_OBC_EVSE_ErrSts "充电桩异常";
CM_ SG_ 977 CDU_LLC_TempAct "actual temperature of CDU_LLC
（CDU内部LLC模块温度）";
CM_ SG_ 977 Rolling_counter_0x3D1 "RollingCounter: used 4bit length signal and the arithmetic is increased from 0 to 15 by every message.";
CM_ SG_ 978 Checksum_0x3D2 "Checksum: IDMSB XOR IDLSB XOR Byte1 XOR Byte2 XOR Byte3 XOR Byte4 XOR Byte5 XOR Byte6XOR Byte7";
CM_ SG_ 978 CDU_OBC_ChrgEffciency "OBC real-time efficiency
（OBC真实效率）";
CM_ SG_ 978 CDU_OBC_DeratingSts "OBC derating status
（OBC降额状态）";
CM_ SG_ 978 CDU_OBC_CCCap "OBC CC capacity
（OBC CC判断载流能力）.";
CM_ SG_ 978 CDU_OBC_ACHVILSts "OBC AC HVIL state
（OBC交流输入侧高压互锁状态）.";
CM_ SG_ 978 CDU_OBC_ACVolt "OBC AC voltage
（OBC交流侧电压）.";
CM_ SG_ 978 CDU_OBC_ACCUrr "OBC AC current
（OBC交流侧电流）.";
CM_ SG_ 978 CDU_OBC_S2Sts "S2 swtich state
（S2开关状态）.";
CM_ SG_ 978 CDU_OBC_CCResVal "CC resistance value
（CC实际电阻数值）.";
CM_ SG_ 978 CDU_OBC_DischCPSts "OBC Discharge CP state
（OBC 逆变时CP有效状态）.";
CM_ SG_ 978 Rolling_counter_0x3D2 "RollingCounter: used 4bit length signal and the arithmetic is increased from 0 to 15 by every message.";
CM_ SG_ 979 Checksum_0x3D3 "Checksum: IDMSB XOR IDLSB XOR Byte1 XOR Byte2 XOR Byte3 XOR Byte4 XOR Byte5 XOR Byte6XOR Byte7";
CM_ SG_ 979 CDU_OBC_HVVolt "OBC HV voltage
（OBC输出电压）";
CM_ SG_ 979 CDU_OBC_MaxChrgOutpVolt "OBC maximum charging voltage
（OBC最大充电电压）";
CM_ SG_ 979 CDU_OBC_MaxChrgOutpCur "OBC maximum charging current
（OBC最大充电电流）";
CM_ SG_ 979 CDU_OBC_HVCurr "OBC HV current.
(+：Charge mode output current from CDU to HVBAT,
-：Discharge mode input current from HVBAT)
（OBC输出电流）";
CM_ SG_ 592 Checksum_0x250 "Checksum: IDMSB XOR IDLSB XOR Byte1 XOR Byte2 XOR Byte3 XOR Byte4 XOR Byte5 XOR Byte6XOR Byte7";
CM_ SG_ 592 CDU_OBC_ChrgFailLevel "OBC fault class
（OBC故障等级）";
CM_ SG_ 592 CDU_OBC_WorkMode "OBC work mode.
(Disconnect:Vhv<60V;Connect:Vhv>=60V)
（OBC 工作模式）";
CM_ SG_ 592 CDU_OBC_CPFreqSts "CP frequency state.
(Invalid:Fcp<900 | Fcp>1100
Valid:Fcp>=900 & Fcp<=1100)
（CP频率状态）";
CM_ SG_ 592 CDU_OBC_ChgCPSts "OBC charge CP state
（OBC 充电时CP有效状态）.";
CM_ SG_ 592 CDU_OBC_CPPkVolt "CP peak voltage
（CP电压值）.";
CM_ SG_ 592 CDU_OBC_HVPwrMax "The maximum HV power OBC can output at present
（OBC当前最大输出功率）.";
CM_ SG_ 592 CDU_OBC_CpDutyVal "CP duty value
（CP占空比值）.";
CM_ SG_ 592 CDU_OBC_CCSts "OBC CC state(Charge/V2V/V2L)
（OBC CC连接状态）.";
CM_ SG_ 592 CDU_KL30Volt "CDU KL30 voltage
（CDU检测KL30电压值）.";
CM_ SG_ 592 CDU_OBC_MILReq "OBC request Mil lamp
（OBC请求亮故障灯）";
CM_ SG_ 592 Rolling_counter_0x250 "RollingCounter: used 4bit length signal and the arithmetic is increased from 0 to 15 by every message.";
CM_ SG_ 392 Checksum_0x188 "Checksum: IDMSB XOR IDLSB XOR Byte1 XOR Byte2 XOR Byte3 XOR Byte4 XOR Byte5 XOR Byte6XOR Byte7";
CM_ SG_ 392 CDU_DC_ErrorLevel "DC fault class
（DCDC故障等级）";
CM_ SG_ 392 CDU_DC_WorkMode "DCDC work mode.
(Disconnect:Vhv<60V,
Connect:Vhv>=60V)
（DC工作模式）";
CM_ SG_ 392 CDU_DC_HVHVILSts "DCDC HV HVIL state
（DC高压侧互锁状态）.";
CM_ SG_ 392 CDU_DC_HVVolt "DCDC HV voltage
（DC输入电压）.";
CM_ SG_ 392 CDU_DC_DeratingSts "DCDC derating status
（DCDC降额状态）";
CM_ SG_ 392 CDU_DC_Tbox_WorkSts "DCDC状态报警";
CM_ SG_ 392 CDU_DC_Tbox_TempFault "DCDC温度报警";
CM_ SG_ 392 CDU_DC_LVVolt "DCDC LV voltage
（DC输出电压）.";
CM_ SG_ 392 CDU_DC_HVCurr "DCDC HV current
（DC输入电流）.";
CM_ SG_ 392 CDU_DC_LVCurr "DCDC LV current
（DC输出电流）.";
CM_ SG_ 392 Rolling_counter_0x188 "RollingCounter: used 4bit length signal and the arithmetic is increased from 0 to 15 by every message.";
CM_ SG_ 1552 CDU_OBC_ACHVIL_Fault "AC侧互锁异常";
CM_ SG_ 1552 CDU_OBC_Input_Overvolt_SW "AC输入软件过压保护";
CM_ SG_ 1552 CDU_OBC_Input_Undervolt_SW "AC输入软件欠压保护";
CM_ SG_ 1552 CDU_OBC_HW_InputCurHig_lv2 "AC输入过流硬件2级保护";
CM_ SG_ 1552 CDU_OBC_HW_InputCurHig_lv3 "AC输入过流硬件3级保护";
CM_ SG_ 1552 CDU_OBC_AC_AbnormFreq "充电时AC侧频率异常";
CM_ SG_ 1552 CDU_OBC_Output_Overvolt "OBC充电输出软件过压";
CM_ SG_ 1552 CDU_OBC_Output_Undervolt_HW "OBC充电高压输出欠压";
CM_ SG_ 1552 CDU_OBC_HW_OutputCurHig_lv2 "OBC充电高压输出硬件过流2级保护";
CM_ SG_ 1552 CDU_OBC_HW_OutputCurHig_lv3 "OBC充电高压输出硬件过流3级保护";
CM_ SG_ 1552 CDU_OBC_SW_OutputCurHig_lv2 "OBC充电高压输出软件过流2级保护";
CM_ SG_ 1552 CDU_OBC_SW_OutputCurHig_lv3 "OBC充电高压输出软件过流3级保护";
CM_ SG_ 1552 CDU_OBC_OverTemp "OBC过温";
CM_ SG_ 1552 CDU_OBC_Input_Underpower "OBC交流输入低压降功率";
CM_ SG_ 1552 CDU_OBC_Input_Overpower "OBC输出过压降功率";
CM_ SG_ 1552 CDU_OBC_Output_Underpower "OBC输出电压欠压降功率";
CM_ SG_ 1552 CDU_OBC_HigTemp "OBC过温降功率";
CM_ SG_ 1552 CDU_OBC_Start_Failure "OBC启动失败故障";
CM_ SG_ 1552 CDU_OBC_Prechrg_Fault "预充失败";
CM_ SG_ 1552 CDU_OBC_OutputShortCirc "充电时输出短路";
CM_ SG_ 1552 CDU_OBC_PFC_Start_Failure "充电功率因数校正（PFC）启动失败";
CM_ SG_ 1552 CDU_OBC_PFC_Busvolt_Hig "功率因数校正（PFC）母线过压";
CM_ SG_ 1552 CDU_OBC_PFC_Busvolt_Low_lv2 "功率因数校正（PFC）母线2级欠压";
CM_ SG_ 1552 CDU_OBC_PFC_Busvolt_Low_lv3 "功率因数校正（PFC）母线3级欠压";
CM_ SG_ 1552 CDU_OBC_Dischr_ACvolt_Hig "放电AC软件过压保护";
CM_ SG_ 1552 CDU_OBC_Dischr_ACvolt_Low "放电AC软件欠压保护";
CM_ SG_ 1552 CDU_OBC_SW_Dischr_ACCur_Hig "放电AC软件过流保护";
CM_ SG_ 1552 CDU_OBC_HW_Dischr_ACCur_Hig "放电AC硬件过流保护";
CM_ SG_ 1552 CDU_OBC_Dischr_AC_AbnormFreq "放电时AC侧频率异常";
CM_ SG_ 1552 CDU_OBC_SW_Dischr_Overvolt "OBC放电高压软件过压";
CM_ SG_ 1552 CDU_OBC_Dischr_AC_Overvolt "OBC放电高压输入欠压";
CM_ SG_ 1552 CDU_OBC_HW_Dischr_CurHig "OBC放电高压输入硬件过流保护";
CM_ SG_ 1552 CDU_OBC_SW_Dischr_CurHig "OBC放电高压输入软件过流保护";
CM_ SG_ 1552 CDU_OBC_Dischr_ShotCirc "逆变输出短路";
CM_ SG_ 1552 Abnormal_Insulation_Resistance "绝缘耐压异常";
CM_ SG_ 1552 CDU_OBC_DTC "OBC diagnostic error code
（OBC诊断故障码）.";
CM_ SG_ 1553 CDU_DCDC_OutputVolHig_lv2 "DCDC低压输出软件过压2级保护";
CM_ SG_ 1553 CDU_DCDC_OutputVolHig_lv3 "DCDC低压输出软件过压3级保护";
CM_ SG_ 1553 CDU_DCDC_OutputVolLow_lv2 "DCDC低压输出软件欠压2级保护";
CM_ SG_ 1553 CDU_DCDC_OutputVolLow_lv3 "DCDC低压输出软件欠压3级保护";
CM_ SG_ 1553 CDU_DCDC_OutputOpen "DCDC低压输出断路告警保护";
CM_ SG_ 1553 CDU_DCDC_HW_OutputCurHig_lv2 "DCDC低压输出硬件过流2级保护";
CM_ SG_ 1553 CDU_DCDC_HW_OutputCurHig_lv3 "DCDC低压输出硬件过流3级保护";
CM_ SG_ 1553 CDU_DCDC_SW_OutputCurHig_lv2 "DCDC低压输出软件过流2级保护";
CM_ SG_ 1553 CDU_DCDC_SW_OutputCurHig_lv3 "DCDC低压输出软件过流3级保护";
CM_ SG_ 1553 CDU_DCDC_OutputShotCirc_lv2 "DCDC低压输出短路2级保护";
CM_ SG_ 1553 CDU_DCDC_OutputShotCirc_lv3 "DCDC低压输出短路3级保护";
CM_ SG_ 1553 KL30_Input_Overvolt "KL30输入过压";
CM_ SG_ 1553 KL30_Input_Undervolt "KL30输入欠压";
CM_ SG_ 1553 CDU_DCDC_TempSensorFault "温度传感器电路故障";
CM_ SG_ 1553 CDU_DCDC_InputVolHig "DCDC输入过压降功率";
CM_ SG_ 1553 CDU_DCDC_InputVolLow "DCDC输入欠压降功率";
CM_ SG_ 1553 CDU_DCDC_start_Failure "DCDC启动失败";
CM_ SG_ 1553 CDU_DCDC_SW_InputVolHig "DCDC的高压直流输入软件过压";
CM_ SG_ 1553 CDU_DCDC_SW_InputVolLow "DCDC的高压直流输入软件欠压";
CM_ SG_ 1553 CDU_DCDC_OverTemp "DCDC过温";
CM_ SG_ 1553 CDU_DC_SCI_Com_Failure "内部SCI通讯故障";
CM_ SG_ 1553 CDU_DCDC_MCUChecksum_Failure "功率侧MCU未收到校准系数";
CM_ SG_ 1553 CDU_DCDC_InnerTempHig "DCDC内部温度过温";
CM_ SG_ 1553 CDU_DCDC_Shutdown_For_LowTemp "低温关机保护";
CM_ SG_ 1553 CDU_Busoff "总线通讯失效";
CM_ SG_ 1553 CDU_Lost_Communication "通讯超时";
CM_ SG_ 1553 CDU_DCDC_HVHVIL_Fault "直流输出高压互锁异常";
CM_ SG_ 1553 CDU_DC_DTC "DCDC diagnostic error code
（DC诊断故障码）.";
CM_ SG_ 538 Checksum_0x21A "Checksum: IDMSB XOR IDLSB XOR Byte1 XOR Byte2 XOR Byte3 XOR Byte4 XOR Byte5 XOR Byte6XOR Byte7";
CM_ SG_ 538 GCU_Actual_Speed "发电机实际转速";
CM_ SG_ 538 GCU_IverterTempWarning "控制器温度报警";
CM_ SG_ 538 GCU_MotorTempWarning "发电机温度报警";
CM_ SG_ 538 GCU_Actual_Torque "发电机实际转矩";
CM_ SG_ 538 GCU_work_mode "发电机工作状态";
CM_ SG_ 538 GCU_Motor_Temperature "发电机温度";
CM_ SG_ 538 GCU_Controller_temperature "控制器温度";
CM_ SG_ 538 GCU_Fail_Grade "故障等级";
CM_ SG_ 538 GCU_MILReq "GCU request Mil lamp
GCU请求亮故障灯";
CM_ SG_ 538 Rolling_counter_0x21A "RollingCounter: used 4bit length signal and the arithmetic is increased from 0 to 15 by every message.";
CM_ SG_ 539 GCU_DTC_CODE "DTC CODE";
CM_ SG_ 539 GCU_MotorNumber "电机序号";
CM_ SG_ 539 GCU_DC_Current "直流侧电流";
CM_ SG_ 539 GCU_DC_Voltage "直流侧电压";
CM_ SG_ 539 GCU_P2_Hardware_code "硬件故障码";
CM_ SG_ 626 Checksum_0x272 "Checksum: IDMSB XOR IDLSB XOR Byte1 XOR Byte2 XOR Byte3 XOR Byte4 XOR Byte5 XOR Byte6XOR Byte7";
CM_ SG_ 626 EMS_PSNotActiveTimeAccu "Propulsion System Not Active Time Accumulation
驱动系统累计未激活时间(HEV)";
CM_ SG_ 626 EMS_EngineSpeed "Current engine speed";
CM_ SG_ 626 EMS_EngineStatus "Engine state
发动机状态";
CM_ SG_ 626 EMS_DesireIdleSpeed "Desired idle speed
目标怠速转速";
CM_ SG_ 626 Rolling_counter_0x272 "RollingCounter: used 4bit length signal and the arithmetic is increased from 0 to 15 by every message.";
CM_ SG_ 627 Checksum_0x273 "Checksum: IDMSB XOR IDLSB XOR Byte1 XOR Byte2 XOR Byte3 XOR Byte4 XOR Byte5 XOR Byte6XOR Byte7";
CM_ SG_ 627 EMS_MilLampRequest "ECU request Mil lamp";
CM_ SG_ 627 EMS_SVSLampRequest "ECU request SVS lamp";
CM_ SG_ 627 EMS_LowOilPressure "机油压力低状态位";
CM_ SG_ 627 EMS_FuelLevelFaultActive "燃油液位传感器故障状态位";
CM_ SG_ 627 EMS_FuelConsumption "Engine fuel consume(100ms)";
CM_ SG_ 627 EMS_Fuellevel "油位信息(HEV)";
CM_ SG_ 627 EMS_EngineCoolantTemperature "Engine Coolant Temperature
发动机冷却水温";
CM_ SG_ 627 Rolling_counter_0x273 "RollingCounter: used 4bit length signal and the arithmetic is increased from 0 to 15 by every message.";
CM_ SG_ 1377 VBU_MotorcoV "电机冷却液位电压差";
CM_ SG_ 1377 VBU_BattcolV "电池冷却液位电压差";
CM_ SG_ 1377 VBU_MotorLoopInputTemp "电机回路入口水温";
CM_ SG_ 1377 VBU_APULoopOutputTemp "增程器回路出口水温(HEV)";
CM_ SG_ 1377 VBU_IG1input "ON硬线输入";
CM_ SG_ 1377 VBU_startinput "Start硬线输入";
CM_ SG_ 1377 VBU_OBCwakeupVBU "OBC硬线唤醒VBU";
CM_ SG_ 1377 VBU_wakeupCDU "VBU硬线唤醒CDU";
CM_ SG_ 1377 VBU_VBUwakeupGCU "VBU硬线唤醒GCU(HEV)";
CM_ SG_ 1377 VBU_VacuumPumpRelay "真空泵继电器控制";
CM_ SG_ 1377 VBU_WPTCRelay "WPTC继电器控制";
CM_ SG_ 1377 VBU_EMSRelay "EMS继电器控制(HEV)";
CM_ SG_ 1377 VBU_ThermRunAwaywakeup "热失控唤醒VBU";
CM_ SG_ 1377 VBU_MotorPumpPWM "电机水泵输出占空比";
CM_ SG_ 1377 VBU_BattPumpPWM "电池水泵输出占空比";
CM_ SG_ 597 AC_OutletTemperature1 "出风口温度1（适用纯电和增程）";
CM_ SG_ 597 AC_OutletTemperature2 "出风口温度2（适用纯电和增程）";
CM_ SG_ 597 AC_EvaporatorTemp "蒸发器温度信号（适用纯电和增程）";
CM_ SG_ 597 AC_RefriPressure "制冷剂压力信号（适用纯电和增程）";
CM_ SG_ 597 AC_PWM_APTC "APTC的PWM信号（适用纯电）
0-10%：停止
11-95%：比例调功率
95%以上：全功率";
CM_ SG_ 597 AC_VBU_FanPWMReq "冷却风扇PWM请求（适用纯电和增程）";
CM_ SG_ 597 AC_VBU_APTCPwrReq "空气PTC请求功率（适用纯电）";
CM_ SG_ 597 AC_VBU_EACPwrReq "压缩机请求功率（适用纯电和增程）";
CM_ SG_ 546 PEPS_PEPSFailStatus "PEPS系统故障报警";
CM_ SG_ 546 PEPS_WarningKeyNotInCar "钥匙不在车内报警";
CM_ SG_ 546 PEPS_WarningKeyInCar "钥匙在车内报警 ";
CM_ SG_ 546 PEPS_WarningIgNotOff "电源未关报警";
CM_ SG_ 546 PEPS_WarningKeyLowBattery "钥匙电池电量低报警";
CM_ SG_ 546 PEPS_WarningStartupNotBrake "启动时请踩下刹车提醒";
CM_ SG_ 546 PEPS_WarningKeyNearbyIMMO "请将智能钥匙放在应急感应区以启动车辆";
CM_ SG_ 546 PEPS_BackDoorKeyState "后背门区域智能钥匙状态";
CM_ SG_ 546 PEPS_KeyPosition "钥匙位置";
CM_ SG_ 546 PEPS_HandshakeFail "MAINMCU和AUXMCU之间的通讯故障";
CM_ SG_ 546 PEPS_Authpasstype "一级防盗认证通过原因";
CM_ SG_ 546 PEPS_EnableWirelessCharging "无线充电允许信号（预留）";
CM_ SG_ 546 PEPS_DHA_LeftHandleSwitch "左门把手解闭锁请求";
CM_ SG_ 546 PEPS_PHA_RightHandleSwitch "右门把手解闭锁请求";
CM_ SG_ 546 DHA_LockFlag "驾驶侧门把手解闭锁动作（BCM转发LIN4的0x12报文内的DHA_LockFlag至body CAN）";
CM_ SG_ 546 PHA_LockFlag "副驾驶侧门把手解闭锁动作（BCM转发LIN4的0x13报文内的PHA_LockFlag至body CAN）";
CM_ SG_ 852 PEPS_Driver_Antenna_Error "外部主驾门天线故障";
CM_ SG_ 852 PEPS_Passenger_Antenna_Error "外部副驾门天线故障";
CM_ SG_ 852 PEPS_Trunk_Antenna_Error "外部后背门天线故障";
CM_ SG_ 852 BCM_HU_DoorLocksetFB "BCM反馈的当前解锁设置模式";
CM_ SG_ 852 PEPS_Facia_Antenna_Error "内部前排天线故障";
CM_ SG_ 852 PEPS_Rear_Antenna_Error "内部后排天线故障";
CM_ SG_ 852 PEPS_Handrail_Antenna_Error "内部IMMO天线故障";
CM_ SG_ 852 PEPS_unexpected_lock_RSSI "防误锁钥匙场强数据";
CM_ SG_ 852 PEPS_mislock_Antenna "防误锁搜到钥匙的天线编号";
CM_ SG_ 852 PEPS_ID_CAB_LIST "车内钥匙列表：1-在车内 0-不在车内
bit0: 1号钥匙状态 
bit1: 2号钥匙状态 
bit2: 3号钥匙状态 
bit3: 4号钥匙状态 ";
CM_ SG_ 852 PEPS_RecentlyKEYTypeCmd "智能钥匙上一次锁类型命令";
CM_ SG_ 852 PEPS_KeyLessCodeNumber "最近一把认证合法的钥匙";
CM_ SG_ 852 PEPS_PROSts "电源继电器驱动输出状态，3个bit从低到高分别表示 ACC/IGN1/IGN2继电器输出状态 0：没有输出 1：输出使能";
CM_ SG_ 852 PEPS_PRDErr "电源继电器驱动电路故障，3个bit从低到高分别表示 ACC/IGN1/IGN2继电器输出驱动 电路故障状态 0：没有故障 1：发生故障";
CM_ SG_ 912 DSM_MirrorRdownSetStatus "后视镜倒车自动翻转功能设置反馈";
CM_ SG_ 912 DSM_LeftMirrorPosition_SX "左后视镜上下位置";
CM_ SG_ 912 DSM_SeatMotorSts "座椅电机状态";
CM_ SG_ 912 DSM_LeftMirrorPosition_ZY "左后视镜左右位置";
CM_ SG_ 912 DSM_MirrorSts "外后视镜状态";
CM_ SG_ 912 DSM_RightMirrorPosition_SX "右后视镜上下位置";
CM_ SG_ 912 DSM_RightMirrorPosition_ZY "右后视镜左右位置";
CM_ SG_ 912 DSM_LeftMirrorMotor1fault "左侧后视镜上下调节电机故障";
CM_ SG_ 912 DSM_LeftMirrorMotor2fault "左侧后视镜左右调节电机故障";
CM_ SG_ 912 DSM_RightMirrorMotor1fault "右侧后视镜上下调节电机故障";
CM_ SG_ 912 DSM_RightMirrorMotor2fault "右侧后视镜左右调节电机故障";
CM_ SG_ 912 DSM_WorkMode "DSM工作模式";
CM_ SG_ 912 DSM_LM_DirectionSts_SX "左侧后视镜上下调节电机（LMSX）运动方向";
CM_ SG_ 912 DSM_LM_DirectionSts_ZY "左侧后视镜左右调节电机（LMZY）运动方向";
CM_ SG_ 912 DSM_RM_DirectionSts_SX "右侧后视镜上下调节电机（RMSX）运动方向";
CM_ SG_ 912 DSM_RM_DirectionSts_ZY "右侧后视镜左右调节电机（RMZY）运动方向";
CM_ SG_ 912 DSM_CalibrationAlarm "座椅需要自学习提示（信号预留）";
CM_ SG_ 912 DSM_PSMsettemp "副驾驶侧座椅记忆温度";
CM_ SG_ 912 DSM_CalibrationSts "座椅自学习状态";
CM_ SG_ 912 DSM_DSMsettemp "驾驶侧座椅记忆温度";
CM_ SG_ 820 IBS_U_BATT "Battery voltage";
CM_ SG_ 820 IBS_I_Range "Battery current range";
CM_ SG_ 820 IBS_I_BATT "Battery current（此信号的Resolution是可变的，信号解析请参考博世提供的IBS功能规范）";
CM_ SG_ 820 IBS_T_BATT "Battery temperature";
CM_ SG_ 820 IBS_IBATT_QUIESCENT "Battery quiescent
current";
CM_ SG_ 820 IBS_Status_Current "current Status";
CM_ SG_ 820 IBS_Status_Voltage "Voltage Status";
CM_ SG_ 820 IBS_Status_Temp "Temperature Status ";
CM_ SG_ 820 IBS_ERROR_Calib "error in calibration data";
CM_ SG_ 820 IBS_ERROR_IDENT "error in ECU indentification";
CM_ SG_ 820 IBS_Resp_Error "LIN Response Error ";
CM_ SG_ 820 IBS_FLAG_INCONSISTENCY "Battery inconsistency flag";
CM_ SG_ 821 IBS_SOC "State of Charge ";
CM_ SG_ 821 IBS_SOH_SUL "max. possible SOC, reduced by sulphation";
CM_ SG_ 821 IBS_SOH_LAM "State of health (Loss of active mass)";
CM_ SG_ 821 IBS_SOH_COR "State of health (corrosion)";
CM_ SG_ 821 IBS_SOC_STATE "SOC Status";
CM_ SG_ 821 IBS_SOH_SUL_STATE "SOH_SUL Status ";
CM_ SG_ 821 IBS_SOH_LAM_STATE "SOH_LAM Status";
CM_ SG_ 821 IBS_SOH_COR_STATE "SOH_COR Status";
CM_ SG_ 821 GW_Diagtester_inputactive "GW诊断仪插入检测激活,GW PIN7输入有效";
CM_ SG_ 931 HU_AC_SystemSet "空调开关";
CM_ SG_ 931 HU_AC_Cycle "空调内外循环";
CM_ SG_ 931 HU_AC_EAC_Control "压缩机开关";
CM_ SG_ 931 HU_AC_AutoMode_Set "Auto模式";
CM_ SG_ 931 HU_AC_WindMode_Set "吹风模式";
CM_ SG_ 931 HU_AC_BlowingRate_Set "风量调节";
CM_ SG_ 931 HU_AC_APTCSW_Set "APTC开关";
CM_ SG_ 931 HU_AC_Temp_set "温度调节";
CM_ SG_ 931 HU_AC_BackLOCK_Set "后排空调调节锁定";
CM_ SG_ 931 HU_PowerManagerState "HU电源管理状态";
CM_ SG_ 933 HU_LanguageSet "语言设置";
CM_ SG_ 933 HU_TimeSet_DisplayMode "时间显示形式设置";
CM_ SG_ 933 HU_TimeSet_AutoMode "时间自动更新设置";
CM_ SG_ 933 HU_TBOXwelcomeReq_set "TBOX迎宾请求disable设置";
CM_ SG_ 933 HU_TimeSet_Hour "0~23:valid hour
24~31:Reserved
手动设置时间";
CM_ SG_ 933 HU_TimeSet_Minutes "0~59:valid min
60~63:Reserved
手动设置时间";
CM_ SG_ 933 HU_TBOX_Reboot "HU  Reboot TBOX";
CM_ SG_ 933 HU_RemoteCharge_StartHour "APP发送的预约充电开启时间----时
0x0-0x17: Hour
0x18-0x1E: Invalid
(不触发时发默认值，触发设置被确认时发3帧有效值，然后回到默认值）";
CM_ SG_ 933 HU_RemoteCharge_Startmin "APP发送的预约充电开启时间----分
0x0-0x3B: Minute
0x3C-0x3E: Invalid
(不触发时发默认值，触发设置被确认时发3帧有效值，然后回到默认值）
";
CM_ SG_ 933 HU_RemoteCharge_Set "定时充电开启设置";
CM_ SG_ 933 HU_RemotCh_Full_SetSts "HU 发送给 TBOX 的是否充满设置";
CM_ SG_ 933 HU_RemoteCharge_EndHour "APP发送的预约充电结束时间----时
0x0-0x17: Hour
0x18-0x1E: Invalid
(不触发时发默认值，触发设置被确认时发3帧有效值，然后回到默认值）";
CM_ SG_ 933 HU_RemoteCharge_Endmin "APP发送的预约充电结束时间----分
0x0-0x3B: Minute
0x3C-0x3E: Invalid
(不触发时发默认值，触发设置被确认时发3帧有效值，然后回到默认值）
";
CM_ SG_ 816 BCM_reversingLampSW "倒车灯状态";
CM_ SG_ 816 BCM_Rsp_HU_Daylight "BCM反馈给HU的日间行车灯控制状态";
CM_ SG_ 816 BCM_CarpetlampSW "地毯灯状态";
CM_ SG_ 816 BCM_CarpetlampSWSetsts "地毯灯开关设置状态";
CM_ SG_ 816 BCM_HU_RLSModeSts "雨天关窗功能设置状态";
CM_ SG_ 816 BCM_FrontdecoralampSW "前部贯穿灯状态";
CM_ SG_ 816 BCM_WinCloseReminder "雨天关窗提醒(BCM接受RLS雨天关窗激活请求后，发送全局关窗指令，开启10秒计时器；10 秒 计 时 器 内 ， 若 车 窗 全 部 关 闭 /未全部关闭后 ， 发 送 6 帧 雨 天 关 窗 提 醒 执 行 成 功/失败)";
CM_ SG_ 816 BCM_DomeLampDoorControl "顶灯门控功能关闭设置状态(预留）";
CM_ SG_ 816 BCM_LockWelcomeSts "闭锁迎宾模式状态（预留）";
CM_ SG_ 816 BCM_PEPSLockReason "PEPS触发门锁闭锁原因，BCM_LockReason=0x2时更新此信号，BCM_LockReason非0x2时发默认发0x0";
CM_ SG_ 816 BCM_PEPSUnLockReason "PEPS触发门锁解锁原因，BCM_UnLockReason=0x2时更新此信号，BCM_UnLockReason=0x2非0x2时发默认发0x0";
CM_ SG_ 816 BCM_ESCLConfig "ESCL配置";
CM_ SG_ 816 BCM_RLS_All_WdwClosed_Sts "车窗关闭状态";
CM_ SG_ 816 BCM_FollowMeControlsts "伴我回家功能开关设置状态";
CM_ SG_ 816 BCM_FollowMeDelayTSetsts "伴我回家时间设置状态";
CM_ SG_ 816 BCM_RR_LED2_Error "右后保LED转向灯故障反馈输入状态";
CM_ SG_ 816 BCM_AutoLockSetsts "自动落锁功能开关设置状态";
CM_ SG_ 816 BCM_RL_LED2_Error "左后保LED转向灯故障反馈输入状态";
CM_ SG_ 816 BCM_WindowAutoUPSetsts "锁车自动升四窗功能开关设置状态";
CM_ SG_ 816 BCM_FL_LED_Error "左前LED转向灯故障反馈输入状态";
CM_ SG_ 816 BCM_FR_LED_Error "右前LED转向灯故障反馈输入状态";
CM_ SG_ 816 BCM_RL_LED1_Error "左后尾门LED转向灯故障反馈输入状态";
CM_ SG_ 816 BCM_RR_LED1_Error "右后尾门LED转向灯故障反馈输入状态";
CM_ SG_ 816 BCM_SSB1_inputSts "BCM采集的SSB 硬线信号状态";
CM_ SG_ 816 BCM_SSB2_inputSts "BCM采集的SSB 硬线信号状态";
CM_ SG_ 816 BCM_LockReason "门锁闭锁原因";
CM_ SG_ 816 BCM_UnLockReason "门锁解锁原因";
CM_ SG_ 816 BCM_ACU_Crash_inputsts "BCM采集的ACU碰撞硬线信号状态";
CM_ SG_ 816 BCM_ESCL_UnlockFB_inputsts "BCM采集的ESCLUnlockFB硬线信号状态";
CM_ SG_ 816 BCM_ESCL_Motorpower_outputsts "BCM输出给ESCL的Motor power硬线信号状态";
CM_ SG_ 816 BCM_ESCL_LockEnable_outputsts "BCM输出给ESCL的Lock Enable硬线信号状态";
CM_ SG_ 816 BCM_ESCL_UnLockfail "ESCL 解锁失败";
CM_ SG_ 816 BCM_ESCL_Lockfail "ESCL 上锁失败";
CM_ SG_ 816 BCM_waterlightlimit "流水灯功能禁止信号";
CM_ SG_ 961 Tbox_ICM_ODOTotal "TBOX备份的ODO 总里程 (平台判断里程跳变--》异常跳变人工审核--》人工确认下发TBOX正确里程值--》TBOX收到下发ICM刷新）";
CM_ SG_ 961 Tbox_ICM_Prevmaintmileage "TBOX备份的上次保养里程";
CM_ SG_ 1281 TPMS_FL_Pressure_value " Front Left tire Pressure";
CM_ SG_ 1281 TPMS_FR_Pressure_value " Front Right tire Pressure";
CM_ SG_ 1281 TPMS_RL_Pressure_value " Rear Left tire Pressure";
CM_ SG_ 1281 TPMS_RR_Pressure_value " Rear Right tire Pressure";
CM_ SG_ 1281 TPMS_FL_Temperature " Front Left tire Temperature";
CM_ SG_ 1281 TPMS_FR_Temperature " Front Right tire Temperature";
CM_ SG_ 1281 TPMS_RR_Temperature " Rear Right tire Temperature";
CM_ SG_ 1281 TPMS_RL_Temperature " Rear Left tire Temperature";
CM_ SG_ 642 Checksum_0x282 "Checksum: IDMSB XOR IDLSB XOR Byte1 XOR Byte2 XOR Byte3 XOR Byte4 XOR Byte5 XOR Byte6XOR Byte7";
CM_ SG_ 642 SCM_LKS_Switch "车道辅助开关信号（高配）";
CM_ SG_ 642 SCM_TimeGap_Select_Switch "时距加减开关信号（高配）";
CM_ SG_ 642 SCM_ACC_Switch "自适应巡航开启/关闭开关信号（高配）";
CM_ SG_ 642 SCM_Res_Set_Switch "巡航Res+/Set-开关信号（全配）";
CM_ SG_ 642 SCM_LKS_Switch_Invalid "车道辅助开关信号（高配）无效信号";
CM_ SG_ 642 SCM_TurnIndicator_Switch "转向灯开关信号（全配）";
CM_ SG_ 642 SCM_Flash_Switch "闪光灯开关信号（全配）";
CM_ SG_ 642 SCM_Flash_Switch_Sts "闪光灯开关故障状态（全配）";
CM_ SG_ 642 SCM_HiBeam_Switch "远光灯信号（全配）";
CM_ SG_ 642 SCM_HiBeam_Switch_Sts "远光灯开关故障状态（全配）";
CM_ SG_ 642 SCM_Fwiper_Mist_Switch "前雨刮点动/洗涤开关（全配）";
CM_ SG_ 642 SCM_FWiper_Switch "前雨刮开关（全配）";
CM_ SG_ 642 SCM_RWiper_Switch "后雨刮开关（全配）";
CM_ SG_ 642 SCM_PRND_req "PRND档位请求（全配）";
CM_ SG_ 642 Counter_0x282 "RollingCounter: used 4bit length signal and the arithmetic is increased from 0 to 15 by every message.";
CM_ SG_ 373 Checksum_0x175 "Checksum: IDMSB XOR IDLSB XOR Byte1 XOR Byte2 XOR Byte3 XOR Byte4 XOR Byte5 XOR Byte6 XOR Byte7";
CM_ SG_ 373 SAS_SteerWheelAngle "The current angle of the steering wheel（Positive, to left; Negative, to right）
转向角度，左正右负";
CM_ SG_ 373 SAS_SteerWheelRotSpd "The current rotation speed of the steering wheel.
转向角速度";
CM_ SG_ 373 SAS_SteerWheelRotSpdStatus "The status of SteerWheelRotSpd
转向角速度有效性";
CM_ SG_ 373 SAS_SASStsSnsr "the flag of  SAS status
Punch:Steering angle status
SAS硬件故障状态";
CM_ SG_ 373 EPS_SteeringTorque "施加在方向盘上的驾驶员手力矩，左正右负
Driver steering torque，left+/right-";
CM_ SG_ 373 EPS_SteeringTorqueValid "Validation bit of torsion bar torque";
CM_ SG_ 373 SAS_SASStsCal "The calibration status of SAS
传感器标定状态";
CM_ SG_ 373 Rolling_counter_0x175 "RollingCounter: used 4bit length signal and the arithmetic is increased from 0 to 15 by every message.";
CM_ SG_ 1424 VBU_BMS_BattSerialNumber "序列号
GBT 34014-4.3.7";
CM_ SG_ 1424 VBU_BMS_BattManuYear "电池生产年
GBT 34014-4.3.6";
CM_ SG_ 1424 VBU_BMS_BattManuMonth "电池生产月
GBT 34014-4.3.6";
CM_ SG_ 1424 VBU_BMS_BattManuDay "电池生产日
GBT 34014-4.3.6";
CM_ SG_ 1425 VBU_BMS_BattSupplierCode "电池厂商代码
GBT 34014 附录A.1 ASCII码解析";
CM_ SG_ 1425 VBU_BMS_ProductTypeCode "产品类型代码
,GBT 34014 附录A.1ASCII码解析";
CM_ SG_ 1425 VBU_BMS_BattTypeCode "电池类型代码
GBT 34014 附录A.1ASCII码解析";
CM_ SG_ 1425 VBU_BMS_BattSpecCode "电池规格代码
GBT 34014 附录A.1ASCII码解析";
CM_ SG_ 1426 VBU_BMS_BattRetrospectCode "电池追溯码
GBT 34014-4.3.5";
CM_ SG_ 1427 VBU_BMS_BattS_Num "电池序列号";
CM_ SG_ 1427 VBU_BMS_BattRecycleCode "电池梯级利用代码";
CM_ SG_ 1428 VBU_BMS_BattCodeLenth "可充电储能系统编码长度
GBT 32960.3 T-6";
CM_ SG_ 1428 VBU_BMS_Temp_ProbeNum "动力蓄电池温度探针总数
GBT 32960.3 T-B.8";
CM_ SG_ 1428 VBU_BMS_PackageTotalNum "电池包总数
GBT 32960.3 T-B.6";
CM_ SG_ 1428 VBU_BMS_CellTotalNum "单体蓄电池总数
GBT 32960.3 T-B.6";
CM_ SG_ 1429 VBU_BMS_PackSOH "电池生命健康度";
CM_ SG_ 1429 VBU_BMS_RelayCutOffNum "继电器带载切断次数";
CM_ SG_ 1429 VBU_BMS_PackSOE "电池剩余能量";
CM_ SG_ 1429 VBU_BMS_TempDev_GBT32960 "温度差异报警";
CM_ SG_ 1429 VBU_BMS_TempOver_GBT32960 "电池高温报警";
CM_ SG_ 1429 VBU_BMS_CellVoltOver_GBT32960 "单体蓄电池过压报警";
CM_ SG_ 1429 VBU_BMS_PackVoltOver_GBT32960 "动力蓄电池包过压报警";
CM_ SG_ 1429 VBU_BMS_CellVoltLow_GBT32960 "单体蓄电池欠压报警";
CM_ SG_ 1429 VBU_BMS_PackVoltLow_GBT32960 "动力蓄电池包欠压报警";
CM_ SG_ 1429 VBU_BMS_BattOverCharge_GBT32960 "动力电池过充报警";
CM_ SG_ 1429 VBU_BMS_Iso_GBT32960 "绝缘报警";
CM_ SG_ 1429 VBU_BMS_SocSkip_GBT32960 "SOC跳变报警";
CM_ SG_ 1429 VBU_BMS_BattMismatch_GBT32960 "动力蓄电池包不匹配";
CM_ SG_ 1429 VBU_BMS_SocLow_GBT32960 "SOC低报警";
CM_ SG_ 1429 VBU_BMS_SocOverHigh_GBT32960 "SOC过高报警";
CM_ SG_ 1429 VBU_BMS_CellVolDev_GBT32960 "动力蓄电池一致性差报警";
CM_ SG_ 1429 VBU_BMS_ThermRunAway_GB38031 "动力蓄电池热失控报警";
CM_ SG_ 1429 VBU_BMS_RegenOverCurr_GB38031 "动力蓄电池回馈过流报警";

BA_DEF_ BO_  "NmMessage" ENUM "No","Yes";
BA_DEF_ BO_  "GenMsgSendType" ENUM  "cyclic","IfActive","Event","CA","CE","NoMsgSendType";
BA_DEF_ BO_  "GenMsgCycleTime" INT 0 0;
BA_DEF_ SG_  "GenSigSendType" ENUM  "cyclic","OnChange","OnWrite","IfActive","OnChangeWithRepetition","OnWriteWithRepetition","IfActiveWithRepetition","NoSigSendType","OnChangeAndIfActive", "OnChangeAndIfActiveWithRepetition","CA","CE","Event";
BA_DEF_ SG_  "GenSigStartValue" INT 0 0;
BA_DEF_ BO_  "GenMsgNrOfRepetition" INT 0 0;
BA_DEF_  "DBName" STRING ;
BA_DEF_ BU_  "NodeLayerModules" STRING ;
BA_DEF_ BU_  "NmNode" ENUM  "Not","Yes";
BA_DEF_  "NmBaseAddress" HEX 0 2047;
BA_DEF_  "NmMessageCount" INT 0 255;
BA_DEF_  "BusType" STRING ;

BA_DEF_DEF_  "NmMessage" "No";
BA_DEF_DEF_  "GenMsgSendType" "cyclic";
BA_DEF_DEF_  "GenMsgCycleTime" 0;
BA_DEF_DEF_  "GenSigSendType" "cyclic";
BA_DEF_DEF_  "GenSigStartValue" 0;
BA_DEF_DEF_  "GenMsgNrOfRepetition" 0;
BA_DEF_DEF_  "DBName" "";
BA_DEF_DEF_  "NodeLayerModules" "CANoeILNLVector.dll";
BA_DEF_DEF_  "NmNode" "Not";
BA_DEF_DEF_  "NmBaseAddress" 1024;
BA_DEF_DEF_  "NmMessageCount" 128;
BA_DEF_DEF_  "BusType" "CAN";
BA_ "DBName" "IC321_TboxCAN_CMatrix_V3.1";
BA_ "GenMsgCycleTime" BO_ 374 10;
BA_ "GenMsgCycleTime" BO_ 375 10;
BA_ "GenMsgCycleTime" BO_ 529 20;
BA_ "GenMsgCycleTime" BO_ 580 20;
BA_ "GenMsgCycleTime" BO_ 674 50;
BA_ "GenMsgNrOfRepetition" BO_ 674 50;
BA_ "GenSigSendType" SG_ 674 HU_Audio_AP_Request 1;
BA_ "GenSigSendType" SG_ 674 HU_Audio_Request_Command 1;
BA_ "GenSigSendType" SG_ 674 HU_APS_FunSW 1;
BA_ "GenSigSendType" SG_ 674 HU_AVM_ViewModeSwitch 1;
BA_ "GenMsgCycleTime" BO_ 608 100;
BA_ "GenSigStartValue" SG_ 608 EPS_SafeLampRed 1;
BA_ "GenMsgCycleTime" BO_ 1519 10000;
BA_ "GenMsgSendType" BO_ 811 2;
BA_ "GenSigSendType" SG_ 811 VBU_WakeUpRMCU 12;
BA_ "GenMsgCycleTime" BO_ 579 20;
BA_ "GenMsgCycleTime" BO_ 913 100;
BA_ "GenMsgCycleTime" BO_ 1507 5000;
BA_ "GenMsgCycleTime" BO_ 801 100;
BA_ "GenSigStartValue" SG_ 801 CSW_WindowLOCK_GW 2;
BA_ "GenMsgCycleTime" BO_ 832 100;
BA_ "GenSigSendType" SG_ 832 BCM_RKE_lock_Unlock_req 1;
BA_ "GenMsgSendType" BO_ 64 2;
BA_ "GenSigSendType" SG_ 64 PEPS_RKECommand 1;
BA_ "GenSigSendType" SG_ 64 PEPS_TrunkReleaseReq 1;
BA_ "GenSigSendType" SG_ 64 PEPS_DoorUnlockReq 1;
BA_ "GenSigSendType" SG_ 64 PEPS_DoorlockReq 1;
BA_ "GenMsgCycleTime" BO_ 735 100;
BA_ "GenSigSendType" SG_ 735 HU_DirverSLV_Direction_set 1;
BA_ "GenSigSendType" SG_ 735 HU_DirverSHV_Direction_set 1;
BA_ "GenSigSendType" SG_ 735 HU_DirverLNV_Direction_set 1;
BA_ "GenSigSendType" SG_ 735 HU_PassagerSLV_Direction_set 1;
BA_ "GenSigSendType" SG_ 735 HU_PassagerSHV_Direction_set 1;
BA_ "GenSigSendType" SG_ 735 HU_PassagerLNV_Direction_set 1;
BA_ "GenSigSendType" SG_ 735 HU_DSM_heatSwitch 1;
BA_ "GenSigSendType" SG_ 735 HU_DSM_Targtemp 1;
BA_ "GenSigStartValue" SG_ 735 HU_DSM_Targtemp 63;
BA_ "GenSigSendType" SG_ 735 HU_PSM_heatSwitch 1;
BA_ "GenSigSendType" SG_ 735 HU_PSM_Targtemp 1;
BA_ "GenSigStartValue" SG_ 735 HU_PSM_Targtemp 63;
BA_ "GenSigSendType" SG_ 735 HU_DSMEasyEntrySW 1;
BA_ "GenSigSendType" SG_ 735 HU_RVMAutoFoldSW 1;
BA_ "GenSigSendType" SG_ 735 HU_RVMFoldButton 1;
BA_ "GenSigSendType" SG_ 735 HU_RVM_R_DownSW 1;
BA_ "GenSigSendType" SG_ 735 HU_Userdefined_Mirror 1;
BA_ "GenMsgCycleTime" BO_ 1506 5000;
BA_ "GenMsgCycleTime" BO_ 802 100;
BA_ "GenMsgCycleTime" BO_ 792 100;
BA_ "GenMsgCycleTime" BO_ 793 100;
BA_ "GenMsgCycleTime" BO_ 881 100;
BA_ "GenMsgCycleTime" BO_ 154 100;
BA_ "GenSigStartValue" SG_ 154 VBU_MCU_TrqReq 10000;
BA_ "GenMsgCycleTime" BO_ 155 100;
BA_ "GenSigStartValue" SG_ 155 VBU_DCDCLVVoltSet 120;
BA_ "GenMsgCycleTime" BO_ 156 100;
BA_ "GenSigStartValue" SG_ 156 VBU_TPCV1Control 20;
BA_ "GenSigSendType" SG_ 156 VBU_Cruise_Warning 1;
BA_ "GenSigStartValue" SG_ 156 VBU_TPCV2Control 20;
BA_ "GenMsgCycleTime" BO_ 157 100;
BA_ "GenMsgCycleTime" BO_ 256 50;
BA_ "GenSigStartValue" SG_ 256 VBU_BMS_PackU 8190;
BA_ "GenSigStartValue" SG_ 256 VBU_BMS_PackI 65534;
BA_ "GenMsgCycleTime" BO_ 258 50;
BA_ "GenSigStartValue" SG_ 258 VBU_BMS_RealSOC 1022;
BA_ "GenSigStartValue" SG_ 258 VBU_BMS_PackDispSoc 1022;
BA_ "GenSigStartValue" SG_ 258 VBU_BMS_CellSumVol 8190;
BA_ "GenSigStartValue" SG_ 258 VBU_BMS_LinkU 8190;
BA_ "GenMsgCycleTime" BO_ 261 100;
BA_ "GenSigStartValue" SG_ 261 VBU_BMS_Insulation_positive 1022;
BA_ "GenSigStartValue" SG_ 261 VBU_BMS_Insulation_negative 1022;
BA_ "GenMsgCycleTime" BO_ 274 100;
BA_ "GenSigStartValue" SG_ 274 VBU_BMS_MaxCellU 5093;
BA_ "GenSigStartValue" SG_ 274 VBU_BMS_MinCellU 5093;
BA_ "GenSigStartValue" SG_ 274 VBU_BMS_CellVolDev 4093;
BA_ "GenMsgCycleTime" BO_ 277 100;
BA_ "GenMsgCycleTime" BO_ 278 100;
BA_ "GenMsgCycleTime" BO_ 276 100;
BA_ "GenSigStartValue" SG_ 276 VBU_DischargeDepthFeedBack 127;
BA_ "GenSigStartValue" SG_ 276 VBU_BMS_InputWaterTemp 252;
BA_ "GenSigStartValue" SG_ 276 VBU_BMS_OutputWaterTemp 252;
BA_ "GenMsgCycleTime" BO_ 279 100;
BA_ "GenSigStartValue" SG_ 279 VBU_ActualPowerPer 100;
BA_ "GenSigStartValue" SG_ 279 VBU_ExchangerInputWaterTemp 65;
BA_ "GenMsgCycleTime" BO_ 1441 500;
BA_ "GenMsgCycleTime" BO_ 1442 500;
BA_ "GenMsgCycleTime" BO_ 1443 500;
BA_ "GenMsgCycleTime" BO_ 1444 500;
BA_ "GenMsgCycleTime" BO_ 1445 500;
BA_ "GenMsgCycleTime" BO_ 320 20;
BA_ "GenSigStartValue" SG_ 320 VBU_CurrentMotorTorq 10000;
BA_ "GenSigStartValue" SG_ 320 VBU_MaxMotorTorque 10000;
BA_ "GenSigStartValue" SG_ 320 VBU_MiNMotorTorque 10000;
BA_ "GenMsgCycleTime" BO_ 321 20;
BA_ "GenSigStartValue" SG_ 321 VBU_DriverDemandTorq 10000;
BA_ "GenMsgCycleTime" BO_ 322 20;
BA_ "GenSigStartValue" SG_ 322 VBU_vacuumpumpsensorRelvalue 540;
BA_ "GenSigStartValue" SG_ 322 VBU_MCU_MotorSpeed 65534;
BA_ "GenMsgCycleTime" BO_ 336 20;
BA_ "GenMsgCycleTime" BO_ 337 20;
BA_ "GenMsgCycleTime" BO_ 734 100;
BA_ "GenSigSendType" SG_ 734 HU_SubMileage_Reset 1;
BA_ "GenSigSendType" SG_ 734 HU_EPB_FunctionSet 1;
BA_ "GenSigSendType" SG_ 734 HU_ShowCarMode_Req 1;
BA_ "GenSigSendType" SG_ 734 HU_EnergyRecoveryPer 1;
BA_ "GenSigStartValue" SG_ 734 HU_EnergyRecoveryPer 127;
BA_ "GenSigSendType" SG_ 734 HU_SpeedLimitSW 1;
BA_ "GenSigSendType" SG_ 734 HU_LimitSpeedSet 1;
BA_ "GenSigStartValue" SG_ 734 HU_LimitSpeedSet 255;
BA_ "GenSigSendType" SG_ 734 HU_EnergyMode 1;
BA_ "GenSigSendType" SG_ 734 HU_RestSwitch_Set 1;
BA_ "GenSigSendType" SG_ 734 HU_DriveMode 1;
BA_ "GenSigSendType" SG_ 734 HU_AccelerationModePer 1;
BA_ "GenSigStartValue" SG_ 734 HU_AccelerationModePer 127;
BA_ "GenSigSendType" SG_ 734 HU_DMS_SW 1;
BA_ "GenMsgCycleTime" BO_ 1451 1000;
BA_ "GenSigStartValue" SG_ 1451 VBU_BMS_FastChargeInfoU 8190;
BA_ "GenSigStartValue" SG_ 1451 VBU_BMS_FastChargeSOE 1022;
BA_ "GenSigStartValue" SG_ 1451 VBU_BMS_FastChargeInfoI 65534;
BA_ "GenMsgCycleTime" BO_ 1452 1000;
BA_ "GenMsgCycleTime" BO_ 1450 1000;
BA_ "GenMsgSendType" BO_ 314 2;
BA_ "GenSigSendType" SG_ 314 VBU_Reserved_ID1 1;
BA_ "GenMsgSendType" BO_ 315 2;
BA_ "GenSigSendType" SG_ 315 TBOX_Reserved_ID1 1;
BA_ "GenMsgCycleTime" BO_ 1324 100;
BA_ "GenMsgCycleTime" BO_ 977 100;
BA_ "GenSigStartValue" SG_ 977 CDU_TempWater 254;
BA_ "GenSigStartValue" SG_ 977 CDU_PFC_TempAct 254;
BA_ "GenSigStartValue" SG_ 977 CDU_DC_TempAct 254;
BA_ "GenSigStartValue" SG_ 977 CDU_Inside_Air_TempAct 254;
BA_ "GenSigStartValue" SG_ 977 CDU_LLC_TempAct 254;
BA_ "GenMsgCycleTime" BO_ 978 100;
BA_ "GenSigStartValue" SG_ 978 CDU_OBC_ACVolt 510;
BA_ "GenSigStartValue" SG_ 978 CDU_OBC_ACCUrr 510;
BA_ "GenMsgCycleTime" BO_ 979 200;
BA_ "GenMsgCycleTime" BO_ 592 100;
BA_ "GenMsgCycleTime" BO_ 392 100;
BA_ "GenMsgCycleTime" BO_ 1552 200;
BA_ "GenMsgCycleTime" BO_ 1553 200;
BA_ "GenMsgCycleTime" BO_ 538 50;
BA_ "GenSigStartValue" SG_ 538 GCU_Actual_Speed 7000;
BA_ "GenSigStartValue" SG_ 538 GCU_Actual_Torque 2000;
BA_ "GenSigStartValue" SG_ 538 GCU_Motor_Temperature 40;
BA_ "GenSigStartValue" SG_ 538 GCU_Controller_temperature 40;
BA_ "GenMsgCycleTime" BO_ 539 100;
BA_ "GenSigStartValue" SG_ 539 GCU_DC_Current 1000;
BA_ "GenMsgCycleTime" BO_ 626 50;
BA_ "GenMsgCycleTime" BO_ 627 100;
BA_ "GenMsgCycleTime" BO_ 1377 100;
BA_ "GenMsgCycleTime" BO_ 597 100;
BA_ "GenMsgCycleTime" BO_ 546 50;
BA_ "GenSigSendType" SG_ 546 PEPS_WarningKeyNotInCar 1;
BA_ "GenSigSendType" SG_ 546 PEPS_WarningKeyInCar 1;
BA_ "GenSigSendType" SG_ 546 PEPS_WarningIgNotOff 1;
BA_ "GenSigSendType" SG_ 546 PEPS_WarningKeyLowBattery 1;
BA_ "GenSigSendType" SG_ 546 PEPS_WarningStartupNotBrake 1;
BA_ "GenSigSendType" SG_ 546 PEPS_WarningKeyNearbyIMMO 1;
BA_ "GenSigSendType" SG_ 546 PEPS_DHA_LeftHandleSwitch 1;
BA_ "GenSigSendType" SG_ 546 PEPS_PHA_RightHandleSwitch 1;
BA_ "GenMsgCycleTime" BO_ 852 100;
BA_ "GenMsgCycleTime" BO_ 912 100;
BA_ "GenSigSendType" SG_ 912 DSM_CalibrationAlarm 1;
BA_ "GenSigStartValue" SG_ 912 DSM_PSMsettemp 34;
BA_ "GenSigStartValue" SG_ 912 DSM_DSMsettemp 34;
BA_ "GenMsgCycleTime" BO_ 820 100;
BA_ "GenSigStartValue" SG_ 820 IBS_U_BATT 16383;
BA_ "GenSigStartValue" SG_ 820 IBS_I_Range 3;
BA_ "GenSigStartValue" SG_ 820 IBS_I_BATT 65535;
BA_ "GenSigStartValue" SG_ 820 IBS_T_BATT 255;
BA_ "GenSigStartValue" SG_ 820 IBS_IBATT_QUIESCENT 255;
BA_ "GenMsgCycleTime" BO_ 821 100;
BA_ "GenSigStartValue" SG_ 821 IBS_SOC 255;
BA_ "GenSigStartValue" SG_ 821 IBS_SOH_SUL 255;
BA_ "GenSigStartValue" SG_ 821 IBS_SOH_LAM 255;
BA_ "GenSigStartValue" SG_ 821 IBS_SOH_COR 255;
BA_ "GenSigStartValue" SG_ 821 IBS_SOC_STATE 3;
BA_ "GenSigStartValue" SG_ 821 IBS_SOH_SUL_STATE 3;
BA_ "GenSigStartValue" SG_ 821 IBS_SOH_LAM_STATE 3;
BA_ "GenSigStartValue" SG_ 821 IBS_SOH_COR_STATE 3;
BA_ "GenMsgCycleTime" BO_ 931 100;
BA_ "GenSigSendType" SG_ 931 HU_AC_SystemSet 1;
BA_ "GenSigSendType" SG_ 931 HU_AC_Cycle 1;
BA_ "GenSigSendType" SG_ 931 HU_AC_EAC_Control 1;
BA_ "GenSigSendType" SG_ 931 HU_AC_AutoMode_Set 1;
BA_ "GenSigSendType" SG_ 931 HU_AC_WindMode_Set 1;
BA_ "GenSigSendType" SG_ 931 HU_AC_BlowingRate_Set 1;
BA_ "GenSigSendType" SG_ 931 HU_AC_APTCSW_Set 1;
BA_ "GenSigSendType" SG_ 931 HU_AC_Temp_set 1;
BA_ "GenSigSendType" SG_ 931 HU_AC_BackLOCK_Set 1;
BA_ "GenSigSendType" SG_ 931 HU_PowerManagerState 1;
BA_ "GenMsgCycleTime" BO_ 933 100;
BA_ "GenSigSendType" SG_ 933 HU_LanguageSet 1;
BA_ "GenSigSendType" SG_ 933 HU_TBOXwelcomeReq_set 1;
BA_ "GenSigSendType" SG_ 933 HU_TBOX_Reboot 1;
BA_ "GenSigSendType" SG_ 933 HU_RemoteCharge_StartHour 1;
BA_ "GenSigSendType" SG_ 933 HU_RemoteCharge_Startmin 1;
BA_ "GenSigSendType" SG_ 933 HU_RemoteCharge_Set 1;
BA_ "GenSigSendType" SG_ 933 HU_RemotCh_Full_SetSts 1;
BA_ "GenSigSendType" SG_ 933 HU_RemoteCharge_EndHour 1;
BA_ "GenSigStartValue" SG_ 933 HU_RemoteCharge_EndHour 31;
BA_ "GenSigSendType" SG_ 933 HU_RemoteCharge_Endmin 1;
BA_ "GenSigStartValue" SG_ 933 HU_RemoteCharge_Endmin 63;
BA_ "GenMsgCycleTime" BO_ 816 100;
BA_ "GenSigSendType" SG_ 816 BCM_WinCloseReminder 1;
BA_ "GenMsgCycleTime" BO_ 961 200;
BA_ "GenSigSendType" SG_ 961 Tbox_ICM_ODOTotal 1;
BA_ "GenSigSendType" SG_ 961 Tbox_ICM_Prevmaintmileage 1;
BA_ "GenMsgCycleTime" BO_ 1281 100;
BA_ "GenSigStartValue" SG_ 1281 TPMS_FL_Pressure_value 255;
BA_ "GenSigStartValue" SG_ 1281 TPMS_FR_Pressure_value 255;
BA_ "GenSigStartValue" SG_ 1281 TPMS_RL_Pressure_value 255;
BA_ "GenSigStartValue" SG_ 1281 TPMS_RR_Pressure_value 255;
BA_ "GenSigStartValue" SG_ 1281 TPMS_FL_Temperature 255;
BA_ "GenSigStartValue" SG_ 1281 TPMS_FR_Temperature 255;
BA_ "GenSigStartValue" SG_ 1281 TPMS_RR_Temperature 255;
BA_ "GenSigStartValue" SG_ 1281 TPMS_RL_Temperature 255;
BA_ "GenMsgCycleTime" BO_ 642 20;
BA_ "GenSigSendType" SG_ 642 SCM_LKS_Switch 1;
BA_ "GenSigSendType" SG_ 642 SCM_TimeGap_Select_Switch 1;
BA_ "GenSigSendType" SG_ 642 SCM_ACC_Switch 1;
BA_ "GenSigSendType" SG_ 642 SCM_Res_Set_Switch 1;
BA_ "GenSigSendType" SG_ 642 SCM_Flash_Switch 1;
BA_ "GenSigSendType" SG_ 642 SCM_PRND_req 1;
BA_ "GenMsgCycleTime" BO_ 373 10;
BA_ "GenMsgCycleTime" BO_ 1424 5000;
BA_ "GenSigStartValue" SG_ 1424 VBU_BMS_BattManuMonth 1;
BA_ "GenSigStartValue" SG_ 1424 VBU_BMS_BattManuDay 1;
BA_ "GenMsgCycleTime" BO_ 1425 5000;
BA_ "GenMsgCycleTime" BO_ 1426 5000;
BA_ "GenMsgCycleTime" BO_ 1427 5000;
BA_ "GenMsgCycleTime" BO_ 1428 5000;
BA_ "GenMsgCycleTime" BO_ 1429 1000;
BA_ "GenSigStartValue" SG_ 1429 VBU_BMS_PackSOH 126;
BA_ "GenSigStartValue" SG_ 1429 VBU_BMS_PackSOE 1022;
VAL_ 374 EPS_LKA_TJA_ResponseTorqueValid 1 "Invalid" 0 "Vaild" ;
VAL_ 374 EPS_LKA_TJA_ControlStatus 3 "Permanently Failed" 2 "Temporarily Limited" 1 "Active" 0 "Inactive" ;
VAL_ 375 EPS_EPSAPASts 7 "Failure" 6 "ADAS active" 5 "NRCD active" 4 "Reply for Control" 3 "Abort" 2 "Active" 1 "Available" 0 "Inhibit" ;
VAL_ 375 EPS_EPSAPAInh 16 "EPS failure" 8 "Excess Angle Deviation" 4 "Abnormal CAN input" 2 "Driver Interference" 1 "Over Speed" 0 "Normal Operation" ;
VAL_ 529 ABS_WheelSpeed_FL 4095 "Invalid" ;
VAL_ 529 ABS_WheelSpeed_FR 4095 "Invalid" ;
VAL_ 529 ABS_WheelSpeed_RL 4095 "Invalid" ;
VAL_ 529 ABS_WheelSpeed_RR 4095 "Invalid" ;
VAL_ 529 ABS_WheelSpeed_FL_Valid 1 "Invalid" 0 "Valid" ;
VAL_ 529 ABS_WheelSpeed_FR_Valid 1 "Invalid" 0 "Valid" ;
VAL_ 529 ABS_WheelSpeed_RL_Valid 1 "Invalid" 0 "Valid" ;
VAL_ 529 ABS_WheelSpeed_RR_Valid 1 "Invalid" 0 "Valid" ;
VAL_ 580 ESP_HBA_Intervention 1 "Active" 0 "Not active" ;
VAL_ 580 ESP_AWB_Available 1 "Available" 0 "Not available" ;
VAL_ 580 ESP_AWB_Intervention 1 "Active" 0 "Not active" ;
VAL_ 580 ESP_ABA_Available 1 "Available" 0 "Not available" ;
VAL_ 580 ESP_ABA_Intervention 1 "Active" 0 "Not active" ;
VAL_ 580 ESP_ABP_Available 1 "Available" 0 "Not available" ;
VAL_ 580 ESP_ABP_Intervention 1 "Active" 0 "Not active" ;
VAL_ 580 ESP_VirtualGaspadelPosReq 1 "Request" 0 "No Request" ;
VAL_ 580 ESC_CDPIntervention 1 "Active" 0 "Not Active" ;
VAL_ 580 ESC_CDPErrorSt 1 "Available" 0 "Not available" ;
VAL_ 674 HU_APS_Audio_Active 1 "active" 0 "incative" ;
VAL_ 674 HU_Audio_AP_Request 7 "Reserved" 6 "确认泊出" 5 "遥控泊入" 4 "自动泊入" 3 "水平泊出" 2 "自选泊车" 1 "自动泊车" 0 "Default" ;
VAL_ 674 HU_Audio_Request_Command 15 "Reserved" 14 "Reserved" 13 "退出泊车" 12 "暂停" 11 "继续泊车" 10 "10" 9 "9" 8 "8" 7 "7" 6 "6" 5 "5" 4 "4" 3 "3" 2 "2" 1 "1" 0 "Default" ;
VAL_ 674 HU_APS_FunSW 3 "Reserved" 2 "on" 1 "off" 0 "no request" ;
VAL_ 674 HU_AVM_ViewModeSwitch 3 "OFF" 2 "View Mode Switch To HalfScreen" 1 "View Mode Switch To SoftKey" 0 "Default" ;
VAL_ 674 HU_Display_Mode_APA 3 "night" 2 "day" 1 "auto" 0 "default" ;
VAL_ 608 EPS_SafeLampRed 1 "open" 0 "close" ;
VAL_ 608 EPS_WarningLampYellow 1 "open" 0 "close" ;
VAL_ 608 EPS_DTCFlag 1 "DTC exist" 0 "no DTC exist" ;
VAL_ 608 EPS_DriveModeSts 3 "reserved" 2 "Sport Mode" 1 "Comfortable Mode" 0 "Normal Mode" ;
VAL_ 608 EPS_HU_DriveModeSetEn 1 "Availiable" 0 "Unavailiable" ;
VAL_ 811 VBU_WakeUpRMCU 1 "唤醒" 0 "不唤醒" ;
VAL_ 579 ESP_YawrateValue_valid 1 "invalid" 0 "valid" ;
VAL_ 579 ESP_LongAccSensorValid 1 "invalid" 0 "valid" ;
VAL_ 579 ESP_LaterAccSensorValid 1 "invalid" 0 "valid" ;
VAL_ 579 ESP_AEB_Intervention 1 "Active" 0 "Not active" ;
VAL_ 913 DSM_Horizontalforward 1 "Active" 0 "Inactive" ;
VAL_ 913 DSM_HorizontalBackward 1 "Active" 0 "Inactive" ;
VAL_ 913 DSM_Liftup 1 "Active" 0 "Inactive" ;
VAL_ 913 DSM_LiftDown 1 "Active" 0 "Inactive" ;
VAL_ 913 DSM_Backforward 1 "Active" 0 "Inactive" ;
VAL_ 913 DSM_BackBackward 1 "Active" 0 "Inactive" ;
VAL_ 913 DSM_PSMHorizontalforward 1 "Active" 0 "Inactive" ;
VAL_ 913 DSM_PSMHorizontalBackward 1 "Active" 0 "Inactive" ;
VAL_ 913 DSM_PSMBackforward 1 "Active" 0 "Inactive" ;
VAL_ 913 DSM_PSMBackBackward 1 "Active" 0 "Inactive" ;
VAL_ 913 DSM_Seat_Calibration 3 "CalibrationDoneError" 2 "CalibrationDone" 1 "StartCalibration" 0 "NotCalibration" ;
VAL_ 913 PSM_SLV_DirectionSts 3 "Invalid" 2 "Back" 1 "Forward" 0 "Stop" ;
VAL_ 913 PSM_SLV_MotorfaultSts 1 "fault" 0 "no fault" ;
VAL_ 913 PSM_LNV_DirectionSts 3 "Invalid" 2 "Back" 1 "Forward" 0 "Stop" ;
VAL_ 913 PSM_LNV_MotorfaultSts 1 "fault" 0 "no fault" ;
VAL_ 913 WakeUpSource 15 "Reserved" 14 "Reserved" 13 "Reserved" 12 "Reserved" 11 "Reserved" 10 "Reserved" 9 "Reserved" 8 "CAN(CAN唤醒中断和CAN发送、CAN状态共用一个中断)" 7 "CAN(CAN唤醒中断和CAN发送、CAN状态共用一个中断)" 6 "CAN(CAN唤醒中断和CAN发送、CAN状态共用一个中断)" 5 "CAN(CAN唤醒中断和CAN发送、CAN状态共用一个中断)" 4 "CAN(CAN唤醒中断和CAN发送、CAN状态共用一个中断)" 3 "CAN(CAN唤醒中断和CAN发送、CAN状态共用一个中断)" 2 "key(物理按键)" 1 "reserved" 0 "default" ;
VAL_ 801 CSW_Key_APA_GW 3 "Reserved" 2 "Reserved" 1 "pressed" 0 "not pressed" ;
VAL_ 801 CSW_Key_AVAS_GW 3 "Reserved" 2 "Reserved" 1 "pressed" 0 "not pressed" ;
VAL_ 801 CSW_Key_CenterLock_GW 3 "Reserved" 2 "Reserved" 1 "pressed" 0 "not pressed" ;
VAL_ 801 CSW_Key_FrontDefrost_GW 3 "Reserved" 2 "Reserved" 1 "pressed" 0 "not pressed" ;
VAL_ 801 CSW_Key_RearDefrost_GW 3 "Reserved" 2 "Reserved" 1 "pressed" 0 "not pressed" ;
VAL_ 801 CSW_Key_LiftGate_GW 3 "Reserved" 2 "Reserved" 1 "pressed" 0 "not pressed" ;
VAL_ 801 CSW_WindowLOCK_GW 3 "Reserved" 2 "default" 1 "Lock闭锁" 0 "Unlock解锁" ;
VAL_ 801 CSW_ResponseError_GW 1 "Error" 0 "No error" ;
VAL_ 801 CSW_VoltageTooLow_GW 1 "Error" 0 "No error" ;
VAL_ 801 CSW_VoltageTooHigh_GW 1 "Error" 0 "No error" ;
VAL_ 801 CSW_PWMError_GW 1 "Error" 0 "No error" ;
VAL_ 832 BCM_Hood_States 3 "Invalid" 2 "Close" 1 "Open" 0 "Default" ;
VAL_ 832 BCM_System_PowerMode 3 "Ready" 2 "ON" 1 "Reserved" 0 "OFF" ;
VAL_ 832 BCM_RKE_lock_Unlock_req 3 "Invalid" 2 "PEPS RKE UnLock Req" 1 "PEPS RKE lock Req" 0 "Default" ;
VAL_ 832 BCM_HoodSWFault 3 "Reserve" 2 "Short High or Open" 1 "Short Low" 0 "Not fault" ;
VAL_ 832 BCM_FL_DoorSts 3 "Invalid" 2 "Close" 1 "Open" 0 "Default" ;
VAL_ 832 BCM_PUSHMotorMal_controlSts 1 "Abnormal" 0 "Normal" ;
VAL_ 832 BCM_PUSH_Switc_Sts 3 "Invalid" 2 "Close" 1 "Open" 0 "Default" ;
VAL_ 64 PEPS_RKECommand 6 "window close" 5 "Window open" 4 "Trunk unlock" 3 "Door lock" 2 "Door unlock" 1 "Vehicle search" 0 "No command" ;
VAL_ 64 PEPS_TrunkReleaseReq 1 "请求" 0 "无请求" ;
VAL_ 64 PEPS_DoorUnlockReq 3 "解锁请求（四门钥匙防误锁" 2 "解锁请求（后背门钥匙防误锁）" 1 "解锁请求" 0 "无请求" ;
VAL_ 64 PEPS_DoorlockReq 3 "预留" 2 "预留" 1 "闭锁请求" 0 "无请求" ;
VAL_ 735 HU_DirverSLV_Direction_set 3 "defauit" 2 "Back" 1 "Forward" 0 "Stop" ;
VAL_ 735 HU_DirverSHV_Direction_set 3 "defauit" 2 "Down" 1 "Up" 0 "Stop" ;
VAL_ 735 HU_DirverLNV_Direction_set 3 "defauit" 2 "Back" 1 "Forward" 0 "Stop" ;
VAL_ 735 HU_PassagerSLV_Direction_set 3 "defauit" 2 "Back" 1 "Forward" 0 "Stop" ;
VAL_ 735 HU_PassagerSHV_Direction_set 3 "defauit" 2 "Down" 1 "Up" 0 "Stop" ;
VAL_ 735 HU_PassagerLNV_Direction_set 3 "defauit" 2 "Back" 1 "Forward" 0 "Stop" ;
VAL_ 735 HU_DSM_heatSwitch 3 "defauit" 2 "on" 1 "off" 0 "defauit" ;
VAL_ 735 HU_DSM_Targtemp 63 "defauit" ;
VAL_ 735 HU_PSM_heatSwitch 3 "Invalid" 2 "on" 1 "off" 0 "defauit" ;
VAL_ 735 HU_PSM_Targtemp 63 "defauit" ;
VAL_ 735 HU_DSMEasyEntrySW 3 "Invalid" 2 "on" 1 "off" 0 "defauit" ;
VAL_ 735 HU_RVMAutoFoldSW 3 "Reserved" 2 "关" 1 "开" 0 "Default" ;
VAL_ 735 HU_RVMFoldButton 3 "Reserved" 2 "展开" 1 "折叠" 0 "Default" ;
VAL_ 735 HU_RVM_R_DownSW 3 "Reserved" 2 "Enable" 1 "Disable" 0 "defauit" ;
VAL_ 735 HU_Userdefined_Mirror 7 "Reserved" 6 "Reserved" 5 "Reserved" 4 "Reserved" 3 "Reserved" 2 "后视镜退出" 1 "后视镜控制" 0 "default" ;
VAL_ 802 HU_HardACCState 1 "Hard ACC On" 0 "Hard ACC Off" ;
VAL_ 802 HU_MCUPowerState 7 "Reserved" 6 "Reserved" 5 "Reserved" 4 "Power Save Mode(Sleep)" 3 "Power Save Mode(Standby)" 2 "Silent Mode" 1 "Half Hour Mode" 0 "Normal Mode" ;
VAL_ 802 HU_SOCWatchdog 1 "SOC Watchdog Normal" 0 "SOC Watchdog Fail" ;
VAL_ 802 HU_SOCResetType 5 "SOC热启动（SOC正常休眠唤醒）" 4 "SOC冷启动（线控组合按键复位）" 3 "SOC冷启动（APP SPI下发0x5502复位）" 2 "SOC冷启动（休眠25秒超时SOC强制下电）" 1 "SOC冷启动（Keypad 3次唤不醒SOC复位）" 0 "SOC冷启动（SOC断电上电）" ;
VAL_ 802 HU_SPIConnectState 1 "SPI Connect" 0 "SPI Not Connect" ;
VAL_ 802 HU_BatteryVoltage 31 "default" ;
VAL_ 802 HU_BCMSystemPowerMode 3 "Ready" 2 "ON" 1 "Reserved" 0 "off" ;
VAL_ 792 TPCV1_Feedback_sts 3 "invalid" 2 "opening level error" 1 "reserved" 0 "no error" ;
VAL_ 792 TPCV1_Feedback_opening_sts 63 "invalid" 40 "level_100" 0 "level_0" ;
VAL_ 793 TPCV2_Feedback_sts 3 "invalid" 2 "opening level error" 1 "reserved" 0 "no error" ;
VAL_ 793 TPCV2_Feedback_opening_Sts 63 "invalid" 40 "level_100" 0 "level_0" ;
VAL_ 881 VBU_ChargeIncreaseMileageSpeed 2047 "Invalid" ;
VAL_ 881 VBU_ChargeIncreaseMileage 2047 "Invalid" ;
VAL_ 881 VBU_Maintenance_lights 1 "active" 0 "not active" ;
VAL_ 881 VBU_SlowChargeGunSt 3 "无效" 2 "插枪" 1 "未插枪" 0 "正在检测" ;
VAL_ 881 VBU_FastChargeGunSt 3 "无效" 2 "插枪" 1 "未插枪" 0 "正在检测" ;
VAL_ 881 VBU_BattTempLowCharge 1 "Active" 0 "Inactive" ;
VAL_ 881 VBU_BattEnergyLim 1 "Active" 0 "Inactive" ;
VAL_ 881 VBU_FrequentPowerupWaring 1 "Active(reserved)" 0 "Inactive" ;
VAL_ 881 VBU_NSlipBackWaring 1 "Active" 0 "Inactive" ;
VAL_ 881 VBU_CDU_Current_power 350 "Invalid" ;
VAL_ 881 VBU_CDU_MaxCurrent_power 350 "Invalid" ;
VAL_ 881 VBU_ExtremeColdMode 1 "开启" 0 "关闭" ;
VAL_ 881 VBU_BMS_Current_power 0 "Invalid" ;
VAL_ 154 VBU_ErrorLevel 7 "预留" 6 "预留" 5 "五级故障" 4 "四级故障" 3 "三级故障" 2 "二级故障" 1 "一级故障" 0 "无故障" ;
VAL_ 154 VBU_MCU_Workmode 7 "预留" 6 "EmgPark" 5 "HillHold" 4 "Discharge" 3 "Calibration mode" 2 "Speed mode" 1 "Torque mode" 0 "Disable" ;
VAL_ 154 VBU_WarmUpCycleMet 1 "WarmUpCycle met" 0 "WarmUpCycle not met" ;
VAL_ 154 VBU_MILReq 1 "MIL Lamp ON" 0 "no request" ;
VAL_ 154 VBU_MCU_TrqReq 32767 "Invalid" ;
VAL_ 154 VBU_MCU_SpdReq 65535 "Invalid" ;
VAL_ 154 VBU_MotorOffsetCalCmd 255 "条件准备完成" 254 "其他" 9 "与ESP通信故障" 8 "与MCU通信故障" 7 "模式不正确" 6 "BMS discharge power out of range" 5 "ESP not disabled" 4 "Vehicle Speed is not 0kmph（此处 车速 不能用电机 转速 计算 ）" 3 "Shift Position Not in Park or Neutral" 2 "PT Not Ready" 1 "VBU正在判断条件" 0 "无条件准备请求" ;
VAL_ 155 VBU_WPTC_En 3 "Enable" 2 "Discharge" 1 "Reserved" 0 "Disable" ;
VAL_ 155 VBU_WPTC_Request 3 "Reserved" 2 "Stop" 1 "Start" 0 "Default" ;
VAL_ 155 VBU_DCDCWorkmodeReq 7 "预留" 6 "预留" 5 "预留" 4 "预留" 3 "预留" 2 "Buck" 1 "Standby" 0 "NoRequest" ;
VAL_ 155 VBU_TBOX_ChrgLockSts 7 "预留" 6 "预留" 5 "预留" 4 "解锁超时" 3 "解锁失败" 2 "正在解锁" 1 "unlock" 0 "Default" ;
VAL_ 155 VBU_ACU_DrvSeatBeltSWSts 1 "VBU request ACU send Buckle on" 0 "default" ;
VAL_ 155 VBU_OBCWorkmodeReq 7 "预留" 6 "预留" 5 "预留" 4 "预留" 3 "Discharge" 2 "Charge" 1 "Standby" 0 "Init" ;
VAL_ 155 VBU_OBCPwrDwnReq 1 "Request" 0 "No Request" ;
VAL_ 156 VBU_Cruise_Sts 3 "fault" 2 "active" 1 "ON" 0 "off" ;
VAL_ 156 VBU_DriveInhibitAlarm 1 "Active" 0 "Inactive" ;
VAL_ 156 VBU_HU_ChrgLockSts 7 "预留" 6 "预留" 5 "预留" 4 "解锁超时" 3 "解锁失败" 2 "正在解锁" 1 "unlock" 0 "Default" ;
VAL_ 156 VBU_SpeedLimitSWSts 1 "Limit" 0 "No Limit" ;
VAL_ 156 VBU_DMS_Status 3 "非常疲劳" 2 "疲劳" 1 "清醒" 0 "OFF" ;
VAL_ 156 VBU_DMS_SWStatus 1 "ON" 0 "OFF" ;
VAL_ 156 VBU_IdleModeAct 1 "Active" 0 "No Active" ;
VAL_ 156 VBU_AuthSts 3 "认证正在进行" 2 "Auth Pass" 1 "Auth Not Pass" 0 "未认证" ;
VAL_ 156 VBU_LimitSpeedAlarm_L 1 "Active" 0 "No Active" ;
VAL_ 156 VBU_LimitSpeedAlarm_V 1 "Active" 0 "No Active" ;
VAL_ 156 VBU_TPCV1Control 63 "not used" 40 "level00" 0 "level0" ;
VAL_ 156 VBU_Cruise_Warning 3 "Reserved" 2 "陡坡缓降已开启，定速巡航激活退出" 1 "陡坡缓降已开启，无法进入定速巡航" 0 "Default" ;
VAL_ 156 VBU_TPCV2Control 63 "not used" 40 "level00" 0 "level0" ;
VAL_ 156 VBU_ElockSts 7 "状态异常故障" 6 "解锁失败" 5 "上锁失败" 4 "解锁" 3 "正在解锁" 2 "上锁" 1 "正在上锁" 0 "init" ;
VAL_ 157 VBU_AC_ComfortEAC_En 1 "Enable" 0 "Disable" ;
VAL_ 157 VBU_AC_BatCoolEAC_En 1 "Enable" 0 "Disable" ;
VAL_ 157 VBU_AC_APTC_En 1 "Enable" 0 "Disable" ;
VAL_ 157 VBU_RefuelingInfo 7 "Invalid" 6 "Reserved" 5 "Refueling completed" 4 "Please open the fuel cap" 3 "Refueling Inhibit–Please check the vehicle" 2 "Refueling Inhibit–Vehicle Condition not met" 1 "Wait for fuel lip open" 0 "No Request" ;
VAL_ 157 VBU_HU_Towmode 1 "开启" 0 "关闭" ;
VAL_ 157 VBU_HU_TowmodeSetEn 1 "允许" 0 "禁止" ;
VAL_ 157 VBU_BCM_TowModewarning 1 "开启" 0 "关闭" ;
VAL_ 157 VBU_RemoteACFeedback 15 "预留" 14 "预留" 13 "预留" 12 "预留" 11 "预留" 10 "预留" 9 "启动中" 8 "其他故障" 7 "启动太频繁" 6 "空调开启最大时间到" 5 "功率低" 4 "SOC过低" 3 "高压系统故障" 2 "本地状态" 1 "正在远程空调:" 0 "未开启" ;
VAL_ 157 VBU_ComfortPumpError 1 "故障" 0 "无故障" ;
VAL_ 157 VBU_ENGWVControl 1 "截止" 0 "打开" ;
VAL_ 157 VBU_WPTCWVControl 1 "截止" 0 "打开" ;
VAL_ 157 VBU_ENGWVFault 1 "故障" 0 "无故障" ;
VAL_ 157 VBU_WPTCWVFault 1 "故障" 0 "无故障" ;
VAL_ 157 VBU_FanSts 1 "故障" 0 "无故障" ;
VAL_ 157 VBU_RefuelingSysErrorRemind 1 "Warning" 0 "No Warning" ;
VAL_ 157 VBU_12VbatterySOHLow 1 "SOH Low" 0 "SOH Normal" ;
VAL_ 157 VBU_LVSmartChrg_Status 3 "Reserved" 2 "LVSmartChargeFalut" 1 "LVSmartCharging" 0 "NoLVSmartCharge" ;
VAL_ 157 VBU_ChargeLight 15 "预留" 14 "预留" 13 "预留" 12 "预留" 11 "充放电故障" 10 "交流降额放电中（预留）" 9 "交流降额充电中（预留）" 8 "放电中" 7 "交流枪可拔" 6 "充电结束" 5 "预约充电" 4 "充电中" 3 "正在启动充放电" 2 "充放电枪连接（预留）" 1 "交流充放电枪半连接（预留）" 0 "默认" ;
VAL_ 157 VBU_AC_ThermalReqLvl 15 "level15" 14 "level3" 13 "level3" 12 "level3" 11 "level3" 10 "level3" 9 "level3" 8 "level3" 7 "level3" 6 "level3" 5 "level3" 4 "level3" 3 "level3" 2 "level2" 1 "level1" 0 "no request" ;
VAL_ 157 VBU_VehicleModel 7 "预留" 6 "预留" 5 "预留" 4 "无效" 3 "异常" 2 "燃油" 1 "混动" 0 "纯电" ;
VAL_ 256 VBU_BMS_PackU 8191 "invalid" 8190 "init" ;
VAL_ 256 VBU_BMS_WaringLevel 7 "预留" 6 "预留" 5 "预留" 4 "预留" 3 "三级告警" 2 "二级告警" 1 "一级告警" 0 "无告警" ;
VAL_ 256 VBU_BMS_PackI 65535 "invalid" 65534 "init" ;
VAL_ 256 VBU_BMS_RelayChrPos 3 "Fault （故障)" 2 "Close（闭合）" 1 "Open （断开）" 0 "Unknow" ;
VAL_ 256 VBU_BMS_RelayNeg 3 "Fault （故障)" 2 "Close（闭合）" 1 "Open （断开）" 0 "Unknow" ;
VAL_ 256 VBU_BMS_RelayPre 3 "Fault （故障)" 2 "Close（闭合）" 1 "Open （断开）" 0 "Unknow" ;
VAL_ 256 VBU_BMS_RelayPos 3 "Fault （故障)" 2 "Close（闭合）" 1 "Open （断开）" 0 "Unknow" ;
VAL_ 256 VBU_BMS_RelayChrNeg 3 "Fault （故障)" 2 "Close（闭合）" 1 "Open （断开）" 0 "Unknow" ;
VAL_ 256 VBU_BMS_State 15 "Reserved" 14 "LV Idle" 13 "LV powerdown" 12 "HV discharge" 11 "HV down" 10 "PDUN load" 9 "SCH poweron" 8 "SCH powerup" 7 "DCH powerready" 6 "DCH poweron" 5 "DCH powerup" 4 "FCH poweron" 3 "FCH powerup" 2 "LV on" 1 "LV up" 0 "RTC" ;
VAL_ 256 VBU_BMS_ChrFastState 3 "充电故障" 2 "充电结束" 1 "充电中" 0 "未充电" ;
VAL_ 256 VBU_BMS_SPreCharging 3 "预充失败" 2 "预充完成" 1 "预充中" 0 "未预充" ;
VAL_ 256 VBU_BMS_ChrSlowState 3 "充电故障" 2 "充电结束" 1 "充电中" 0 "未充电" ;
VAL_ 258 VBU_BMS_RealSOC 1023 "Invalid" 1022 "Init" ;
VAL_ 258 VBU_BMS_PackDispSoc 1023 "Invalid" 1022 "Init" ;
VAL_ 258 VBU_BMS_ChrNegRelayEnable 1 "闭合" 0 "断开" ;
VAL_ 258 VBU_BMS_ChrPosRelayEnable 1 "闭合" 0 "断开" ;
VAL_ 258 VBU_BMS_PreRelayEnable 1 "闭合" 0 "断开" ;
VAL_ 258 VBU_BMS_CellSumVol 8191 "Invalid" 8190 "Init" ;
VAL_ 258 VBU_BMS_MainNegRelayEnable 1 "闭合" 0 "断开" ;
VAL_ 258 VBU_BMS_MainPosRelayEnable 1 "闭合" 0 "断开" ;
VAL_ 258 VBU_BMS_LinkU 8191 "Invalid" 8190 "Init" ;
VAL_ 258 VBU_BMS_BalanceSts 1 "电池开启" 0 "电池关闭" ;
VAL_ 258 VBU_APU_State 10 "EMISSION" 9 "EMS TEC" 8 "GCU CAL" 7 "run" 6 "idle" 5 "stop" 4 "start" 3 "electric" 2 "standby" 1 "Reserve2" 0 "Reserve1" ;
VAL_ 261 VBU_BMS_ChrRequest 7 "预留" 6 "预留" 5 "预留" 4 "预留" 3 "预留" 2 "预留" 1 "Request" 0 "No Request" ;
VAL_ 261 VBU_BMS_Insulation_positive 1023 "Invalid" 1021 "Max" 1022 "Init" ;
VAL_ 261 VBU_BMS_Insulation_negative 1023 "Invalid" 1021 "Max" 1022 "Init" ;
VAL_ 274 VBU_BMS_MaxCellNo 255 "Invalid" 0 "Init" ;
VAL_ 274 VBU_BMS_MaxCellU 5095 "Invalid" 5093 "Init" ;
VAL_ 274 VBU_BMS_MinCellNo 255 "Invalid" 0 "Init" ;
VAL_ 274 VBU_BMS_MinCellU 5095 "Invalid" 5093 "Init" ;
VAL_ 274 VBU_BMS_CellVolDev 4095 "Invalid" 4093 "Init" ;
VAL_ 277 VBU_BMS_MaxDschPowerPeak 0 "Invalid" ;
VAL_ 277 VBU_BMS_DschAllowedPower 0 "Invalid" ;
VAL_ 277 VBU_BMS_MaxChrgPowerPeak 0 "Invalid" ;
VAL_ 277 VBU_BMS_ChrgAllowedPower 0 "Invalid" ;
VAL_ 278 VBU_Mileage_HEV 1022 "Invalid" ;
VAL_ 278 VBU_Mileage_EV 1022 "Invalid" ;
VAL_ 278 VBU_Energyflow 15 "reserved" 14 "reserved" 13 "reserved" 12 "reserved" 11 "reserved" 10 "reserved" 9 "reserved" 8 "APU to BATT" 7 "APU&MCU to BATT" 6 "MCU to BATT&APU alive" 5 "MCU to BATT" 4 "APU to MCU&BATT" 3 "APU&BATT to MCU" 2 "APU to MCU" 1 "BATT to MCU" 0 "Default" ;
VAL_ 278 VBU_UIDisplay 7 "预留" 6 "直流放电" 5 "预约等待" 4 "交流放电" 3 "直流充电" 2 "交流充电" 1 "启动中" 0 "Default" ;
VAL_ 278 VBU_ChargStstotbox 15 "预留" 14 "预留" 13 "预留" 12 "预留" 11 "预留" 10 "预留" 9 "预留" 8 "预留" 7 "预留" 6 "充电无效" 5 "充电异常" 4 "充电完成" 3 "未充电状态" 2 "行驶充电" 1 "停车充电" 0 "init" ;
VAL_ 278 VBU_Dischargehighwarning 1 "active" 0 "not active" ;
VAL_ 278 VBU_HU_ChargeCtrl_Setsts 7 "预留" 6 "预留" 5 "停止充电" 4 "停止充电执行中" 3 "立即充电失败" 2 "立即充电" 1 "立即充电执行中" 0 "default" ;
VAL_ 278 VBU_TBOX_ChargeCtrl_Setsts 7 "预留" 6 "预留" 5 "停止充电" 4 "停止充电执行中" 3 "立即充电失败" 2 "立即充电" 1 "立即充电执行中" 0 "default" ;
VAL_ 278 VBU_TBOX_SOCExtremelylow 1 "ON" 0 "OFF" ;
VAL_ 278 VBU_TimeChargelight 1 "active" 0 "not active" ;
VAL_ 278 VBU_HU_V2XFeedbackAlarm 15 "预留" 14 "预留" 13 "预留" 12 "已停止放电" 11 "枪未插" 10 "高压系统故障" 9 "停止放电执行中" 8 "正在放电" 7 "其他故障" 6 "放电设备不满足放电条件" 5 "SOC低于设置值" 4 "放电启动太频繁" 3 "电池放电功率不足" 2 "等待插枪" 1 "立即放电启动中" 0 "Default" ;
VAL_ 278 VBU_APUDrivingState 1 "valid" 0 "invalid" ;
VAL_ 278 VBU_AcSysFultSts 7 "reserved" 6 "reserved" 5 "reserved" 4 "reserved" 3 "reserved" 2 "未知原因导致慢充故障" 1 "车辆问题导致慢充故障" 0 "默认" ;
VAL_ 278 VBU_BMS_DCSysFultSts 7 "reserved" 6 "reserved" 5 "reserved" 4 "reserved" 3 "未知原因导致快充故障" 2 "桩端问题导致快充故障" 1 "车辆问题导致快充故障" 0 "默认" ;
VAL_ 278 VBU_GearAntiTheftWarning 1 "active" 0 "inactive" ;
VAL_ 276 VBU_BMS_PACK_PressureValue 127 "Invalid" ;
VAL_ 276 VBU_ChargeButtonEN 1 "active" 0 "inactive" ;
VAL_ 276 VBU_ChargeButton 1 "停止充电" 0 "立即充电" ;
VAL_ 276 VBU_V2XWorkOrderEN 1 "active" 0 "inactive" ;
VAL_ 276 VBU_V2XWorkOrder 1 "开" 0 "关" ;
VAL_ 276 VBU_DischargeDepthFeedBack 127 "default" ;
VAL_ 276 VBU_DischargetimeWaring 1 "active" 0 "inactive" ;
VAL_ 276 VBU_BMS_InputWaterTemp 255 "Invalid" 252 "Init" ;
VAL_ 276 VBU_BMS_OutputWaterTemp 255 "Invalid" 252 "Init" ;
VAL_ 279 VBU_ActualPowerPer 255 "invalid" ;
VAL_ 279 VBU_thermalControlReq 7 "Reserved" 6 "Reserved" 5 "Reserved" 4 "Reserved" 3 "请求均温" 2 "请求冷却" 1 "请求加热" 0 "无请求" ;
VAL_ 279 VBU_PowerSwitchON_HEV 1 "active" 0 "inactive" ;
VAL_ 279 VBU_StartEngineReminder_HEV 1 "active" 0 "inactive" ;
VAL_ 279 VBU_ExitDschReminder_HEV 1 "active" 0 "inactive" ;
VAL_ 279 VBU_RestMode_Sts 7 "预留" 6 "预留" 5 "其他" 4 "休息模式下发动机启动" 3 "发动机禁止停机" 2 "前舱盖打开" 1 "已进入休息模式" 0 "休息模式关闭" ;
VAL_ 279 VBU_EnergyRegLimPer 127 "invalid" ;
VAL_ 279 VBU_SOCLow_ENGStart 127 "Invalid" 0 "Init" ;
VAL_ 279 VBU_ExchangerInputWaterTemp 255 "invalid" ;
VAL_ 279 VBU_ExitDschReminder_EV 1 "active" 0 "inactive" ;
VAL_ 279 VBU_SOCLowDisACRemind 1 "ON" 0 "OFF" ;
VAL_ 279 VBU_EnergyDriveLimPer 127 "invalid" ;
VAL_ 1441 ICM_DST_EV 4095 "Invalid" ;
VAL_ 1441 ICM_SigPowerConsumption 511 "Invalid" ;
VAL_ 1441 ICM_SigMileagetime_EV 32767 "Invalid" ;
VAL_ 1441 ICM_ODOTotal_EV 16777215 "Invalid" ;
VAL_ 1442 ICM_DST_EREV 4095 "Invalid" ;
VAL_ 1442 ICM_Sigfueleconomy 511 "Invalid" ;
VAL_ 1442 ICM_SigMileagetime_EREV 32767 "Invalid" ;
VAL_ 1442 ICM_ODOTotal_EREV 16777215 "Invalid" ;
VAL_ 1443 ICM_trip_EV 4095 "Invalid" ;
VAL_ 1443 ICM_trip_EREV 4095 "Invalid" ;
VAL_ 1443 ICM_tripPowerConsumption 511 "Invalid" ;
VAL_ 1443 ICM_tripfueleconomy 511 "Invalid" ;
VAL_ 1444 ICM_TotalAverfueleconomy 511 "Invalid" ;
VAL_ 1444 ICM_TotalAverEnergy 511 "Invalid" ;
VAL_ 1444 ICM_TotalTime_ALL 1048575 "Invalid" ;
VAL_ 1445 ICM_triptime_EV 1023 "Invalid" ;
VAL_ 1445 ICM_triptime_EREV 1023 "Invalid" ;
VAL_ 1445 ICM_TotalTime_EREV 1048575 "Invalid" ;
VAL_ 1445 ICM_TotalTime_EV 1048575 "Invalid" ;
VAL_ 320 VBU_CurrentMotorTorq 32767 "Invalid" ;
VAL_ 320 VBU_MaxMotorTorque 32767 "Invalid" ;
VAL_ 320 VBU_MiNMotorTorque 32767 "Invalid" ;
VAL_ 321 VBU_DriverDemandTorq 32767 "Invalid" ;
VAL_ 321 VBU_OnepedalSetEn 1 "允许" 0 "禁止" ;
VAL_ 321 VBU_QECACC 7 "Reserved5" 6 "Reserved4" 5 "Reserved3" 4 "Reserved2" 3 "Reserved1" 2 "Power system failure" 1 "communication failure" 0 "no error" ;
VAL_ 321 VBU_EnergyMode 7 "Reserved" 6 "Reserved" 5 "Reserved" 4 "Reserved" 3 "HybridMode" 2 "Auto" 1 "Fuel priority" 0 "EV priority" ;
VAL_ 321 VBU_GearShiftInProgress 1 "Gear is shifting" 0 "Gear not shifting" ;
VAL_ 321 VBU_ShiftInProgress_Status 1 "Invalid" 0 "Valid" ;
VAL_ 321 VBU_AcceleratioNModePer 127 "Invalid" ;
VAL_ 321 VBU_OverRide 1 "driver override" 0 "no override." ;
VAL_ 321 VBU_DriveMode 7 "Reserved" 6 "Reserved" 5 "Reserved" 4 "E-pedal" 3 "Individual Mode" 2 "Sport" 1 "ECO" 0 "comfort" ;
VAL_ 321 VBU_APS_LC_Availability 3 "保留" 2 "LongCtrl_AutomaticPark" 1 "LongCtrl_ParkEmergencyBrake" 0 "No_LongCtrl_Support" ;
VAL_ 321 VBU_APS_LC_FailureSts 7 "ParkAssist_WithError" 6 "ParkAssist_Reserved" 5 "ParkAssist_Unexpected_GearIntervention" 4 "ParkAssist_Unexpected_Brake" 3 "ParkAssist_Unexpected_EPB_Action" 2 "ParkAssist_Unexpected_GearPosition" 1 "ParkAssist_Vehicle_block" 0 "ParkAssist_NoError" ;
VAL_ 321 VBU_E_Pedalwarn 1 "active" 0 "no active" ;
VAL_ 321 VBU_KeepSOC 127 "Invalid" ;
VAL_ 321 VBU_APS_LC_Status 10 "LongCtrl_Error" 9 "LongCtrl_Active_ManeuverAccelerationAvoidance" 8 "LongCtrl_Active_ManeuverComfortBrake" 7 "LongCtrl_Active_ManeuverEmergencyBrake" 6 "LongCtrl_Active_RemoteParkOut" 5 "LongCtrl_Active_RemoteParkIn" 4 "LongCtrl_Active_AutomaticPark" 3 "LongCtrl_Active_ParkEmergencyBrake" 2 "LongCtrl_Active_ParkComfortBrake" 1 "LongCtrl_Standby" 0 "LongCtrl_Off" ;
VAL_ 322 VBU_vacuumpumpsensorRelvalue 1023 "Invalid" ;
VAL_ 322 VBU_MCU_MotorSpeed 65535 "Failure" 65534 "Init" ;
VAL_ 322 VBU_EPB_FunctionSet 3 "Reserved" 2 "拉起" 1 "释放" 0 "Default" ;
VAL_ 336 VBU_GearLeverPos 7 "Invalid" 6 "Reserved" 5 "Reserved" 4 "Reserved" 3 "D" 2 "N" 1 "R" 0 "P" ;
VAL_ 336 VBU_TortoiseLamp 1 "on" 0 "off" ;
VAL_ 336 VBU_Elockfail 3 "电子锁状态异常" 2 "上锁失败" 1 "解锁失败" 0 "default" ;
VAL_ 336 VBU_12VbatteryError 1 "Fault" 0 "No Fault" ;
VAL_ 336 VBU_ReadySts 1 "Ready" 0 "Not Ready" ;
VAL_ 336 VBU_MotorPumpError 1 "水泵故障" 0 "水泵无故障" ;
VAL_ 336 VBU_VacuumSysFaultLamp 1 "on" 0 "off" ;
VAL_ 336 VBU_GearP_EnterWarning 1 "on" 0 "off" ;
VAL_ 336 VBU_VehicleSysFaultLamp 1 "Fault" 0 "No Fault" ;
VAL_ 336 VBU_BattPumpError 1 "水泵故障" 0 "水泵无故障" ;
VAL_ 336 VBU_DriveableAlarm 1 "Active" 0 "NotActive" ;
VAL_ 336 VBU_GearFlashReq 3 "Reserved" 2 "request from EPB" 1 "request from SCM" 0 "No request" ;
VAL_ 336 VBU_ShowCarMod 1 "Active" 0 "Inactive" ;
VAL_ 336 VBU_Mileage 1023 "Invalid" ;
VAL_ 336 VBU_BMS_ISOWaringLamp 1 "Fault" 0 "No Fault" ;
VAL_ 336 VBU_BMS_BatteryErrorLamp 1 "Fault" 0 "No Fault" ;
VAL_ 336 VBU_ChargeDepthwarn 1 "active" 0 "no active" ;
VAL_ 336 VBU_ChargeDepthSts 3 "预留" 2 "预留" 1 "长途旅行" 0 "日常行驶" ;
VAL_ 336 VBU_CloolantHighAlarm 1 "Alarm" 0 "Not Alarm" ;
VAL_ 336 VBU_MotorLoopCoolantLow 1 "Fault" 0 "No Fault" ;
VAL_ 336 VBU_BatLoopCoolantLow 1 "Fault" 0 "No Fault" ;
VAL_ 336 VBU_PassengerCoolantLow 1 "Fault" 0 "No Fault" ;
VAL_ 336 VBU_BMS_SOClowLamp 1 "Fault" 0 "No Fault" ;
VAL_ 336 VBU_BMS_MaintenanceLamp 1 "Fault" 0 "No Fault" ;
VAL_ 336 VBU_BAT_thermalControlSts 3 "预留" 2 "制冷" 1 "加热" 0 "default" ;
VAL_ 336 VBU_BMS_ThermRunAway 1 "热失控" 0 "正常" ;
VAL_ 336 VBU_ESCLConfig 1 "Active" 0 "Inactive" ;
VAL_ 337 VBU_HVLock_ALL 3 "预留" 2 "高压断开" 1 "高压闭合" 0 "未检测" ;
VAL_ 337 VBU_BrakeLampReq 1 "on" 0 "off" ;
VAL_ 337 VBU_Intelligent_Charge_Sts 1 "开启" 0 "关闭" ;
VAL_ 337 VBU_HVLock1 3 "预留" 2 "高压断开" 1 "高压闭合" 0 "未检测" ;
VAL_ 337 VBU_UnlockFuelLid 1 "Requestunlock" 0 "Default" ;
VAL_ 337 VBU_BrkSw_Sts 3 "Invalid" 2 "Reserved" 1 "Pressed" 0 "NotPressed" ;
VAL_ 337 VBU_AccelPedalMalSts 3 "Reserved" 2 "Failed" 1 "Either of AVM signals is failure or check error" 0 "Normal" ;
VAL_ 337 VBU_BrkPed_Pos 255 "Invalid" ;
VAL_ 337 VBU_AccSW_Sts 3 "Invalid" 2 "reserved" 1 "pressed" 0 "not pressed" ;
VAL_ 337 VBU_AtmosphePressValue 63 "Invalid" ;
VAL_ 337 VBU_AccPedPos 255 "Invalid" ;
VAL_ 337 VBU_TargetGear 7 "Invalid" 6 "Reserved" 5 "Reserved" 4 "Reserved" 3 "D" 2 "N" 1 "R" 0 "P" ;
VAL_ 337 VBU_APS_WorkStatus 22 "预留故障1" 21 "AVM通讯故障" 20 "动力系统故障" 19 "人为介入停止" 18 "EPB释放超时" 17 "EPB故障" 16 "MCU反馈转速模式超时" 15 "分配给电机的功率不满足" 14 "车速不满足" 13 "MCU工作状态不满足" 12 "整车电源档位不满足" 11 "不在P档" 10 "VBU检测坡度不满足" 7 "正在脱手（由AVM发起）" 6 "已激活状态暂停" 5 "已激活状态后退" 4 "已激活状态前进" 3 "已激活状态停止" 2 "正在握手" 1 "Standby待机状态" 0 "Init" ;
VAL_ 337 VBU_HVLock2 3 "预留" 2 "高压断开" 1 "高压闭合" 0 "未检测" ;
VAL_ 337 VBU_HVLock3 3 "预留" 2 "高压断开" 1 "高压闭合" 0 "未检测" ;
VAL_ 734 HU_SubMileage_Reset 1 "Reset" 0 "default" ;
VAL_ 734 HU_EPB_FunctionSet 3 "Reserved" 2 "拉起" 1 "释放" 0 "Default" ;
VAL_ 734 HU_VBU_Towmode 3 "reserved" 2 "关闭" 1 "开启" 0 "default" ;
VAL_ 734 HU_ShowCarMode_Req 3 "Reserved" 2 "Inactive" 1 "Active" 0 "Default" ;
VAL_ 734 HU_EnergyRecoveryPer 127 "default" ;
VAL_ 734 HU_SpeedLimitSW 3 "reserved" 2 "Limit" 1 "No Limit" 0 "default" ;
VAL_ 734 HU_LimitSpeedSet 255 "default" ;
VAL_ 734 HU_EnergyMode 7 "Reserved" 6 "Reserved" 5 "Reserved" 4 "HybridMode" 3 "Auto" 2 "Fuel priority" 1 "EV priority" 0 "default" ;
VAL_ 734 HU_RestSwitch_Set 3 "Reserved" 2 "Off" 1 "On" 0 "Default" ;
VAL_ 734 HU_DriveMode 7 "预留" 6 "预留" 5 "E-pedal" 4 "Individual" 3 "Sport" 2 "ECO" 1 "comfort" 0 "default" ;
VAL_ 734 HU_AccelerationModePer 127 "default" ;
VAL_ 734 HU_KeepSOC 127 "Invalid" ;
VAL_ 734 HU_DMS_SW 3 "reserved" 2 "开启" 1 "关闭" 0 "default" ;
VAL_ 1451 VBU_BMS_FastChargeInfoU 8191 "Invalid" 8190 "Init" ;
VAL_ 1451 VBU_BMS_FastChargeSOE 1023 "Invalid" 1022 "Init" ;
VAL_ 1451 VBU_BMS_FastChargeInfoI 65535 "Invalid" 65534 "Init" ;
VAL_ 1451 VBU_Dischargetime 511 "Invalid" ;
VAL_ 1451 VBU_Discharge_energy 1023 "Invalid" ;
VAL_ 1452 VBU_ChrFast_Current_power 1000 "Invalid" ;
VAL_ 1452 VBU_ChrFast_MaxCurrent_power 1000 "Invalid" ;
VAL_ 1450 BST_ReachSOCsetting 1 "达到SOC设定值" 0 "未达到SOC设定值" ;
VAL_ 1450 BST_ReachBattVolset 1 "达到设定电压值" 0 "未达到设定电压值" ;
VAL_ 1450 BST_ReachCellVolset 1 "达到设定单体电压" 0 "未达到设定单体电压" ;
VAL_ 1450 BST_ISOFault 1 "绝缘故障" 0 "绝缘正常" ;
VAL_ 1450 BST_VBU_BMS_PCBOverTemp 1 "元器件过温" 0 "温度正常" ;
VAL_ 1450 BST_ChargeOverCurr 1 "充电电流过大" 0 "充电电流正常" ;
VAL_ 1450 BST_FastChaVolUnusual 1 "电压异常" 0 "电压正常" ;
VAL_ 1450 BST_FastChargerSTOP 1 "充电桩主动停止（收到CST报文）" 0 "正常" ;
VAL_ 1450 CST_ReachChargerSet 3 "reserved" 2 "不可信" 1 "达到充电机设定条件" 0 "正常" ;
VAL_ 1450 CST_ManualStop 3 "reserved" 2 "不可信" 1 "人工停止" 0 "正常" ;
VAL_ 1450 CST_FaultStop 3 "reserved" 2 "不可信" 1 "故障停止" 0 "正常" ;
VAL_ 1450 CST_BMSStop 3 "reserved" 2 "不可信" 1 "BMS主动停止" 0 "正常" ;
VAL_ 1450 CST_FastCharOverTemp 3 "reserved" 2 "不可信" 1 "充电桩过温" 0 "温度正常" ;
VAL_ 1450 CST_CharContorFault 3 "reserved" 2 "不可信" 1 "连接器故障" 0 "正常" ;
VAL_ 1450 CST_FastChaInOvTemp 3 "reserved" 2 "不可信" 1 "内部过温" 0 "内部温度正常" ;
VAL_ 1450 CST_EngNotTransfer 3 "reserved" 2 "不可信" 1 "电量不能传送" 0 "正常" ;
VAL_ 1450 CST_FastChaUrgentStop 3 "reserved" 2 "不可信" 1 "充电桩急停" 0 "正常" ;
VAL_ 1450 CST_OtherFault 2 "不可信" 1 "其他故障" 0 "正常" ;
VAL_ 1450 CST_CurrentMismatch 3 "reserved" 2 "不可信" 1 "电流不匹配" 0 "正常" ;
VAL_ 1450 CST_VoltageUnusual 3 "reserved" 2 "不可信" 1 "电压异常" 0 "正常" ;
VAL_ 1450 BEM_CRM_00_OverTim 1 "超时" 0 "正常" ;
VAL_ 1450 BEM_CRM_AA_OverTim 1 "超时" 0 "正常" ;
VAL_ 1450 BEM_CTSCML_OverTim 1 "超时" 0 "正常" ;
VAL_ 1450 BEM_CRO_OverTim 1 "超时" 0 "正常" ;
VAL_ 1450 BEM_CCS_OverTim 1 "超时" 0 "正常" ;
VAL_ 1450 BEM_CST_OverTim 1 "超时" 0 "正常" ;
VAL_ 1450 BEM_CSD_OverTim 1 "超时" 0 "正常" ;
VAL_ 1450 CEM_BRM_OverTim 1 "超时" 0 "正常" ;
VAL_ 1450 CEM_BCP_OverTim 1 "超时" 0 "正常" ;
VAL_ 1450 CEM_BRO_OverTim 1 "超时" 0 "正常" ;
VAL_ 1450 CEM_BCS_OverTim 1 "超时" 0 "正常" ;
VAL_ 1450 CEM_BCL_OverTim 1 "超时" 0 "正常" ;
VAL_ 1450 CEM_BST_OverTim 1 "超时" 0 "正常" ;
VAL_ 1450 CEM_BSD_OverTim 1 "超时" 0 "正常" ;
VAL_ 1450 VBU_BMS_ChargeSOPbuffer 255 "Invalid" ;
VAL_ 1324 VBU_CrashStatus 1 "crash" 0 "no crash" ;
VAL_ 977 CDU_TempWater 255 "Invalid" ;
VAL_ 977 CDU_PFC_TempAct 255 "Invalid" 254 "default" ;
VAL_ 977 CDU_DC_TempAct 255 "Invalid" 254 "default" ;
VAL_ 977 CDU_Inside_Air_TempAct 255 "Invalid" 254 "default" ;
VAL_ 977 CDU_WakeupSrc 7 "预留" 6 "预留" 5 "预留" 4 "CC" 3 "CP" 2 "VBU EN" 1 "CAN" 0 "Invalid" ;
VAL_ 977 CDU_AC_FreqSts 1 "Valid" 0 "Invalid" ;
VAL_ 977 CDU_OBC_PlugCon_ErrSts 1 "valid" 0 "Invalid" ;
VAL_ 977 CDU_OBC_EVSE_ErrSts 1 "valid" 0 "Invalid" ;
VAL_ 977 CDU_LLC_TempAct 255 "Invalid" 254 "default" ;
VAL_ 978 CDU_OBC_DeratingSts 1 "Derating" 0 "No derating" ;
VAL_ 978 CDU_OBC_CCCap 7 "预留" 6 "预留" 5 "预留" 4 "64A" 3 "32A" 2 "16A" 1 "10A" 0 "Invalid" ;
VAL_ 978 CDU_OBC_ACHVILSts 3 "Invalid" 2 "Normal" 1 "Fault" 0 "Init" ;
VAL_ 978 CDU_OBC_ACVolt 511 "Invalid" 510 "default" ;
VAL_ 978 CDU_OBC_ACCUrr 511 "Invalid" 510 "default" ;
VAL_ 978 CDU_OBC_S2Sts 1 "On" 0 "Off" ;
VAL_ 978 CDU_OBC_DischCPSts 1 "valid" 0 "Invalid" ;
VAL_ 592 CDU_OBC_ChrgFailLevel 7 "预留" 6 "预留" 5 "预留" 4 "预留" 3 "三级故障" 2 "二级故障" 1 "一级故障" 0 "无故障" ;
VAL_ 592 CDU_OBC_WorkMode 7 "Failure" 6 "Discharge Overload" 5 "V2V Discharging" 4 "V2L Discharging" 3 "Charging" 2 "Connect" 1 "Disconnect" 0 "Init" ;
VAL_ 592 CDU_OBC_CPFreqSts 1 "Valid" 0 "Invalid" ;
VAL_ 592 CDU_OBC_ChgCPSts 1 "Valid" 0 "Invalid" ;
VAL_ 592 CDU_OBC_CCSts 7 "Reserved" 6 "Reserved" 5 "CC接地" 4 "Connect(V2L)" 3 "Rerved" 2 "Connect(Charge/V2V)" 1 "Half Connect" 0 "Disconnect" ;
VAL_ 592 CDU_OBC_MILReq 1 "MIL Lamp ON" 0 "no request" ;
VAL_ 392 CDU_DC_ErrorLevel 7 "Reserved" 6 "Reserved" 5 "Reserved" 4 "Reserved" 3 "三级故障" 2 "二级故障" 1 "一级故障" 0 "无故障" ;
VAL_ 392 CDU_DC_WorkMode 7 "Failure" 6 "Reserved" 5 "Reserved" 4 "Reserved" 3 "Buck" 2 "Connect" 1 "Disconnect" 0 "Init" ;
VAL_ 392 CDU_DC_HVHVILSts 3 "Invalid" 2 "Normal" 1 "Fault" 0 "Init" ;
VAL_ 392 CDU_DC_DeratingSts 1 "derating" 0 "normal" ;
VAL_ 392 CDU_DC_Tbox_WorkSts 3 "无效" 2 "异常" 1 "工作" 0 "断开" ;
VAL_ 392 CDU_DC_Tbox_TempFault 1 "Fault" 0 "Not Fault" ;
VAL_ 1552 CDU_OBC_ACHVIL_Fault 1 "Fault" 0 "Not Fault" ;
VAL_ 1552 CDU_OBC_Input_Overvolt_SW 1 "Fault" 0 "Not Fault" ;
VAL_ 1552 CDU_OBC_Input_Undervolt_SW 1 "Fault" 0 "Not Fault" ;
VAL_ 1552 CDU_OBC_HW_InputCurHig_lv2 1 "Fault" 0 "Not Fault" ;
VAL_ 1552 CDU_OBC_HW_InputCurHig_lv3 1 "Fault" 0 "Not Fault" ;
VAL_ 1552 CDU_OBC_AC_AbnormFreq 1 "Fault" 0 "Not Fault" ;
VAL_ 1552 CDU_OBC_Output_Overvolt 1 "Fault" 0 "Not Fault" ;
VAL_ 1552 CDU_OBC_Output_Undervolt_HW 1 "Fault" 0 "Not Fault" ;
VAL_ 1552 CDU_OBC_HW_OutputCurHig_lv2 1 "Fault" 0 "Not Fault" ;
VAL_ 1552 CDU_OBC_HW_OutputCurHig_lv3 1 "Fault" 0 "Not Fault" ;
VAL_ 1552 CDU_OBC_SW_OutputCurHig_lv2 1 "Fault" 0 "Not Fault" ;
VAL_ 1552 CDU_OBC_SW_OutputCurHig_lv3 1 "Fault" 0 "Not Fault" ;
VAL_ 1552 CDU_OBC_OverTemp 1 "Fault" 0 "Not Fault" ;
VAL_ 1552 CDU_OBC_Input_Underpower 1 "Fault" 0 "Not Fault" ;
VAL_ 1552 CDU_OBC_Input_Overpower 1 "Fault" 0 "Not Fault" ;
VAL_ 1552 CDU_OBC_Output_Underpower 1 "Fault" 0 "Not Fault" ;
VAL_ 1552 CDU_OBC_HigTemp 1 "Fault" 0 "Not Fault" ;
VAL_ 1552 CDU_OBC_Start_Failure 1 "Fault" 0 "Not Fault" ;
VAL_ 1552 CDU_OBC_Prechrg_Fault 1 "Fault" 0 "Not Fault" ;
VAL_ 1552 CDU_OBC_OutputShortCirc 1 "Fault" 0 "Not Fault" ;
VAL_ 1552 CDU_OBC_PFC_Start_Failure 1 "Fault" 0 "Not Fault" ;
VAL_ 1552 CDU_OBC_PFC_Busvolt_Hig 1 "Fault" 0 "Not Fault" ;
VAL_ 1552 CDU_OBC_PFC_Busvolt_Low_lv2 1 "Fault" 0 "Not Fault" ;
VAL_ 1552 CDU_OBC_PFC_Busvolt_Low_lv3 1 "Fault" 0 "Not Fault" ;
VAL_ 1552 CDU_OBC_Dischr_ACvolt_Hig 1 "Fault" 0 "Not Fault" ;
VAL_ 1552 CDU_OBC_Dischr_ACvolt_Low 1 "Fault" 0 "Not Fault" ;
VAL_ 1552 CDU_OBC_SW_Dischr_ACCur_Hig 1 "Fault" 0 "Not Fault" ;
VAL_ 1552 CDU_OBC_HW_Dischr_ACCur_Hig 1 "Fault" 0 "Not Fault" ;
VAL_ 1552 CDU_OBC_Dischr_AC_AbnormFreq 1 "Fault" 0 "Not Fault" ;
VAL_ 1552 CDU_OBC_SW_Dischr_Overvolt 1 "Fault" 0 "Not Fault" ;
VAL_ 1552 CDU_OBC_Dischr_AC_Overvolt 1 "Fault" 0 "Not Fault" ;
VAL_ 1552 CDU_OBC_HW_Dischr_CurHig 1 "Fault" 0 "Not Fault" ;
VAL_ 1552 CDU_OBC_SW_Dischr_CurHig 1 "Fault" 0 "Not Fault" ;
VAL_ 1552 CDU_OBC_Dischr_ShotCirc 1 "Fault" 0 "Not Fault" ;
VAL_ 1552 Abnormal_Insulation_Resistance 1 "Fault" 0 "Not Fault" ;
VAL_ 1553 CDU_DCDC_OutputVolHig_lv2 1 "Fault" 0 "Not Fault" ;
VAL_ 1553 CDU_DCDC_OutputVolHig_lv3 1 "Fault" 0 "Not Fault" ;
VAL_ 1553 CDU_DCDC_OutputVolLow_lv2 1 "Fault" 0 "Not Fault" ;
VAL_ 1553 CDU_DCDC_OutputVolLow_lv3 1 "Fault" 0 "Not Fault" ;
VAL_ 1553 CDU_DCDC_OutputOpen 1 "Fault" 0 "Not Fault" ;
VAL_ 1553 CDU_DCDC_HW_OutputCurHig_lv2 1 "Fault" 0 "Not Fault" ;
VAL_ 1553 CDU_DCDC_HW_OutputCurHig_lv3 1 "Fault" 0 "Not Fault" ;
VAL_ 1553 CDU_DCDC_SW_OutputCurHig_lv2 1 "Fault" 0 "Not Fault" ;
VAL_ 1553 CDU_DCDC_SW_OutputCurHig_lv3 1 "Fault" 0 "Not Fault" ;
VAL_ 1553 CDU_DCDC_OutputShotCirc_lv2 1 "Fault" 0 "Not Fault" ;
VAL_ 1553 CDU_DCDC_OutputShotCirc_lv3 1 "Fault" 0 "Not Fault" ;
VAL_ 1553 KL30_Input_Overvolt 1 "Fault" 0 "Not Fault" ;
VAL_ 1553 KL30_Input_Undervolt 1 "Fault" 0 "Not Fault" ;
VAL_ 1553 CDU_DCDC_TempSensorFault 1 "Fault" 0 "Not Fault" ;
VAL_ 1553 CDU_DCDC_InputVolHig 1 "Fault" 0 "Not Fault" ;
VAL_ 1553 CDU_DCDC_InputVolLow 1 "Fault" 0 "Not Fault" ;
VAL_ 1553 CDU_DCDC_start_Failure 1 "Fault" 0 "Not Fault" ;
VAL_ 1553 CDU_DCDC_SW_InputVolHig 1 "Fault" 0 "Not Fault" ;
VAL_ 1553 CDU_DCDC_SW_InputVolLow 1 "Fault" 0 "Not Fault" ;
VAL_ 1553 CDU_DCDC_OverTemp 1 "Fault" 0 "Not Fault" ;
VAL_ 1553 CDU_DC_SCI_Com_Failure 1 "Fault" 0 "Not Fault" ;
VAL_ 1553 CDU_DCDC_MCUChecksum_Failure 1 "Fault" 0 "Not Fault" ;
VAL_ 1553 CDU_DCDC_InnerTempHig 1 "Fault" 0 "Not Fault" ;
VAL_ 1553 CDU_DCDC_Shutdown_For_LowTemp 1 "Fault" 0 "Not Fault" ;
VAL_ 1553 CDU_Busoff 1 "Fault" 0 "Not Fault" ;
VAL_ 1553 CDU_Lost_Communication 1 "Fault" 0 "Not Fault" ;
VAL_ 1553 CDU_DCDC_HVHVIL_Fault 1 "Fault" 0 "Not Fault" ;
VAL_ 538 GCU_IverterTempWarning 1 "warning" 0 "no warning" ;
VAL_ 538 GCU_MotorTempWarning 1 "warning" 0 "no warning" ;
VAL_ 538 GCU_work_mode 8 "fault 故障保护" 7 "LV_Power_down 下弱电（高压低于36v)" 6 "Shut down 下强电（主动放电）" 5 "Toque control 扭矩闭环运行" 4 "Speed control 转速闭环运行" 3 "Idle 发电机允许运行" 2 "OffsetCal 角标模式" 1 "LV_Power_up 低压上电正常" 0 "init 初始化" ;
VAL_ 538 GCU_Fail_Grade 4 "Fault (shut down GCU)" 3 "Fault (zero torque output)" 2 "Warning (degraded)" 1 "low (没有该级就不发）" 0 "No Fault" ;
VAL_ 538 GCU_MILReq 1 "MIL Lamp ON" 0 "no request" ;
VAL_ 539 GCU_DC_Current 4095 "Invalid" ;
VAL_ 539 GCU_DC_Voltage 2047 "Invalid" ;
VAL_ 626 EMS_PSNotActiveTimeAccu 65535 "Invalid" ;
VAL_ 626 EMS_EngineSpeed 8191 "Invalid" ;
VAL_ 626 EMS_EngineStatus 7 "Power Off Delay" 6 "Stopped" 5 "Stopping" 4 "Stall" 3 "Running" 2 "Crank" 1 "Key On" 0 "Power Off" ;
VAL_ 626 EMS_DesireIdleSpeed 8191 "Invalid" ;
VAL_ 627 EMS_MilLampRequest 3 "Reserved" 2 "Request MIL Flash" 1 "Request MIL On" 0 "No Request" ;
VAL_ 627 EMS_SVSLampRequest 1 "Request SVS On" 0 "No Request" ;
VAL_ 627 EMS_LowOilPressure 1 "Active" 0 "Inactive" ;
VAL_ 627 EMS_FuelLevelFaultActive 1 "Active" 0 "Inactive" ;
VAL_ 627 EMS_FuelConsumption 255 "Invalid" ;
VAL_ 627 EMS_Fuellevel 255 "Invalid" ;
VAL_ 627 EMS_EngineCoolantTemperature 255 "Invalid" ;
VAL_ 1377 VBU_IG1input 1 "active" 0 "inactive" ;
VAL_ 1377 VBU_startinput 1 "active" 0 "inactive" ;
VAL_ 1377 VBU_OBCwakeupVBU 1 "active" 0 "inactive" ;
VAL_ 1377 VBU_wakeupCDU 1 "active" 0 "inactive" ;
VAL_ 1377 VBU_VBUwakeupGCU 1 "active" 0 "inactive" ;
VAL_ 1377 VBU_VacuumPumpRelay 1 "active" 0 "inactive" ;
VAL_ 1377 VBU_WPTCRelay 1 "active" 0 "inactive" ;
VAL_ 1377 VBU_EMSRelay 1 "active" 0 "inactive" ;
VAL_ 1377 VBU_ThermRunAwaywakeup 1 "active" 0 "inactive" ;
VAL_ 546 PEPS_PEPSFailStatus 1 "Active" 0 "Inactive" ;
VAL_ 546 PEPS_WarningKeyNotInCar 1 "Active" 0 "Inactive" ;
VAL_ 546 PEPS_WarningKeyInCar 1 "Active" 0 "Inactive" ;
VAL_ 546 PEPS_WarningIgNotOff 1 "Active" 0 "Inactive" ;
VAL_ 546 PEPS_WarningKeyLowBattery 1 "Active" 0 "Inactive" ;
VAL_ 546 PEPS_WarningStartupNotBrake 1 "Active" 0 "Inactive" ;
VAL_ 546 PEPS_WarningKeyNearbyIMMO 1 "Active" 0 "Inactive" ;
VAL_ 546 PEPS_BackDoorKeyState 3 "无钥匙在后背门附近" 2 "有钥匙在后背门附近" 1 "找钥匙中" 0 "未找钥匙" ;
VAL_ 546 PEPS_KeyPosition 3 "预留" 2 "钥匙不在车内" 1 "钥匙在车内" 0 "无输入" ;
VAL_ 546 PEPS_HandshakeFail 7 "无效值" 6 "预留" 5 "预留" 4 "预留" 3 "TIMEOUT_ERR(发送超时)" 2 "握手失败NO_RES_ERR(从MCU无响应)" 1 "握手失败CRC_ERR( 发送/接收 数据格式或CRC校验不正确)" 0 "握手成功" ;
VAL_ 546 PEPS_Authpasstype 3 "FOB and tbox response OK" 2 "FOB response OK" 1 "TBOX response OK" 0 "Auth not pass" ;
VAL_ 546 PEPS_EnableWirelessCharging 1 "Enable" 0 "Disable" ;
VAL_ 546 PEPS_DHA_LeftHandleSwitch 3 "reserved" 2 "闭锁请求" 1 "解锁请求" 0 "default" ;
VAL_ 546 PEPS_PHA_RightHandleSwitch 3 "reserved" 2 "闭锁请求" 1 "解锁请求" 0 "default" ;
VAL_ 546 DHA_LockFlag 80 "代表同时解闭锁有效" 10 "代表解锁有效" 5 "代表闭锁有效" 0 "代表没有触摸" ;
VAL_ 546 PHA_LockFlag 80 "代表同时解闭锁有效" 10 "代表解锁有效" 5 "代表闭锁有效" 0 "代表没有触摸" ;
VAL_ 852 PEPS_Driver_Antenna_Error 1 "故障" 0 "无故障" ;
VAL_ 852 PEPS_Passenger_Antenna_Error 1 "故障" 0 "无故障" ;
VAL_ 852 PEPS_Trunk_Antenna_Error 1 "故障" 0 "无故障" ;
VAL_ 852 BCM_HU_DoorLocksetFB 1 "FourDoor UnLock" 0 "DiverDoor UnLock" ;
VAL_ 852 PEPS_Facia_Antenna_Error 1 "故障" 0 "无故障" ;
VAL_ 852 PEPS_Rear_Antenna_Error 1 "故障" 0 "无故障" ;
VAL_ 852 PEPS_Handrail_Antenna_Error 1 "故障" 0 "无故障" ;
VAL_ 852 PEPS_RecentlyKEYTypeCmd 8 "四门防误锁请求" 7 "后备门防误锁请求" 6 "PE解锁请求" 5 "PE闭锁请求" 4 "RF window close" 3 "RF Window open" 2 "RF Door lock" 1 "RF Door unlock" 0 "No command" ;
VAL_ 852 PEPS_KeyLessCodeNumber 5 "key less 5" 4 "key less 4" 3 "key less 3" 2 "key less 2" 1 "key less 1" 0 "no key less operation" ;
VAL_ 912 DSM_MirrorRdownSetStatus 1 "disable" 0 "enable" ;
VAL_ 912 DSM_SeatMotorSts 1 "Work" 0 "Ready" ;
VAL_ 912 DSM_MirrorSts 1 "Work" 0 "Ready" ;
VAL_ 912 DSM_LeftMirrorMotor1fault 1 "fault" 0 "no fault" ;
VAL_ 912 DSM_LeftMirrorMotor2fault 1 "fault" 0 "no fault" ;
VAL_ 912 DSM_RightMirrorMotor1fault 1 "fault" 0 "no fault" ;
VAL_ 912 DSM_RightMirrorMotor2fault 1 "fault" 0 "no fault" ;
VAL_ 912 DSM_WorkMode 7 "Reserved" 6 "后视镜调节模式" 5 "调节模式" 4 "倒车后视镜下翻" 3 "下车迎宾" 2 "上车迎宾" 1 "记忆调用" 0 "Default" ;
VAL_ 912 DSM_LM_DirectionSts_SX 3 "Invalid" 2 "Down" 1 "Up" 0 "Stop" ;
VAL_ 912 DSM_LM_DirectionSts_ZY 3 "Invalid" 2 "Right" 1 "Left" 0 "Stop" ;
VAL_ 912 DSM_RM_DirectionSts_SX 3 "Invalid" 2 "Down" 1 "Up" 0 "Stop" ;
VAL_ 912 DSM_RM_DirectionSts_ZY 3 "Invalid" 2 "Right" 1 "Left" 0 "Stop" ;
VAL_ 912 DSM_CalibrationAlarm 3 "LNV Calibration Alarm（靠背）" 2 "SHV Calibration Alarm（高度）" 1 "SLV Calibration Alarm(前后)" 0 "Default" ;
VAL_ 912 DSM_CalibrationSts 3 "学习失败" 2 "学习成功" 1 "学习中" 0 "未学习" ;
VAL_ 820 IBS_U_BATT 16383 "invalid" ;
VAL_ 820 IBS_I_Range 3 "invalid" 2 "current Range [-1500, 1500A]" 1 "current Range [-200, 200A]" 0 "current Range [-1, 1A]" ;
VAL_ 820 IBS_I_BATT 65535 "invalid" ;
VAL_ 820 IBS_T_BATT 255 "invalid" ;
VAL_ 820 IBS_IBATT_QUIESCENT 255 "invalid" 254 "Out of bounds" 253 "Overflow" ;
VAL_ 820 IBS_Status_Current 3 "LIN saturation (no HW defect)" 2 "HW defect (out of range or ADC defect)" 1 "Error Open circuit" 0 "No error" ;
VAL_ 820 IBS_Status_Voltage 3 "LIN saturation (no HW defect)" 2 "HW defect (ADC defect)" 1 "Error Open circuit" 0 "No error" ;
VAL_ 820 IBS_Status_Temp 3 "LIN saturation (no HW defect)" 2 "HW defect (ADC defect)" 1 "not used" 0 "No error" ;
VAL_ 820 IBS_ERROR_Calib 1 "Error" 0 "No error" ;
VAL_ 820 IBS_ERROR_IDENT 1 "Error" 0 "No error" ;
VAL_ 820 IBS_Resp_Error 1 "Error" 0 "No error" ;
VAL_ 820 IBS_FLAG_INCONSISTENCY 1 "battery inconsistency" 0 "no battery inconsistency" ;
VAL_ 821 IBS_SOC 255 "invalid" ;
VAL_ 821 IBS_SOH_SUL 255 "invalid" ;
VAL_ 821 IBS_SOH_LAM 255 "invalid" ;
VAL_ 821 IBS_SOH_COR 255 "invalid" ;
VAL_ 821 IBS_SOC_STATE 3 "invalid" 2 "deviation < 10%" 1 "deviation < 15%" 0 "deviation > 15%" ;
VAL_ 821 IBS_SOH_SUL_STATE 3 "invalid" 2 "not used" 1 "learned" 0 "not learned" ;
VAL_ 821 IBS_SOH_LAM_STATE 3 "invalid" 2 "undefined" 1 "learned" 0 "not learned" ;
VAL_ 821 IBS_SOH_COR_STATE 3 "invalid" 2 "accurate (deviation < 400mV)" 1 "inaccurate" 0 "not learned" ;
VAL_ 821 GW_Diagtester_inputactive 1 "active" 0 "inactive" ;
VAL_ 931 HU_AC_SystemSet 3 "Reserved" 2 "on" 1 "off" 0 "Default" ;
VAL_ 931 HU_AC_Cycle 3 "Reserved" 2 "外循环" 1 "内循环" 0 "Default" ;
VAL_ 931 HU_AC_EAC_Control 3 "Reserved" 2 "on" 1 "off" 0 "Default" ;
VAL_ 931 HU_AC_AutoMode_Set 3 "Reserved" 2 "off" 1 "on" 0 "Default" ;
VAL_ 931 HU_AC_WindMode_Set 7 "Reserved" 6 "Reserved" 5 "Fdefrost" 4 "Blow face" 3 "Blow foot&defrost" 2 "Blow foot" 1 "Blow face&foot" 0 "Default" ;
VAL_ 931 HU_AC_BlowingRate_Set 7 "Level7" 6 "Level6" 5 "Level5" 4 "Level4" 3 "Level3" 2 "Level2" 1 "Level1" 0 "Default" ;
VAL_ 931 HU_AC_APTCSW_Set 3 "Reserved" 2 "开" 1 "关" 0 "Default" ;
VAL_ 931 HU_AC_Temp_set 0 "Default" ;
VAL_ 931 HU_AC_BackLOCK_Set 3 "Reserved" 2 "开" 1 "关" 0 "Default" ;
VAL_ 931 HU_PowerManagerState 7 "Reserved" 6 "Reserved" 5 "Power Save Mode(Sleep)" 4 "Power Save Mode(Standby)" 3 "Silent Mode（can go to power save mode）" 2 "Silent Mode（cannot go to power save mode）" 1 "One Hour Mode" 0 "Normal Mode" ;
VAL_ 933 HU_LanguageSet 15 "Reserved" 8 "Reserved" 7 "Portuguese" 6 "Spanish" 5 "Italian" 4 "French" 3 "German" 2 "Russian" 1 "English" 0 "Chinese" ;
VAL_ 933 HU_TimeSet_DisplayMode 1 "24 hour" 0 "12 hour" ;
VAL_ 933 HU_TimeSet_AutoMode 1 "Manual" 0 "Automatical" ;
VAL_ 933 HU_TBOXwelcomeReq_set 3 "reserved" 2 "disable" 1 "enable" 0 "Default" ;
VAL_ 933 HU_TimeSet_Hour 30 "Reserved" 24 "Reserved" 23 "valid hour" 0 "valid hour" ;
VAL_ 933 HU_TimeSet_Minutes 60 "valid min" 0 "valid min" ;
VAL_ 933 HU_TBOX_Reboot 3 "Reserved" 2 "Reserved" 1 "reboot" 0 "Default" ;
VAL_ 933 HU_RemoteCharge_StartHour 31 "default" ;
VAL_ 933 HU_RemoteCharge_Startmin 63 "default" ;
VAL_ 933 HU_RemoteCharge_Set 3 "Reserved" 2 "开启定时充电模式" 1 "取消定时充电模式" 0 "default" ;
VAL_ 933 HU_RemotCh_Full_SetSts 3 "reserved" 2 "充满" 1 "不充满" 0 "default" ;
VAL_ 933 HU_RemoteCharge_EndHour 31 "Default" ;
VAL_ 933 HU_RemoteCharge_Endmin 63 "Default" ;
VAL_ 816 BCM_reversingLampSW 1 "on" 0 "off" ;
VAL_ 816 BCM_Rsp_HU_Daylight 1 "off状态-HU控制日间行车灯熄灭状态" 0 "Auto状态-BCM本地控制状态" ;
VAL_ 816 BCM_CarpetlampSW 1 "on" 0 "off" ;
VAL_ 816 BCM_CarpetlampSWSetsts 1 "Enable" 0 "Dsiaable" ;
VAL_ 816 BCM_HU_RLSModeSts 3 "Reserved" 2 "Error" 1 "ON" 0 "OFF" ;
VAL_ 816 BCM_FrontdecoralampSW 1 "on" 0 "off" ;
VAL_ 816 BCM_WinCloseReminder 7 "reserved" 6 "reserved" 5 "reserved" 4 "reserved" 3 "reserved" 2 "Raining close failed" 1 "Raining close success" 0 "default" ;
VAL_ 816 BCM_DomeLampDoorControl 1 "on" 0 "off" ;
VAL_ 816 BCM_LockWelcomeSts 3 "闭锁迎宾模式完成" 2 "闭锁迎宾模式中" 1 "闭锁迎宾模式开始" 0 "default" ;
VAL_ 816 BCM_PEPSLockReason 7 "reserved" 6 "reserved" 5 "reserved" 4 "reserved" 3 "reserved" 2 "RKE闭锁" 1 "PE闭锁" 0 "default" ;
VAL_ 816 BCM_PEPSUnLockReason 7 "reserved" 6 "reserved" 5 "reserved" 4 "后背门防误锁" 3 "四门防误锁" 2 "RKE解锁" 1 "PE解锁" 0 "defauit" ;
VAL_ 816 BCM_ESCLConfig 1 "Active" 0 "Inactive" ;
VAL_ 816 BCM_RLS_All_WdwClosed_Sts 3 "reserved" 2 "Invalid" 1 "Complete Close" 0 "Incomplete Close" ;
VAL_ 816 BCM_FollowMeControlsts 1 "on" 0 "off" ;
VAL_ 816 BCM_FollowMeDelayTSetsts 3 "90s" 2 "60s" 1 "30s" 0 "default" ;
VAL_ 816 BCM_RR_LED2_Error 1 "error" 0 "no error" ;
VAL_ 816 BCM_AutoLockSetsts 1 "enable" 0 "disable" ;
VAL_ 816 BCM_RL_LED2_Error 1 "error" 0 "no error" ;
VAL_ 816 BCM_WindowAutoUPSetsts 1 "enable" 0 "disable" ;
VAL_ 816 BCM_FL_LED_Error 1 "error" 0 "no error" ;
VAL_ 816 BCM_FR_LED_Error 1 "error" 0 "no error" ;
VAL_ 816 BCM_RL_LED1_Error 1 "error" 0 "no error" ;
VAL_ 816 BCM_RR_LED1_Error 1 "error" 0 "no error" ;
VAL_ 816 BCM_SSB1_inputSts 1 "active" 0 "Notactive" ;
VAL_ 816 BCM_SSB2_inputSts 1 "active" 0 "Notactive" ;
VAL_ 816 BCM_LockReason 8 "lock form HU request" 7 "lock form Tbox 4G lock request" 6 "BCM Secondary lock" 5 "lock form speed signal" 4 "lock form CSW request" 3 "lock form mechanical key" 2 "lock form PEPS lock request" 1 "lock form Tbox BT lock request" 0 "defauit" ;
VAL_ 816 BCM_UnLockReason 8 "Unlock form HU request" 7 "Unlock form AVM request" 6 "Unlock form Tbox 4G unlock request" 5 "Unlock form crash signal" 4 "Unlock form CSW request" 3 "Unlock form mechanical key" 2 "Unlock form PEPS unlock request" 1 "Unlock form Tbox BT unlock request" 0 "defauit" ;
VAL_ 816 BCM_ACU_Crash_inputsts 1 "active" 0 "Notactive" ;
VAL_ 816 BCM_ESCL_UnlockFB_inputsts 1 "active" 0 "Notactive" ;
VAL_ 816 BCM_ESCL_Motorpower_outputsts 1 "active" 0 "Notactive" ;
VAL_ 816 BCM_ESCL_LockEnable_outputsts 1 "active" 0 "Notactive" ;
VAL_ 816 BCM_ESCL_UnLockfail 1 "fail" 0 "no  fail" ;
VAL_ 816 BCM_ESCL_Lockfail 1 "fail" 0 "no  fail" ;
VAL_ 816 BCM_waterlightlimit 1 "limit" 0 "nolimit" ;
VAL_ 961 Tbox_ICM_ODOTotal 16777215 "Invalid" ;
VAL_ 961 Tbox_ICM_Prevmaintmileage 16777215 "Invalid" ;
VAL_ 1281 TPMS_FL_Pressure_value 255 "Invalid" ;
VAL_ 1281 TPMS_FR_Pressure_value 255 "Invalid" ;
VAL_ 1281 TPMS_RL_Pressure_value 255 "Invalid" ;
VAL_ 1281 TPMS_RR_Pressure_value 255 "Invalid" ;
VAL_ 642 SCM_LKS_Switch 1 "pressed" 0 "not pressed" ;
VAL_ 642 SCM_TimeGap_Select_Switch 3 "Invalid" 2 "TimeGap -" 1 "TimeGap+" 0 "Neutral" ;
VAL_ 642 SCM_ACC_Switch 3 "Invalid" 2 "ACC on/TJA" 1 "ACC Cancel/off" 0 "Neutral" ;
VAL_ 642 SCM_Res_Set_Switch 3 "Invalid" 2 "SET/-" 1 "RES/+" 0 "Neutral" ;
VAL_ 642 SCM_LKS_Switch_Invalid 1 "Invalid" 0 "valid" ;
VAL_ 642 SCM_TurnIndicator_Switch 3 "Invalid" 2 "Turn Right" 1 "Turn Left" 0 "OFF" ;
VAL_ 642 SCM_Flash_Switch 1 "ON" 0 "OFF" ;
VAL_ 642 SCM_Flash_Switch_Sts 1 "Invalid" 0 "Valid" ;
VAL_ 642 SCM_HiBeam_Switch 1 "ON" 0 "OFF" ;
VAL_ 642 SCM_HiBeam_Switch_Sts 1 "Invalid" 0 "Valid" ;
VAL_ 642 SCM_Fwiper_Mist_Switch 1 "ON" 0 "OFF" ;
VAL_ 642 SCM_FWiper_Switch 7 "Invalid" 6 "Reserved" 5 "Reserved" 4 "Auto-High" 3 "Auto-Low" 2 "HS Speed" 1 "LS speed" 0 "OFF" ;
VAL_ 642 SCM_RWiper_Switch 3 "Invalid" 2 "Rear Washer" 1 "Rear Wiper ON" 0 "OFF" ;
VAL_ 642 SCM_PRND_req 7 "Invalid" 6 "Reserved" 5 "Reserved" 4 "D" 3 "N" 2 "R" 1 "P" 0 "Default" ;
VAL_ 373 SAS_SteerWheelRotSpd 16383 "Invalid signal" ;
VAL_ 373 SAS_SteerWheelRotSpdStatus 1 "Invalid" 0 "Valid" ;
VAL_ 373 SAS_SASStsSnsr 1 "sensor value  valid" 0 "sensor value  Invalid" ;
VAL_ 373 EPS_SteeringTorqueValid 1 "Invalid" 0 "Vaild" ;
VAL_ 373 SAS_SASStsCal 1 "sensor calibrated" 0 "sensor not calibrated" ;
VAL_ 1429 VBU_BMS_PackSOH 127 "Invalid" 126 "Init" ;
VAL_ 1429 VBU_BMS_PackSOE 1023 "Invalid" 1022 "Init" ;
VAL_ 1429 VBU_BMS_TempDev_GBT32960 3 "三级故障" 2 "二级故障" 1 "一级故障" 0 "Not fault" ;
VAL_ 1429 VBU_BMS_TempOver_GBT32960 3 "三级故障" 2 "二级故障" 1 "一级故障" 0 "Not fault" ;
VAL_ 1429 VBU_BMS_CellVoltOver_GBT32960 3 "三级故障" 2 "二级故障" 1 "一级故障" 0 "Not fault" ;
VAL_ 1429 VBU_BMS_PackVoltOver_GBT32960 3 "三级故障" 2 "二级故障" 1 "一级故障" 0 "Not fault" ;
VAL_ 1429 VBU_BMS_CellVoltLow_GBT32960 3 "三级故障" 2 "二级故障" 1 "一级故障" 0 "Not fault" ;
VAL_ 1429 VBU_BMS_PackVoltLow_GBT32960 3 "三级故障" 2 "二级故障" 1 "一级故障" 0 "Not fault" ;
VAL_ 1429 VBU_BMS_BattOverCharge_GBT32960 3 "三级故障" 2 "二级故障" 1 "一级故障" 0 "Not fault" ;
VAL_ 1429 VBU_BMS_Iso_GBT32960 3 "三级故障" 2 "二级故障" 1 "一级故障" 0 "Not fault" ;
VAL_ 1429 VBU_BMS_SocSkip_GBT32960 1 "Fault" 0 "Not fault" ;
VAL_ 1429 VBU_BMS_BattMismatch_GBT32960 1 "Fault" 0 "Not fault" ;
VAL_ 1429 VBU_BMS_SocLow_GBT32960 3 "三级故障" 2 "二级故障" 1 "一级故障" 0 "Not fault" ;
VAL_ 1429 VBU_BMS_SocOverHigh_GBT32960 3 "三级故障" 2 "二级故障" 1 "一级故障" 0 "Not fault" ;
VAL_ 1429 VBU_BMS_CellVolDev_GBT32960 3 "三级故障" 2 "二级故障" 1 "一级故障" 0 "Not fault" ;
VAL_ 1429 VBU_BMS_ThermRunAway_GB38031 1 "Fault" 0 "Not fault" ;
VAL_ 1429 VBU_BMS_RegenOverCurr_GB38031 3 "三级故障" 2 "二级故障" 1 "一级故障" 0 "Not fault" ;
